VERSION "dbc-export 1 2026.26.6.5"

NS_ :

BS_:

BU_: ADSP APB APP APS APSB BB BMS CC CMP CMPD CP DAS DI DIF DIR DPB EPAS3P EPAS3S EPASTP EPASTS EPBL EPBR ESP EVSE FC GTW HCML HCMR HVP IBST ICR IDB LS OCS1P ODIN PARK PCS PCS2 PLG PM PMF PMR PNCD PTC RADC RCM RCM2 RCM3 RCU SCCM SCM SCS SDCR TAS TCU TCU2 TPMS TRCM UDS UI UIS UMC USM V2G VC VCBATT VCBATT0 VCBATT1 VCBATT2 VCCC VCFRONT VCFRONT1 VCFRONT2 VCLEFT VCRIGHT VCSEAT2L VCSEAT2R VCSEC VEH

BO_ 1000 EPBR_alertMatrix: 8 EPBR
 SG_ EPBR_matrixIndex M : 0|4@1+ (1,0) [0|15] "" Vector__XXX
 SG_ EPBR_a001_WatchdogReset m0 : 4|1@1+ (1,0) [0|1] "" Vector__XXX
 SG_ EPBR_a002_PowerLossReset m0 : 5|1@1+ (1,0) [0|1] "" Vector__XXX
 SG_ EPBR_a003_SWAssertion m0 : 6|1@1+ (1,0) [0|1] "" Vector__XXX
 SG_ EPBR_a005_CANTXError m0 : 8|1@1+ (1,0) [0|1] "" Vector__XXX
 SG_ EPBR_a006_CANTX_cyclicError m0 : 9|1@1+ (1,0) [0|1] "" Vector__XXX
 SG_ EPBR_a012_CPUReset m0 : 15|1@1+ (1,0) [0|1] "" Vector__XXX
 SG_ EPBR_a013_AlertManagerFault m0 : 16|1@1+ (1,0) [0|1] "" Vector__XXX
 SG_ EPBR_a015_NVMMError m0 : 18|1@1+ (1,0) [0|1] "" Vector__XXX
 SG_ EPBR_a016_NVMMRecordError m0 : 19|1@1+ (1,0) [0|1] "" Vector__XXX
 SG_ EPBR_a021_TaskSchedulerError m0 : 24|1@1+ (1,0) [0|1] "" Vector__XXX
 SG_ EPBR_a022_TaskInitError m0 : 25|1@1+ (1,0) [0|1] "" Vector__XXX
 SG_ EPBR_a029_CoreDump m0 : 32|1@1+ (1,0) [0|1] "" Vector__XXX
 SG_ EPBR_a030_ECULogUploadRequest m0 : 33|1@1+ (1,0) [0|1] "" Vector__XXX
 SG_ EPBR_a031_UDSActive m0 : 34|1@1+ (1,0) [0|1] "" Vector__XXX
 SG_ EPBR_a041_HighCPULoad m0 : 44|1@1+ (1,0) [0|1] "" Vector__XXX
 SG_ EPBR_a042_HighStackUsage m0 : 45|1@1+ (1,0) [0|1] "" Vector__XXX
 SG_ EPBR_a043_Task1msError m0 : 46|1@1+ (1,0) [0|1] "" Vector__XXX
 SG_ EPBR_a044_Task10msError m0 : 47|1@1+ (1,0) [0|1] "" Vector__XXX
 SG_ EPBR_a045_Task100msError m0 : 48|1@1+ (1,0) [0|1] "" Vector__XXX
 SG_ EPBR_a046_Task1000msError m0 : 49|1@1+ (1,0) [0|1] "" Vector__XXX
 SG_ EPBR_a057_HVP_MIA m0 : 60|1@1+ (1,0) [0|1] "" Vector__XXX
 SG_ EPBR_a058_inputRHighSyncDebug m0 : 61|1@1+ (1,0) [0|1] "" Vector__XXX
 SG_ EPBR_a059_inputResistanceHigh m0 : 62|1@1+ (1,0) [0|1] "" Vector__XXX
 SG_ EPBR_a060_engineeringBuild m0 : 63|1@1+ (1,0) [0|1] "" Vector__XXX
 SG_ EPBR_a061_XCPConnected m1 : 4|1@1+ (1,0) [0|1] "" Vector__XXX
 SG_ EPBR_a062_XCPWasConnected m1 : 5|1@1+ (1,0) [0|1] "" Vector__XXX
 SG_ EPBR_a063_SwitchFault m1 : 6|1@1+ (1,0) [0|1] "" Vector__XXX
 SG_ EPBR_a064_busSleepReqTimeout m1 : 7|1@1+ (1,0) [0|1] "" Vector__XXX
 SG_ EPBR_a081_APP_MIA m1 : 24|1@1+ (1,0) [0|1] "" Vector__XXX
 SG_ EPBR_a082_VCRIGHT_IPC_MIA m1 : 25|1@1+ (1,0) [0|1] "" Vector__XXX
 SG_ EPBR_a083_VCLEFT_IPC_MIA m1 : 26|1@1+ (1,0) [0|1] "" Vector__XXX
 SG_ EPBR_a084_TPMS_MIA m1 : 27|1@1+ (1,0) [0|1] "" Vector__XXX
 SG_ EPBR_a085_CCCM_MIA m1 : 28|1@1+ (1,0) [0|1] "" Vector__XXX
 SG_ EPBR_a086_VCBATT_MIA m1 : 29|1@1+ (1,0) [0|1] "" Vector__XXX
 SG_ EPBR_a087_DIREL_MIA m1 : 30|1@1+ (1,0) [0|1] "" Vector__XXX
 SG_ EPBR_a088_DIRER_MIA m1 : 31|1@1+ (1,0) [0|1] "" Vector__XXX
 SG_ EPBR_a089_IBST_MIA m1 : 32|1@1+ (1,0) [0|1] "" Vector__XXX
 SG_ EPBR_a090_APS_MIA m1 : 33|1@1+ (1,0) [0|1] "" Vector__XXX
 SG_ EPBR_a091_CMPD_MIA m1 : 34|1@1+ (1,0) [0|1] "" Vector__XXX
 SG_ EPBR_a092_VCSEATD_MIA m1 : 35|1@1+ (1,0) [0|1] "" Vector__XXX
 SG_ EPBR_a093_VCSEATP_MIA m1 : 36|1@1+ (1,0) [0|1] "" Vector__XXX
 SG_ EPBR_a094_EPAS3P_MIA m1 : 37|1@1+ (1,0) [0|1] "" Vector__XXX
 SG_ EPBR_a095_CHG_MIA m1 : 38|1@1+ (1,0) [0|1] "" Vector__XXX
 SG_ EPBR_a096_OCS1P_MIA m1 : 39|1@1+ (1,0) [0|1] "" Vector__XXX
 SG_ EPBR_a097_CMP_MIA m1 : 40|1@1+ (1,0) [0|1] "" Vector__XXX
 SG_ EPBR_a098_DIR_MIA m1 : 41|1@1+ (1,0) [0|1] "" Vector__XXX
 SG_ EPBR_a099_PARK_MIA m1 : 42|1@1+ (1,0) [0|1] "" Vector__XXX
 SG_ EPBR_a100_CANbus_MIA m1 : 43|1@1+ (1,0) [0|1] "" Vector__XXX
 SG_ EPBR_a101_PM_MIA m1 : 44|1@1+ (1,0) [0|1] "" Vector__XXX
 SG_ EPBR_a102_PTC_MIA m1 : 45|1@1+ (1,0) [0|1] "" Vector__XXX
 SG_ EPBR_a103_CP_MIA m1 : 46|1@1+ (1,0) [0|1] "" Vector__XXX
 SG_ EPBR_a104_DAS_MIA m1 : 47|1@1+ (1,0) [0|1] "" Vector__XXX
 SG_ EPBR_a105_TAS_MIA m1 : 48|1@1+ (1,0) [0|1] "" Vector__XXX
 SG_ EPBR_a106_PCS_MIA m1 : 49|1@1+ (1,0) [0|1] "" Vector__XXX
 SG_ EPBR_a107_BMS_MIA m1 : 50|1@1+ (1,0) [0|1] "" Vector__XXX
 SG_ EPBR_a108_DIF_MIA m1 : 51|1@1+ (1,0) [0|1] "" Vector__XXX
 SG_ EPBR_a109_RCM_MIA m1 : 52|1@1+ (1,0) [0|1] "" Vector__XXX
 SG_ EPBR_a110_GTW_MIA m1 : 53|1@1+ (1,0) [0|1] "" Vector__XXX
 SG_ EPBR_a111_EPBR_MIA m1 : 54|1@1+ (1,0) [0|1] "" Vector__XXX
 SG_ EPBR_a112_EPBL_MIA m1 : 55|1@1+ (1,0) [0|1] "" Vector__XXX
 SG_ EPBR_a113_UI_MIA m1 : 56|1@1+ (1,0) [0|1] "" Vector__XXX
 SG_ EPBR_a114_ESP_MIA m1 : 57|1@1+ (1,0) [0|1] "" Vector__XXX
 SG_ EPBR_a115_VCSEC_MIA m1 : 58|1@1+ (1,0) [0|1] "" Vector__XXX
 SG_ EPBR_a116_VCRIGHT_MIA m1 : 59|1@1+ (1,0) [0|1] "" Vector__XXX
 SG_ EPBR_a117_VCLEFT_MIA m1 : 60|1@1+ (1,0) [0|1] "" Vector__XXX
 SG_ EPBR_a118_VCFRONT_MIA m1 : 61|1@1+ (1,0) [0|1] "" Vector__XXX
 SG_ EPBR_a119_SCCM_MIA m1 : 62|1@1+ (1,0) [0|1] "" Vector__XXX
 SG_ EPBR_a120_DI_DRIVE_MIA m1 : 63|1@1+ (1,0) [0|1] "" Vector__XXX
 SG_ EPBR_a121_nDriveFault m2 : 4|1@1+ (1,0) [0|1] "" Vector__XXX
 SG_ EPBR_a122_Oc m2 : 5|1@1+ (1,0) [0|1] "" Vector__XXX
 SG_ EPBR_a123_Uc m2 : 6|1@1+ (1,0) [0|1] "" Vector__XXX
 SG_ EPBR_a124_calOutOfBounds m2 : 7|1@1+ (1,0) [0|1] "" Vector__XXX
 SG_ EPBR_a125_IdleVMismatch m2 : 8|1@1+ (1,0) [0|1] "" Vector__XXX
 SG_ EPBR_a126_MotorNVoltLow m2 : 9|1@1+ (1,0) [0|1] "" Vector__XXX
 SG_ EPBR_a127_MotorNVoltHigh m2 : 10|1@1+ (1,0) [0|1] "" Vector__XXX
 SG_ EPBR_a128_MotorPVoltHigh m2 : 11|1@1+ (1,0) [0|1] "" Vector__XXX
 SG_ EPBR_a129_ICR_MIA m2 : 12|1@1+ (1,0) [0|1] "" Vector__XXX
 SG_ EPBR_a130_BB_MIA m2 : 13|1@1+ (1,0) [0|1] "" Vector__XXX
 SG_ EPBR_a131_RCU_MIA m2 : 14|1@1+ (1,0) [0|1] "" Vector__XXX
 SG_ EPBR_a132_VCBATT1_MIA m2 : 15|1@1+ (1,0) [0|1] "" Vector__XXX
 SG_ EPBR_a133_VCBATT2_MIA m2 : 16|1@1+ (1,0) [0|1] "" Vector__XXX
 SG_ EPBR_a134_NvOv m2 : 17|1@1+ (1,0) [0|1] "" Vector__XXX
 SG_ EPBR_a135_NvUv m2 : 18|1@1+ (1,0) [0|1] "" Vector__XXX
 SG_ EPBR_a136_PvOv m2 : 19|1@1+ (1,0) [0|1] "" Vector__XXX
 SG_ EPBR_a137_PvUv m2 : 20|1@1+ (1,0) [0|1] "" Vector__XXX
 SG_ EPBR_a138_NvmDualFailure m2 : 21|1@1+ (1,0) [0|1] "" Vector__XXX
 SG_ EPBR_a139_NvmRedundancyLoss m2 : 22|1@1+ (1,0) [0|1] "" Vector__XXX
 SG_ EPBR_a140_NvmSlowWrite m2 : 23|1@1+ (1,0) [0|1] "" Vector__XXX
 SG_ EPBR_a141_invalidState m2 : 24|1@1+ (1,0) [0|1] "" Vector__XXX
 SG_ EPBR_a170_12vOv m2 : 53|1@1+ (1,0) [0|1] "" Vector__XXX
 SG_ EPBR_a171_12vUv m2 : 54|1@1+ (1,0) [0|1] "" Vector__XXX
 SG_ EPBR_a172_SPI_MIA m2 : 55|1@1+ (1,0) [0|1] "" Vector__XXX
 SG_ EPBR_a173_hiCurrentMissing m2 : 56|1@1+ (1,0) [0|1] "" Vector__XXX
 SG_ EPBR_a174_csmReleaseFailed m2 : 57|1@1+ (1,0) [0|1] "" Vector__XXX
 SG_ EPBR_a175_csmReleaseRetry m2 : 58|1@1+ (1,0) [0|1] "" Vector__XXX
 SG_ EPBR_a176_csmApplyFailed m2 : 59|1@1+ (1,0) [0|1] "" Vector__XXX
 SG_ EPBR_a177_csmApplyRetry m2 : 60|1@1+ (1,0) [0|1] "" Vector__XXX
 SG_ EPBR_a178_caliperStateUnknown m2 : 61|1@1+ (1,0) [0|1] "" Vector__XXX
 SG_ EPBR_a179_epbProblem m2 : 62|1@1+ (1,0) [0|1] "" Vector__XXX
 SG_ EPBR_a180_dynamicActive m2 : 63|1@1+ (1,0) [0|1] "" Vector__XXX
 SG_ EPBR_a181_TooSteepGradeToPark m3 : 4|1@1+ (1,0) [0|1] "" Vector__XXX
 SG_ EPBR_a182_OneEPBAppliedUnsecEnv m3 : 5|1@1+ (1,0) [0|1] "" Vector__XXX
 SG_ EPBR_a183_cdpNotAvailable m3 : 6|1@1+ (1,0) [0|1] "" Vector__XXX
 SG_ EPBR_a184_dynamicParkAbort m3 : 7|1@1+ (1,0) [0|1] "" Vector__XXX
 SG_ EPBR_a185_summonAborted m3 : 8|1@1+ (1,0) [0|1] "" Vector__XXX
 SG_ EPBR_a186_externalParkAbort m3 : 9|1@1+ (1,0) [0|1] "" Vector__XXX
 SG_ EPBR_a187_cdpDynamic m3 : 10|1@1+ (1,0) [0|1] "" Vector__XXX
 SG_ EPBR_a188_epbDynamic m3 : 11|1@1+ (1,0) [0|1] "" Vector__XXX
 SG_ EPBR_a189_epbDynamicParkCanceled m3 : 12|1@1+ (1,0) [0|1] "" Vector__XXX
 SG_ EPBR_a190_csmApplyDegraded m3 : 13|1@1+ (1,0) [0|1] "" Vector__XXX
 SG_ EPBR_a191_csmReleaseDegraded m3 : 14|1@1+ (1,0) [0|1] "" Vector__XXX
 SG_ EPBR_a195_parkForDriverIsLeaving m3 : 18|1@1+ (1,0) [0|1] "" Vector__XXX
 SG_ EPBR_a196_freeRollModeActive m3 : 19|1@1+ (1,0) [0|1] "" Vector__XXX
 SG_ EPBR_a197_freeRollModeAtSpeed m3 : 20|1@1+ (1,0) [0|1] "" Vector__XXX
 SG_ EPBR_a198_holdClampComplete m3 : 21|1@1+ (1,0) [0|1] "" Vector__XXX
 SG_ EPBR_a200_PmUnparkNotAllowed m3 : 23|1@1+ (1,0) [0|1] "" Vector__XXX
 SG_ EPBR_a202_remoteEpbConfigIncompa m3 : 25|1@1+ (1,0) [0|1] "" Vector__XXX
 SG_ EPBR_a203_hwBrakeTypeMismatch m3 : 26|1@1+ (1,0) [0|1] "" Vector__XXX
 SG_ EPBR_a210_parkForDriverIsLeaving m3 : 33|1@1+ (1,0) [0|1] "" Vector__XXX
 SG_ EPBR_a216_SPI_MIA_debugData1 m3 : 39|1@1+ (1,0) [0|1] "" Vector__XXX
 SG_ EPBR_a217_SPI_MIA_debugData2 m3 : 40|1@1+ (1,0) [0|1] "" Vector__XXX
 SG_ EPBR_a225_epbActiveDecel m3 : 48|1@1+ (1,0) [0|1] "" Vector__XXX
 SG_ EPBR_a241_diOutputLocked m4 : 4|1@1+ (1,0) [0|1] "" Vector__XXX
 SG_ EPBR_a242_hvOutputLocked m4 : 5|1@1+ (1,0) [0|1] "" Vector__XXX
 SG_ EPBR_a243_bdwUnavailable m4 : 6|1@1+ (1,0) [0|1] "" Vector__XXX
 SG_ EPBR_a244_WinchModeActive m4 : 7|1@1+ (1,0) [0|1] "" Vector__XXX
 SG_ EPBR_a245_serviceModeActive m4 : 8|1@1+ (1,0) [0|1] "" Vector__XXX
 SG_ EPBR_a246_idleFaultApply m4 : 9|1@1+ (1,0) [0|1] "" Vector__XXX
 SG_ EPBR_a247_csmDynamicApplyRetry m4 : 10|1@1+ (1,0) [0|1] "" Vector__XXX
 SG_ EPBR_a248_csmDynamicApplyFailed m4 : 11|1@1+ (1,0) [0|1] "" Vector__XXX
 SG_ EPBR_a249_idleFaultRelease m4 : 12|1@1+ (1,0) [0|1] "" Vector__XXX
 SG_ EPBR_a250_WinchModeCanceled m4 : 13|1@1+ (1,0) [0|1] "" Vector__XXX
 SG_ EPBR_a251_currentVarianceHigh m4 : 14|1@1+ (1,0) [0|1] "" Vector__XXX
 SG_ EPBR_a252_winchModePending m4 : 15|1@1+ (1,0) [0|1] "" Vector__XXX
 SG_ EPBR_a253_esmReleaseBlocked m4 : 16|1@1+ (1,0) [0|1] "" Vector__XXX
 SG_ EPBR_a254_showStalkParkButtonFau m4 : 17|1@1+ (1,0) [0|1] "" Vector__XXX
 SG_ EPBR_a256_epbSystemApply m4 : 19|1@1+ (1,0) [0|1] "" Vector__XXX
 SG_ EPBR_a261_winchModeWithoutSteeri m4 : 24|1@1+ (1,0) [0|1] "" Vector__XXX
 SG_ EPBR_a262_cannotPrepareWinchMode m4 : 25|1@1+ (1,0) [0|1] "" Vector__XXX
 SG_ EPBR_a263_epbRecoveryPark m4 : 26|1@1+ (1,0) [0|1] "" Vector__XXX
 SG_ EPBR_a264_winchModeDeactivated m4 : 27|1@1+ (1,0) [0|1] "" Vector__XXX
 SG_ EPBR_a272_vhclPwrStateMsmtch m4 : 35|1@1+ (1,0) [0|1] "" Vector__XXX
 SG_ EPBR_a300_leftRightConfusion m4 : 63|1@1+ (1,0) [0|1] "" Vector__XXX
 SG_ EPBR_a301_oocSpeedViolation m5 : 4|1@1+ (1,0) [0|1] "" Vector__XXX
 SG_ EPBR_a302_csmLongRelease m5 : 5|1@1+ (1,0) [0|1] "" Vector__XXX
 SG_ EPBR_a303_clampingOccuredEarly m5 : 6|1@1+ (1,0) [0|1] "" Vector__XXX
 SG_ EPBR_a304_rearSeatControllerEFus m5 : 7|1@1+ (1,0) [0|1] "" Vector__XXX
 SG_ EPBR_a305_premiumAmpEFuseTrip m5 : 8|1@1+ (1,0) [0|1] "" Vector__XXX
 SG_ EPBR_a330_parkForApIsLeaving m5 : 33|1@1+ (1,0) [0|1] "" Vector__XXX
 SG_ EPBR_a350_ensOutOfRange m5 : 53|1@1+ (1,0) [0|1] "" Vector__XXX
 SG_ EPBR_a352_audioCurrentSpikeData m5 : 55|1@1+ (1,0) [0|1] "" Vector__XXX
 SG_ EPBR_a353_missingSpeedUnableToPa m5 : 56|1@1+ (1,0) [0|1] "" Vector__XXX
 SG_ EPBR_a354_parkedForLowBrakeFluid m5 : 57|1@1+ (1,0) [0|1] "" Vector__XXX
 SG_ EPBR_a355_brakeHwAndEpbHwMismatc m5 : 58|1@1+ (1,0) [0|1] "" Vector__XXX
 SG_ EPBR_a356_parkingForStationaryDe m5 : 59|1@1+ (1,0) [0|1] "" Vector__XXX
 SG_ EPBR_a357_brakesTooHotForSlope m5 : 60|1@1+ (1,0) [0|1] "" Vector__XXX
 SG_ EPBR_a358_brakesTooHotForSlopeWi m5 : 61|1@1+ (1,0) [0|1] "" Vector__XXX
 SG_ EPBR_a359_seat2RControllerTrip m5 : 62|1@1+ (1,0) [0|1] "" Vector__XXX
 SG_ EPBR_a360_ibstBrakeSwitchInvalid m5 : 63|1@1+ (1,0) [0|1] "" Vector__XXX
 SG_ EPBR_a361_espBrakeSwitchInvalid m6 : 4|1@1+ (1,0) [0|1] "" Vector__XXX
 SG_ EPBR_a362_ibstPressedEspNotPress m6 : 5|1@1+ (1,0) [0|1] "" Vector__XXX
 SG_ EPBR_a363_ibstNotPressedEspPress m6 : 6|1@1+ (1,0) [0|1] "" Vector__XXX
 SG_ EPBR_a364_espMasterCylCompOverTh m6 : 7|1@1+ (1,0) [0|1] "" Vector__XXX
 SG_ EPBR_a365_TooSteepToParkWithTrai m6 : 8|1@1+ (1,0) [0|1] "" Vector__XXX
 SG_ EPBR_a366_TooSteepToParkWithTrai m6 : 9|1@1+ (1,0) [0|1] "" Vector__XXX
 SG_ EPBR_a370_imposterDetected m6 : 13|1@1+ (1,0) [0|1] "" Vector__XXX

BO_ 2024 EPBR_info: 8 EPBR
 SG_ EPBR_infoIndex M : 0|8@1+ (1,0) [0|255] "" Vector__XXX
 SG_ EPBR_infoBuildType m10 : 8|3@1+ (1,0) [0|7] "" Vector__XXX
 SG_ EPBR_infoBuildConfigId m10 : 16|16@1+ (1,0) [0|65535] "" Vector__XXX
 SG_ EPBR_infoHardwareId m10 : 32|16@1+ (1,0) [0|65535] "" Vector__XXX
 SG_ EPBR_infoComponentId m10 : 48|16@1+ (1,0) [0|65535] "" Vector__XXX
 SG_ EPBR_infoPcbaId m11 : 8|8@1+ (1,0) [0|255] "" Vector__XXX
 SG_ EPBR_infoAssemblyId m11 : 16|8@1+ (1,0) [0|254] "" Vector__XXX
 SG_ EPBR_infoUsageId m11 : 24|16@1+ (1,0) [0|65535] "" Vector__XXX
 SG_ EPBR_infoSubUsageId m11 : 40|16@1+ (1,0) [0|65535] "" Vector__XXX
 SG_ EPBR_infoAppCrc m13 : 8|32@1+ (1,0) [0|4294967295] "" Vector__XXX
 SG_ EPBR_infoAppGitHash m17 : 8|56@1+ (1,0) [0|7.20575940379e+16] "" Vector__XXX
 SG_ EPBR_infoBootGitHash m18 : 8|56@1+ (1,0) [0|7.20575940379e+16] "" Vector__XXX
 SG_ EPBR_infoPlatformType m19 : 8|8@1+ (1,0) [0|255] "" Vector__XXX
 SG_ EPBR_infoBootUdsProtoVersion m20 : 8|16@1+ (1,0) [0|65535] "" Vector__XXX
 SG_ EPBR_infoBootCrc m20 : 24|32@1+ (1,0) [0|4294967295] "" Vector__XXX

BO_ 552 EPBR_internalStatus: 8 EPBR
 SG_ EPBR_unitStatus : 0|5@1+ (1,0) [0|31] "" Vector__XXX
 SG_ EPBR_unitFaultStatus : 5|2@1+ (1,0) [0|3] "" Vector__XXX
 SG_ EPBR_summonState : 8|3@1+ (1,0) [0|7] "" Vector__XXX
 SG_ EPBR_disconnected : 11|1@1+ (1,0) [0|1] "" Vector__XXX
 SG_ EPBR_pistonTouchingRotor : 12|1@1+ (1,0) [0|1] "" Vector__XXX
 SG_ EPBR_csmFaultReason : 13|5@1+ (1,0) [0|31] "" Vector__XXX
 SG_ EPBR_esmOperationTrigger : 18|6@1+ (1,0) [0|63] "" Vector__XXX
 SG_ EPBR_summonFaultReason : 24|5@1+ (1,0) [0|31] "" Vector__XXX
 SG_ EPBR_localServiceModeActive : 29|1@1+ (1,0) [0|1] "" Vector__XXX
 SG_ EPBR_localCdpState : 30|2@1+ (1,0) [0|3] "" Vector__XXX
 SG_ EPBR_chimeRequestLocal : 33|3@1+ (1,0) [0|7] "" Vector__XXX
 SG_ EPBR_telltaleLocal : 39|3@1+ (1,0) [0|6] "" Vector__XXX
 SG_ EPBR_driverIsLeavingLocal : 42|1@1+ (1,0) [0|1] "" Vector__XXX
 SG_ EPBR_driverIsLeavingAnySpeedLoca : 43|1@1+ (1,0) [0|1] "" Vector__XXX
 SG_ EPBR_internalCDPRequest : 44|1@1+ (1,0) [0|1] "" Vector__XXX
 SG_ EPBR_esmSpeedClass : 45|3@1+ (1,0) [0|7] "" Vector__XXX
 SG_ EPBR_learnedEpbConfig : 48|4@1+ (1,0) [0|15] "" Vector__XXX
 SG_ EPBR_internalStatusCounter : 52|4@1+ (1,0) [0|15] "" Vector__XXX
 SG_ EPBR_internalStatusChecksum : 56|8@1+ (1,0) [0|255] "" Vector__XXX

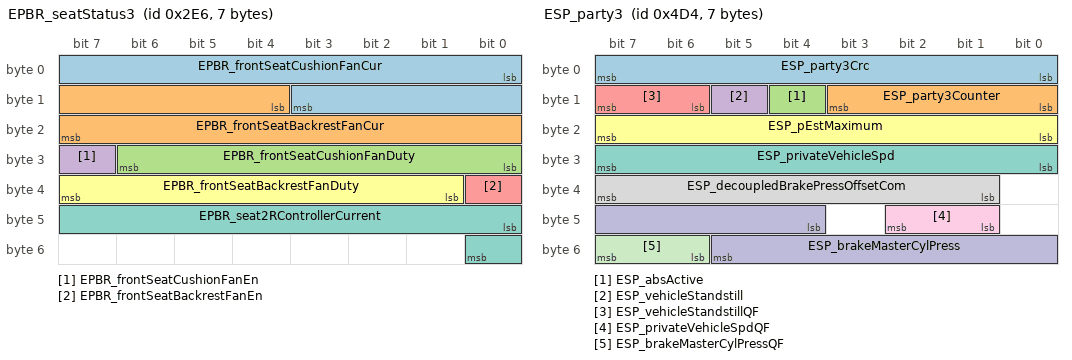
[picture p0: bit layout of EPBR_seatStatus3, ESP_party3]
BO_ 742 EPBR_seatStatus3: 7 EPBR
 SG_ EPBR_frontSeatCushionFanCur : 0|12@1+ (0.01,0) [0|40.95] "A" Vector__XXX
 SG_ EPBR_frontSeatBackrestFanCur : 12|12@1+ (0.01,0) [0|40.95] "A" Vector__XXX
 SG_ EPBR_frontSeatCushionFanDuty : 24|7@1+ (1,0) [0|100] "%" Vector__XXX
 SG_ EPBR_frontSeatCushionFanEn : 31|1@1+ (1,0) [0|1] "" Vector__XXX
 SG_ EPBR_frontSeatBackrestFanEn : 32|1@1+ (1,0) [0|1] "" Vector__XXX
 SG_ EPBR_frontSeatBackrestFanDuty : 33|7@1+ (1,0) [0|100] "%" Vector__XXX
 SG_ EPBR_seat2RControllerCurrent : 40|9@1+ (0.2,0) [0|102] "A" Vector__XXX

BO_ 744 EPBR_status: 8 EPBR
 SG_ EPBR_systemStatus : 0|4@1+ (1,0) [0|15] "" Vector__XXX
 SG_ EPBR_freeRollModeStatus : 4|2@1+ (1,0) [0|3] "" Vector__XXX
 SG_ EPBR_driverIsLeaving : 6|1@1+ (1,0) [0|1] "" Vector__XXX
 SG_ EPBR_driverIsLeavingAnySpeed : 7|1@1+ (1,0) [0|1] "" Vector__XXX
 SG_ EPBR_systemCdpAvailable : 8|1@1+ (1,0) [0|1] "" Vector__XXX
 SG_ EPBR_chimeRequest : 9|3@1+ (1,0) [0|7] "" Vector__XXX
 SG_ EPBR_telltale : 12|3@1+ (1,0) [0|6] "" Vector__XXX
 SG_ EPBR_audioCurrentSpikeDetected : 15|1@1+ (1,0) [0|1] "" Vector__XXX
 SG_ EPBR_redundantBrakingEnabled : 16|1@1+ (1,0) [0|1] "" Vector__XXX
 SG_ EPBR_summonEnabled : 17|1@1+ (1,0) [0|1] "" Vector__XXX
 SG_ EPBR_brakeLight : 18|1@1+ (1,0) [0|1] "" Vector__XXX
 SG_ EPBR_epbConfigMismatch : 19|1@1+ (1,0) [0|1] "" Vector__XXX
 SG_ EPBR_brakeConfirmedPressed : 20|1@1+ (1,0) [0|1] "" Vector__XXX
 SG_ EPBR_requestUserConfirmation : 21|1@1+ (1,0) [0|1] "" Vector__XXX
 SG_ EPBR_uiWinchModeMiscBlocking : 22|1@1+ (1,0) [0|1] "" Vector__XXX
 SG_ EPBR_winchModeActive : 23|1@1+ (1,0) [0|1] "" Vector__XXX
 SG_ EPBR_updateMode : 24|1@1+ (1,0) [0|1] "" Vector__XXX
 SG_ EPBR_winchModePermissive : 25|1@1+ (1,0) [0|1] "" Vector__XXX
 SG_ EPBR_winchModePending : 26|1@1+ (1,0) [0|1] "" Vector__XXX
 SG_ EPBR_cdpRequest : 27|1@1+ (1,0) [0|1] "" Vector__XXX
 SG_ EPBR_uiParkAvailable : 28|2@1+ (1,0) [0|3] "" Vector__XXX
 SG_ EPBR_brakeDiscWipeRequest : 30|2@1+ (1,0) [0|2] "" Vector__XXX
 SG_ EPBR_showUiGearShifter : 32|1@1+ (1,0) [0|1] "" Vector__XXX
 SG_ EPBR_uiWinchModeLvStatus : 33|2@1+ (1,0) [0|3] "" Vector__XXX
 SG_ EPBR_contactorCycleNotNeededForW : 35|1@1+ (1,0) [0|1] "" Vector__XXX
 SG_ EPBR_autonomyBehavior : 43|2@1+ (1,0) [0|3] "" Vector__XXX
 SG_ EPBR_showStalkFaultedOnUi : 45|1@1+ (1,0) [0|1] "" Vector__XXX
 SG_ EPBR_espPowerRequest : 46|1@1+ (1,0) [0|1] "" Vector__XXX
 SG_ EPBR_okToPark : 47|1@1+ (1,0) [0|1] "" Vector__XXX
 SG_ EPBR_hornRequest : 48|1@1+ (1,0) [0|1] "" Vector__XXX
 SG_ EPBR_winchModeAvailable : 49|1@1+ (1,0) [0|1] "" Vector__XXX
 SG_ EPBR_bothDisconnected : 50|1@1+ (1,0) [0|1] "" Vector__XXX
 SG_ EPBR_blockDrive : 51|1@1+ (1,0) [0|1] "" Vector__XXX
 SG_ EPBR_statusCounter : 52|4@1+ (1,0) [0|15] "" Vector__XXX
 SG_ EPBR_statusChecksum : 56|8@1+ (1,0) [0|255] "" Vector__XXX

BO_ 1575 EPBR_udsResponse: 8 EPBR
 SG_ EPBR_udsResponseData_H : 7|32@0+ (1,0) [0|4294967295] "" Vector__XXX
 SG_ EPBR_udsResponseData_L : 39|32@0+ (1,0) [0|4294967295] "" Vector__XXX

BO_ 981 ESP_alertMatrix: 8 ESP
 SG_ ESP_matrixIndex M : 0|4@1+ (1,0) [0|15] "" Vector__XXX
 SG_ ESP_a001_ecuGenericFault m0 : 4|1@1+ (1,0) [0|1] "" Vector__XXX
 SG_ ESP_a002_valvesGenericFault m0 : 5|1@1+ (1,0) [0|1] "" Vector__XXX
 SG_ ESP_a003_outletValvesFault m0 : 6|1@1+ (1,0) [0|1] "" Vector__XXX
 SG_ ESP_a004_inletValvesFault m0 : 7|1@1+ (1,0) [0|1] "" Vector__XXX
 SG_ ESP_a005_HSVValvesFault m0 : 8|1@1+ (1,0) [0|1] "" Vector__XXX
 SG_ ESP_a006_USVValvesFault m0 : 9|1@1+ (1,0) [0|1] "" Vector__XXX
 SG_ ESP_a007_pumpMotorFault m0 : 10|1@1+ (1,0) [0|1] "" Vector__XXX
 SG_ ESP_a008_pumpMotor12VsupplyLow m0 : 11|1@1+ (1,0) [0|1] "" Vector__XXX
 SG_ ESP_a009_12VHardUndervoltage m0 : 12|1@1+ (1,0) [0|1] "" Vector__XXX
 SG_ ESP_a010_12VUndervoltage m0 : 13|1@1+ (1,0) [0|1] "" Vector__XXX
 SG_ ESP_a011_12VSystemUndervoltage m0 : 14|1@1+ (1,0) [0|1] "" Vector__XXX
 SG_ ESP_a012_netUndervoltage m0 : 15|1@1+ (1,0) [0|1] "" Vector__XXX
 SG_ ESP_a013_valveRelayUndervoltage m0 : 16|1@1+ (1,0) [0|1] "" Vector__XXX
 SG_ ESP_a014_WSSSupplyUndervoltage m0 : 17|1@1+ (1,0) [0|1] "" Vector__XXX
 SG_ ESP_a015_12VSupplyOvervoltage m0 : 18|1@1+ (1,0) [0|1] "" Vector__XXX
 SG_ ESP_a016_12VSystemOvervoltage m0 : 19|1@1+ (1,0) [0|1] "" Vector__XXX
 SG_ ESP_a017_netOvervoltage m0 : 20|1@1+ (1,0) [0|1] "" Vector__XXX
 SG_ ESP_a018_WSSSignFrontAxle m0 : 21|1@1+ (1,0) [0|1] "" Vector__XXX
 SG_ ESP_a019_WSSSignRearAxle m0 : 22|1@1+ (1,0) [0|1] "" Vector__XXX
 SG_ ESP_a020_WSSGenericTempFault m0 : 23|1@1+ (1,0) [0|1] "" Vector__XXX
 SG_ ESP_a021_WSSGeneralVDiffFault m0 : 24|1@1+ (1,0) [0|1] "" Vector__XXX
 SG_ ESP_a022_WSSDirectionFault m0 : 25|1@1+ (1,0) [0|1] "" Vector__XXX
 SG_ ESP_a023_WSSSeveralSuspected m0 : 26|1@1+ (1,0) [0|1] "" Vector__XXX
 SG_ ESP_a024_WSSReverseCurrent m0 : 27|1@1+ (1,0) [0|1] "" Vector__XXX
 SG_ ESP_a025_FrLWSSOpenOrShortToGnd m0 : 28|1@1+ (1,0) [0|1] "" Vector__XXX
 SG_ ESP_a026_FrLWSSShortTo12V m0 : 29|1@1+ (1,0) [0|1] "" Vector__XXX
 SG_ ESP_a027_FrLWSSLineInterruption m0 : 30|1@1+ (1,0) [0|1] "" Vector__XXX
 SG_ ESP_a028_FrLWSSMaxSpeedExceeded m0 : 31|1@1+ (1,0) [0|1] "" Vector__XXX
 SG_ ESP_a029_FrLWSSTooManyPulses m0 : 32|1@1+ (1,0) [0|1] "" Vector__XXX
 SG_ ESP_a030_FrLWSSLostSignal m0 : 33|1@1+ (1,0) [0|1] "" Vector__XXX
 SG_ ESP_a031_FrLWSSNoPulsesDetected m0 : 34|1@1+ (1,0) [0|1] "" Vector__XXX
 SG_ ESP_a032_FrLWSSWrongSensorType m0 : 35|1@1+ (1,0) [0|1] "" Vector__XXX
 SG_ ESP_a033_FrLWSSSignalNoise m0 : 36|1@1+ (1,0) [0|1] "" Vector__XXX
 SG_ ESP_a034_FrLWSSVDiffFault m0 : 37|1@1+ (1,0) [0|1] "" Vector__XXX
 SG_ ESP_a035_FrLWSSDirectionFault m0 : 38|1@1+ (1,0) [0|1] "" Vector__XXX
 SG_ ESP_a036_FrLWSSLargeAirGap m0 : 39|1@1+ (1,0) [0|1] "" Vector__XXX
 SG_ ESP_a037_FrLWSSSupplyShortToGnd m0 : 40|1@1+ (1,0) [0|1] "" Vector__XXX
 SG_ ESP_a038_FrLWSSGeneralFault m0 : 41|1@1+ (1,0) [0|1] "" Vector__XXX
 SG_ ESP_a039_FrRWSSOpenOrShortToGnd m0 : 42|1@1+ (1,0) [0|1] "" Vector__XXX
 SG_ ESP_a040_FrRWSSShortTo12V m0 : 43|1@1+ (1,0) [0|1] "" Vector__XXX
 SG_ ESP_a041_FrRWSSLineInterruption m0 : 44|1@1+ (1,0) [0|1] "" Vector__XXX
 SG_ ESP_a042_FrRWSSMaxSpeedExceeded m0 : 45|1@1+ (1,0) [0|1] "" Vector__XXX
 SG_ ESP_a043_FrRWSSTooManyPulses m0 : 46|1@1+ (1,0) [0|1] "" Vector__XXX
 SG_ ESP_a044_FrRWSSLostSignal m0 : 47|1@1+ (1,0) [0|1] "" Vector__XXX
 SG_ ESP_a045_FrRWSSNoPulsesDetected m0 : 48|1@1+ (1,0) [0|1] "" Vector__XXX
 SG_ ESP_a046_FrRWSSWrongSensorType m0 : 49|1@1+ (1,0) [0|1] "" Vector__XXX
 SG_ ESP_a047_FrRWSSSignalNoise m0 : 50|1@1+ (1,0) [0|1] "" Vector__XXX
 SG_ ESP_a048_FrRWSSVDiffFault m0 : 51|1@1+ (1,0) [0|1] "" Vector__XXX
 SG_ ESP_a049_FrRWSSDirectionFault m0 : 52|1@1+ (1,0) [0|1] "" Vector__XXX
 SG_ ESP_a050_FrRWSSLargeAirGap m0 : 53|1@1+ (1,0) [0|1] "" Vector__XXX
 SG_ ESP_a051_FrRWSSSupplyShortToGnd m0 : 54|1@1+ (1,0) [0|1] "" Vector__XXX
 SG_ ESP_a052_FrRWSSGeneralFault m0 : 55|1@1+ (1,0) [0|1] "" Vector__XXX
 SG_ ESP_a053_ReLWSSOpenOrShortToGnd m0 : 56|1@1+ (1,0) [0|1] "" Vector__XXX
 SG_ ESP_a054_ReLWSSShortTo12V m0 : 57|1@1+ (1,0) [0|1] "" Vector__XXX
 SG_ ESP_a055_ReLWSSLineInterruption m0 : 58|1@1+ (1,0) [0|1] "" Vector__XXX
 SG_ ESP_a056_ReLWSSMaxSpeedExceeded m0 : 59|1@1+ (1,0) [0|1] "" Vector__XXX
 SG_ ESP_a057_ReLWSSTooManyPulses m0 : 60|1@1+ (1,0) [0|1] "" Vector__XXX
 SG_ ESP_a058_ReLWSSLostSignal m0 : 61|1@1+ (1,0) [0|1] "" Vector__XXX
 SG_ ESP_a059_ReLWSSNoPulsesDetected m0 : 62|1@1+ (1,0) [0|1] "" Vector__XXX
 SG_ ESP_a060_ReLWSSWrongSensorType m0 : 63|1@1+ (1,0) [0|1] "" Vector__XXX
 SG_ ESP_a061_ReLWSSSignalNoise m1 : 4|1@1+ (1,0) [0|1] "" Vector__XXX
 SG_ ESP_a062_ReLWSSVDiffFault m1 : 5|1@1+ (1,0) [0|1] "" Vector__XXX
 SG_ ESP_a063_ReLWSSDirectionFault m1 : 6|1@1+ (1,0) [0|1] "" Vector__XXX
 SG_ ESP_a064_ReLWSSLargeAirGap m1 : 7|1@1+ (1,0) [0|1] "" Vector__XXX
 SG_ ESP_a065_ReLWSSSupplyShortToGnd m1 : 8|1@1+ (1,0) [0|1] "" Vector__XXX
 SG_ ESP_a066_ReLWSSGeneralFault m1 : 9|1@1+ (1,0) [0|1] "" Vector__XXX
 SG_ ESP_a067_ReRWSSOpenOrShortToGnd m1 : 10|1@1+ (1,0) [0|1] "" Vector__XXX
 SG_ ESP_a068_ReRWSSShortTo12V m1 : 11|1@1+ (1,0) [0|1] "" Vector__XXX
 SG_ ESP_a069_ReRWSSLineInterruption m1 : 12|1@1+ (1,0) [0|1] "" Vector__XXX
 SG_ ESP_a070_ReRWSSMaxSpeedExceeded m1 : 13|1@1+ (1,0) [0|1] "" Vector__XXX
 SG_ ESP_a071_ReRWSSTooManyPulses m1 : 14|1@1+ (1,0) [0|1] "" Vector__XXX
 SG_ ESP_a072_ReRWSSLostSignal m1 : 15|1@1+ (1,0) [0|1] "" Vector__XXX
 SG_ ESP_a073_ReRWSSNoPulsesDetected m1 : 16|1@1+ (1,0) [0|1] "" Vector__XXX
 SG_ ESP_a074_ReRWSSWrongSensorType m1 : 17|1@1+ (1,0) [0|1] "" Vector__XXX
 SG_ ESP_a075_ReRWSSSignalNoise m1 : 18|1@1+ (1,0) [0|1] "" Vector__XXX
 SG_ ESP_a076_ReRWSSVDiffFault m1 : 19|1@1+ (1,0) [0|1] "" Vector__XXX
 SG_ ESP_a077_ReRWSSDirectionFault m1 : 20|1@1+ (1,0) [0|1] "" Vector__XXX
 SG_ ESP_a078_ReRWSSLargeAirGap m1 : 21|1@1+ (1,0) [0|1] "" Vector__XXX
 SG_ ESP_a079_ReRWSSSupplyShortToGnd m1 : 22|1@1+ (1,0) [0|1] "" Vector__XXX
 SG_ ESP_a080_ReRWSSGeneralFault m1 : 23|1@1+ (1,0) [0|1] "" Vector__XXX
 SG_ ESP_a081_PressureSensorShort m1 : 24|1@1+ (1,0) [0|1] "" Vector__XXX
 SG_ ESP_a082_PMCSensorOffsetHigh m1 : 25|1@1+ (1,0) [0|1] "" Vector__XXX
 SG_ ESP_a083_PMCSensorFault m1 : 26|1@1+ (1,0) [0|1] "" Vector__XXX
 SG_ ESP_a084_BrakeFluidReservoirLow m1 : 27|1@1+ (1,0) [0|1] "" Vector__XXX
 SG_ ESP_a085_BrakeSwitchStuckHigh m1 : 28|1@1+ (1,0) [0|1] "" Vector__XXX
 SG_ ESP_a086_BrakeSwitchImplausible1 m1 : 29|1@1+ (1,0) [0|1] "" Vector__XXX
 SG_ ESP_a087_BrakeSwitchImplausible3 m1 : 30|1@1+ (1,0) [0|1] "" Vector__XXX
 SG_ ESP_a088_absContinuousControl m1 : 31|1@1+ (1,0) [0|1] "" Vector__XXX
 SG_ ESP_a089_absNoPressureIncrease m1 : 32|1@1+ (1,0) [0|1] "" Vector__XXX
 SG_ ESP_a090_vdcContinuousControl m1 : 33|1@1+ (1,0) [0|1] "" Vector__XXX
 SG_ ESP_a091_CANUndervoltage m1 : 34|1@1+ (1,0) [0|1] "" Vector__XXX
 SG_ ESP_a092_CANOvervoltage m1 : 35|1@1+ (1,0) [0|1] "" Vector__XXX
 SG_ ESP_a093_partyBusOff m1 : 36|1@1+ (1,0) [0|1] "" Vector__XXX
 SG_ ESP_a094_partyBusPassive m1 : 37|1@1+ (1,0) [0|1] "" Vector__XXX
 SG_ ESP_a095_chassisBusOff m1 : 38|1@1+ (1,0) [0|1] "" Vector__XXX
 SG_ ESP_a096_chassisBusPassive m1 : 39|1@1+ (1,0) [0|1] "" Vector__XXX
 SG_ ESP_a097_tcsRefSpeedNotInit m1 : 40|1@1+ (1,0) [0|1] "" Vector__XXX
 SG_ ESP_a098_vdcRefSpeedNotInit m1 : 41|1@1+ (1,0) [0|1] "" Vector__XXX
 SG_ ESP_a099_brakeTempModelOverheat m1 : 42|1@1+ (1,0) [0|1] "" Vector__XXX
 SG_ ESP_a100_brakeTempModelDisabled m1 : 43|1@1+ (1,0) [0|1] "" Vector__XXX
 SG_ ESP_a101_ebdFault m1 : 44|1@1+ (1,0) [0|1] "" Vector__XXX
 SG_ ESP_a102_absFault m1 : 45|1@1+ (1,0) [0|1] "" Vector__XXX
 SG_ ESP_a103_stabilityControlFault m1 : 46|1@1+ (1,0) [0|1] "" Vector__XXX
 SG_ ESP_a104_hbcEnabled m1 : 47|1@1+ (1,0) [0|1] "" Vector__XXX
 SG_ ESP_a105_ebrFault m1 : 48|1@1+ (1,0) [0|1] "" Vector__XXX
 SG_ ESP_a106_vdcActuatorFault m1 : 49|1@1+ (1,0) [0|1] "" Vector__XXX
 SG_ ESP_a107_reserved107 m1 : 50|1@1+ (1,0) [0|1] "" Vector__XXX
 SG_ ESP_a108_reserved108 m1 : 51|1@1+ (1,0) [0|1] "" Vector__XXX
 SG_ ESP_a109_reserved109 m1 : 52|1@1+ (1,0) [0|1] "" Vector__XXX
 SG_ ESP_a110_rollerBenchActive m1 : 53|1@1+ (1,0) [0|1] "" Vector__XXX
 SG_ ESP_a111_absActive m1 : 54|1@1+ (1,0) [0|1] "" Vector__XXX
 SG_ ESP_a112_espActive m1 : 55|1@1+ (1,0) [0|1] "" Vector__XXX
 SG_ ESP_a113_btcActive m1 : 56|1@1+ (1,0) [0|1] "" Vector__XXX
 SG_ ESP_a114_tvdcActive m1 : 57|1@1+ (1,0) [0|1] "" Vector__XXX
 SG_ ESP_a115_ebdActive m1 : 58|1@1+ (1,0) [0|1] "" Vector__XXX
 SG_ ESP_a116_tsmActive m1 : 59|1@1+ (1,0) [0|1] "" Vector__XXX
 SG_ ESP_a117_hbaActive m1 : 60|1@1+ (1,0) [0|1] "" Vector__XXX
 SG_ ESP_a118_hfcActive m1 : 61|1@1+ (1,0) [0|1] "" Vector__XXX
 SG_ ESP_a119_hbbActive m1 : 62|1@1+ (1,0) [0|1] "" Vector__XXX
 SG_ ESP_a120_rmiActive m1 : 63|1@1+ (1,0) [0|1] "" Vector__XXX
 SG_ ESP_a121_regenTcActive m2 : 4|1@1+ (1,0) [0|1] "" Vector__XXX
 SG_ ESP_a122_bdwActive m2 : 5|1@1+ (1,0) [0|1] "" Vector__XXX
 SG_ ESP_a123_ebrActive m2 : 6|1@1+ (1,0) [0|1] "" Vector__XXX
 SG_ ESP_a124_ebrSkidActive m2 : 7|1@1+ (1,0) [0|1] "" Vector__XXX
 SG_ ESP_a125_reserved125 m2 : 8|1@1+ (1,0) [0|1] "" Vector__XXX
 SG_ ESP_a126_reserved126 m2 : 9|1@1+ (1,0) [0|1] "" Vector__XXX
 SG_ ESP_a127_reserved127 m2 : 10|1@1+ (1,0) [0|1] "" Vector__XXX
 SG_ ESP_a128_reserved128 m2 : 11|1@1+ (1,0) [0|1] "" Vector__XXX
 SG_ ESP_a129_reserved129 m2 : 12|1@1+ (1,0) [0|1] "" Vector__XXX
 SG_ ESP_a130_EPAS3PsysStatusTimeout m2 : 13|1@1+ (1,0) [0|1] "" Vector__XXX
 SG_ ESP_a131_EPAS3PsysStatusDLC m2 : 14|1@1+ (1,0) [0|1] "" Vector__XXX
 SG_ ESP_a132_EPAS3PsysStatusChecksum m2 : 15|1@1+ (1,0) [0|1] "" Vector__XXX
 SG_ ESP_a133_EPAS3PsysStatusCounter m2 : 16|1@1+ (1,0) [0|1] "" Vector__XXX
 SG_ ESP_a134_steeringAngleInvalid m2 : 17|1@1+ (1,0) [0|1] "" Vector__XXX
 SG_ ESP_a135_steeringAngleNoCenter m2 : 18|1@1+ (1,0) [0|1] "" Vector__XXX
 SG_ ESP_a136_steeringAngleFrozen m2 : 19|1@1+ (1,0) [0|1] "" Vector__XXX
 SG_ ESP_a137_steeringOffsetTooLarge m2 : 20|1@1+ (1,0) [0|1] "" Vector__XXX
 SG_ ESP_a138_steeringAngleImplaus m2 : 21|1@1+ (1,0) [0|1] "" Vector__XXX
 SG_ ESP_a139_steeringAngleWrongSign m2 : 22|1@1+ (1,0) [0|1] "" Vector__XXX
 SG_ ESP_a140_RCMInertial1Timeout m2 : 23|1@1+ (1,0) [0|1] "" Vector__XXX
 SG_ ESP_a141_RCMInertial1DLC m2 : 24|1@1+ (1,0) [0|1] "" Vector__XXX
 SG_ ESP_a142_RCMInertial1Checksum m2 : 25|1@1+ (1,0) [0|1] "" Vector__XXX
 SG_ ESP_a143_RCMInertial1Counter m2 : 26|1@1+ (1,0) [0|1] "" Vector__XXX
 SG_ ESP_a144_yawMaxLatency m2 : 27|1@1+ (1,0) [0|1] "" Vector__XXX
 SG_ ESP_a145_yawInitFault m2 : 28|1@1+ (1,0) [0|1] "" Vector__XXX
 SG_ ESP_a146_yawInvalidValue m2 : 29|1@1+ (1,0) [0|1] "" Vector__XXX
 SG_ ESP_a147_yawSensorNotAvailable m2 : 30|1@1+ (1,0) [0|1] "" Vector__XXX
 SG_ ESP_a148_yawSignalFault m2 : 31|1@1+ (1,0) [0|1] "" Vector__XXX
 SG_ ESP_a149_yawInvalidSign m2 : 32|1@1+ (1,0) [0|1] "" Vector__XXX
 SG_ ESP_a150_yawImplausible m2 : 33|1@1+ (1,0) [0|1] "" Vector__XXX
 SG_ ESP_a151_RCMInertial2Timeout m2 : 34|1@1+ (1,0) [0|1] "" Vector__XXX
 SG_ ESP_a152_RCMInertial2DLC m2 : 35|1@1+ (1,0) [0|1] "" Vector__XXX
 SG_ ESP_a153_RCMInertial2Checksum m2 : 36|1@1+ (1,0) [0|1] "" Vector__XXX
 SG_ ESP_a154_RCMInertial2Counter m2 : 37|1@1+ (1,0) [0|1] "" Vector__XXX
 SG_ ESP_a155_ayMaxLatency m2 : 38|1@1+ (1,0) [0|1] "" Vector__XXX
 SG_ ESP_a156_ayInitFault m2 : 39|1@1+ (1,0) [0|1] "" Vector__XXX
 SG_ ESP_a157_ayInvalidValue m2 : 40|1@1+ (1,0) [0|1] "" Vector__XXX
 SG_ ESP_a158_aySensorNotAvailable m2 : 41|1@1+ (1,0) [0|1] "" Vector__XXX
 SG_ ESP_a159_aySignalFault m2 : 42|1@1+ (1,0) [0|1] "" Vector__XXX
 SG_ ESP_a160_ayRangeExceeded m2 : 43|1@1+ (1,0) [0|1] "" Vector__XXX
 SG_ ESP_a161_ayOffsetExceeded m2 : 44|1@1+ (1,0) [0|1] "" Vector__XXX
 SG_ ESP_a162_ayImplausible m2 : 45|1@1+ (1,0) [0|1] "" Vector__XXX
 SG_ ESP_a163_axMaxLatency m2 : 46|1@1+ (1,0) [0|1] "" Vector__XXX
 SG_ ESP_a164_axInitFault m2 : 47|1@1+ (1,0) [0|1] "" Vector__XXX
 SG_ ESP_a165_axInvalidValue m2 : 48|1@1+ (1,0) [0|1] "" Vector__XXX
 SG_ ESP_a166_axSensorNotAvailable m2 : 49|1@1+ (1,0) [0|1] "" Vector__XXX
 SG_ ESP_a167_axSignalFault m2 : 50|1@1+ (1,0) [0|1] "" Vector__XXX
 SG_ ESP_a168_axRangeExceeded m2 : 51|1@1+ (1,0) [0|1] "" Vector__XXX
 SG_ ESP_a169_axOffsetExceeded m2 : 52|1@1+ (1,0) [0|1] "" Vector__XXX
 SG_ ESP_a170_axSignalFrozen m2 : 53|1@1+ (1,0) [0|1] "" Vector__XXX
 SG_ ESP_a171_axImplausible m2 : 54|1@1+ (1,0) [0|1] "" Vector__XXX
 SG_ ESP_a172_IBSTparty1Timeout m2 : 55|1@1+ (1,0) [0|1] "" Vector__XXX
 SG_ ESP_a173_IBSTparty1DLC m2 : 56|1@1+ (1,0) [0|1] "" Vector__XXX
 SG_ ESP_a174_IBSTparty1Checksum m2 : 57|1@1+ (1,0) [0|1] "" Vector__XXX
 SG_ ESP_a175_IBSTparty1Counter m2 : 58|1@1+ (1,0) [0|1] "" Vector__XXX
 SG_ ESP_a176_IBSTEBRNotAvailable m2 : 59|1@1+ (1,0) [0|1] "" Vector__XXX
 SG_ ESP_a177_IBSTOutputRodDrvInvalid m2 : 60|1@1+ (1,0) [0|1] "" Vector__XXX
 SG_ ESP_a178_IBSTOutputRodActInvalid m2 : 61|1@1+ (1,0) [0|1] "" Vector__XXX
 SG_ ESP_a179_IBSTparty2Timeout m2 : 62|1@1+ (1,0) [0|1] "" Vector__XXX
 SG_ ESP_a180_IBSTparty2Checksum m2 : 63|1@1+ (1,0) [0|1] "" Vector__XXX
 SG_ ESP_a181_IBSTparty2DLC m3 : 4|1@1+ (1,0) [0|1] "" Vector__XXX
 SG_ ESP_a182_IBSTparty2Counter m3 : 5|1@1+ (1,0) [0|1] "" Vector__XXX
 SG_ ESP_a183_IBSTStatusOff m3 : 6|1@1+ (1,0) [0|1] "" Vector__XXX
 SG_ ESP_a184_IBSTpRunoutInvalid m3 : 7|1@1+ (1,0) [0|1] "" Vector__XXX
 SG_ ESP_a185_IBSTFeedforwardBackup m3 : 8|1@1+ (1,0) [0|1] "" Vector__XXX
 SG_ ESP_a186_IBSTBrakeAppliedInvalid m3 : 9|1@1+ (1,0) [0|1] "" Vector__XXX
 SG_ ESP_a187_DIbtcRequestTimeout m3 : 10|1@1+ (1,0) [0|1] "" Vector__XXX
 SG_ ESP_a188_DIbtcRequestDLC m3 : 11|1@1+ (1,0) [0|1] "" Vector__XXX
 SG_ ESP_a189_DIbtcRequestChecksum m3 : 12|1@1+ (1,0) [0|1] "" Vector__XXX
 SG_ ESP_a190_DIbtcRequestCounter m3 : 13|1@1+ (1,0) [0|1] "" Vector__XXX
 SG_ ESP_a191_DIchassisControlTimeout m3 : 14|1@1+ (1,0) [0|1] "" Vector__XXX
 SG_ ESP_a192_DIchassisControlDLC m3 : 15|1@1+ (1,0) [0|1] "" Vector__XXX
 SG_ ESP_a193_DIchassisControlChecksu m3 : 16|1@1+ (1,0) [0|1] "" Vector__XXX
 SG_ ESP_a194_DIchassisControlCounter m3 : 17|1@1+ (1,0) [0|1] "" Vector__XXX
 SG_ ESP_a195_ptcStateInvalid m3 : 18|1@1+ (1,0) [0|1] "" Vector__XXX
 SG_ ESP_a196_DIsystemStatusTimeout m3 : 19|1@1+ (1,0) [0|1] "" Vector__XXX
 SG_ ESP_a197_DIsystemStatusDLC m3 : 20|1@1+ (1,0) [0|1] "" Vector__XXX
 SG_ ESP_a198_DIsystemStatusChecksum m3 : 21|1@1+ (1,0) [0|1] "" Vector__XXX
 SG_ ESP_a199_DIsystemStatusCounter m3 : 22|1@1+ (1,0) [0|1] "" Vector__XXX
 SG_ ESP_a200_reverseGearStuckHigh m3 : 23|1@1+ (1,0) [0|1] "" Vector__XXX
 SG_ ESP_a201_reverseGearStuckLow m3 : 24|1@1+ (1,0) [0|1] "" Vector__XXX
 SG_ ESP_a202_accelPedalInvalid m3 : 25|1@1+ (1,0) [0|1] "" Vector__XXX
 SG_ ESP_a203_DItorqueTimeout m3 : 26|1@1+ (1,0) [0|1] "" Vector__XXX
 SG_ ESP_a204_DItorqueDLC m3 : 27|1@1+ (1,0) [0|1] "" Vector__XXX
 SG_ ESP_a205_DItorqueChecksum m3 : 28|1@1+ (1,0) [0|1] "" Vector__XXX
 SG_ ESP_a206_DItorqueCounter m3 : 29|1@1+ (1,0) [0|1] "" Vector__XXX
 SG_ ESP_a207_DITorqueCommandInvalid m3 : 30|1@1+ (1,0) [0|1] "" Vector__XXX
 SG_ ESP_a208_DIRPMInvalid m3 : 31|1@1+ (1,0) [0|1] "" Vector__XXX
 SG_ ESP_a209_DITorqueActualInvalid m3 : 32|1@1+ (1,0) [0|1] "" Vector__XXX
 SG_ ESP_a210_DIStorqueTimeout m3 : 33|1@1+ (1,0) [0|1] "" Vector__XXX
 SG_ ESP_a211_DIStorqueDLC m3 : 34|1@1+ (1,0) [0|1] "" Vector__XXX
 SG_ ESP_a212_DIStorqueChecksum m3 : 35|1@1+ (1,0) [0|1] "" Vector__XXX
 SG_ ESP_a213_DIStorqueCounter m3 : 36|1@1+ (1,0) [0|1] "" Vector__XXX
 SG_ ESP_a214_DISTorqueCommandInvalid m3 : 37|1@1+ (1,0) [0|1] "" Vector__XXX
 SG_ ESP_a215_DISRPMInvalid m3 : 38|1@1+ (1,0) [0|1] "" Vector__XXX
 SG_ ESP_a216_DISTorqueActualInvalid m3 : 39|1@1+ (1,0) [0|1] "" Vector__XXX
 SG_ ESP_a217_DIvdcLeftTimeout m3 : 40|1@1+ (1,0) [0|1] "" Vector__XXX
 SG_ ESP_a218_DIvdcLeftDLC m3 : 41|1@1+ (1,0) [0|1] "" Vector__XXX
 SG_ ESP_a219_DIvdcLeftChecksum m3 : 42|1@1+ (1,0) [0|1] "" Vector__XXX
 SG_ ESP_a220_DIvdcLeftCounter m3 : 43|1@1+ (1,0) [0|1] "" Vector__XXX
 SG_ ESP_a221_DIvdcRightTimeout m3 : 44|1@1+ (1,0) [0|1] "" Vector__XXX
 SG_ ESP_a222_DIvdcRightDLC m3 : 45|1@1+ (1,0) [0|1] "" Vector__XXX
 SG_ ESP_a223_DIvdcRightChecksum m3 : 46|1@1+ (1,0) [0|1] "" Vector__XXX
 SG_ ESP_a224_DIvdcRightCounter m3 : 47|1@1+ (1,0) [0|1] "" Vector__XXX
 SG_ ESP_a225_configMismatch m3 : 48|1@1+ (1,0) [0|1] "" Vector__XXX
 SG_ ESP_a226_bdwRequestInvalid m3 : 49|1@1+ (1,0) [0|1] "" Vector__XXX
 SG_ ESP_a227_bdwRequestActiveInvalid m3 : 50|1@1+ (1,0) [0|1] "" Vector__XXX
 SG_ ESP_a228_GTWvinTimeout m3 : 51|1@1+ (1,0) [0|1] "" Vector__XXX
 SG_ ESP_a229_GTWvinDLC m3 : 52|1@1+ (1,0) [0|1] "" Vector__XXX
 SG_ ESP_a230_vinNotLearned m3 : 53|1@1+ (1,0) [0|1] "" Vector__XXX
 SG_ ESP_a231_storedVINMismatch m3 : 54|1@1+ (1,0) [0|1] "" Vector__XXX
 SG_ ESP_a232_PMstate2Timeout m3 : 55|1@1+ (1,0) [0|1] "" Vector__XXX
 SG_ ESP_a233_PMstate2Checksum m3 : 56|1@1+ (1,0) [0|1] "" Vector__XXX
 SG_ ESP_a234_PMstate2DLC m3 : 57|1@1+ (1,0) [0|1] "" Vector__XXX
 SG_ ESP_a235_PMstate2Counter m3 : 58|1@1+ (1,0) [0|1] "" Vector__XXX
 SG_ ESP_a236_ebrCommandStateInvalid m3 : 59|1@1+ (1,0) [0|1] "" Vector__XXX
 SG_ ESP_a237_vdcCommandStateInvalid m3 : 60|1@1+ (1,0) [0|1] "" Vector__XXX
 SG_ ESP_a238_UIodoTimeout m3 : 61|1@1+ (1,0) [0|1] "" Vector__XXX
 SG_ ESP_a239_UIodoDLC m3 : 62|1@1+ (1,0) [0|1] "" Vector__XXX
 SG_ ESP_a240_LVPowerStateTimeout m3 : 63|1@1+ (1,0) [0|1] "" Vector__XXX
 SG_ ESP_a241_LVPowerStateChecksum m4 : 4|1@1+ (1,0) [0|1] "" Vector__XXX
 SG_ ESP_a242_LVPowerStateDLC m4 : 5|1@1+ (1,0) [0|1] "" Vector__XXX
 SG_ ESP_a243_LVPowerStateCounter m4 : 6|1@1+ (1,0) [0|1] "" Vector__XXX
 SG_ ESP_a244_LVOffStateInvalid m4 : 7|1@1+ (1,0) [0|1] "" Vector__XXX
 SG_ ESP_a245_LVGoingDownStateInvalid m4 : 8|1@1+ (1,0) [0|1] "" Vector__XXX
 SG_ ESP_a246_VCFRONTsensorTimeout m4 : 9|1@1+ (1,0) [0|1] "" Vector__XXX
 SG_ ESP_a247_VCFRONTsensorDLC m4 : 10|1@1+ (1,0) [0|1] "" Vector__XXX
 SG_ ESP_a248_vdcBrkeTrqTarFrLInvalid m4 : 11|1@1+ (1,0) [0|1] "" Vector__XXX
 SG_ ESP_a249_vdcBrkeTrqTarFrRInvalid m4 : 12|1@1+ (1,0) [0|1] "" Vector__XXX
 SG_ ESP_a250_vdcBrkeTrqTarReLInvalid m4 : 13|1@1+ (1,0) [0|1] "" Vector__XXX
 SG_ ESP_a251_vdcBrkeTrqTarReRInvalid m4 : 14|1@1+ (1,0) [0|1] "" Vector__XXX
 SG_ ESP_a252_vdcWhlSlipLimFrLInvalid m4 : 15|1@1+ (1,0) [0|1] "" Vector__XXX
 SG_ ESP_a253_vdcWhlSlipLimFrRInvalid m4 : 16|1@1+ (1,0) [0|1] "" Vector__XXX
 SG_ ESP_a254_vdcWhlSlipLimReLInvalid m4 : 17|1@1+ (1,0) [0|1] "" Vector__XXX
 SG_ ESP_a255_vdcWhlSlipLimReRInvalid m4 : 18|1@1+ (1,0) [0|1] "" Vector__XXX
 SG_ ESP_a256_epbmStatusTimeout m4 : 19|1@1+ (1,0) [0|1] "" Vector__XXX
 SG_ ESP_a257_epbmStatusChecksum m4 : 20|1@1+ (1,0) [0|1] "" Vector__XXX
 SG_ ESP_a258_epbmStatusDLC m4 : 21|1@1+ (1,0) [0|1] "" Vector__XXX
 SG_ ESP_a259_epbmStatusCounter m4 : 22|1@1+ (1,0) [0|1] "" Vector__XXX
 SG_ ESP_a260_epblStatusTimeout m4 : 23|1@1+ (1,0) [0|1] "" Vector__XXX
 SG_ ESP_a261_epblStatusChecksum m4 : 24|1@1+ (1,0) [0|1] "" Vector__XXX
 SG_ ESP_a262_epblStatusDLC m4 : 25|1@1+ (1,0) [0|1] "" Vector__XXX
 SG_ ESP_a263_epblStatusCounter m4 : 26|1@1+ (1,0) [0|1] "" Vector__XXX
 SG_ ESP_a264_pumpSpeedLimitInvalid m4 : 27|1@1+ (1,0) [0|1] "" Vector__XXX
 SG_ ESP_a265_DIRELtorqueTimeout m4 : 28|1@1+ (1,0) [0|1] "" Vector__XXX
 SG_ ESP_a266_DIRELtorqueDLC m4 : 29|1@1+ (1,0) [0|1] "" Vector__XXX
 SG_ ESP_a267_DIRELtorqueChecksum m4 : 30|1@1+ (1,0) [0|1] "" Vector__XXX
 SG_ ESP_a268_DIRELtorqueCounter m4 : 31|1@1+ (1,0) [0|1] "" Vector__XXX
 SG_ ESP_a269_DIRELTorqueCommandInval m4 : 32|1@1+ (1,0) [0|1] "" Vector__XXX
 SG_ ESP_a270_DIRELRPMInvalid m4 : 33|1@1+ (1,0) [0|1] "" Vector__XXX
 SG_ ESP_a271_DIRELTorqueActualInvali m4 : 34|1@1+ (1,0) [0|1] "" Vector__XXX
 SG_ ESP_a272_DIRERtorqueTimeout m4 : 35|1@1+ (1,0) [0|1] "" Vector__XXX
 SG_ ESP_a273_DIRERtorqueDLC m4 : 36|1@1+ (1,0) [0|1] "" Vector__XXX
 SG_ ESP_a274_DIRERtorqueChecksum m4 : 37|1@1+ (1,0) [0|1] "" Vector__XXX
 SG_ ESP_a275_DIRERtorqueCounter m4 : 38|1@1+ (1,0) [0|1] "" Vector__XXX
 SG_ ESP_a276_DIRERTorqueCommandInval m4 : 39|1@1+ (1,0) [0|1] "" Vector__XXX
 SG_ ESP_a277_DIRERRPMInvalid m4 : 40|1@1+ (1,0) [0|1] "" Vector__XXX
 SG_ ESP_a278_DIRERTorqueActualInvali m4 : 41|1@1+ (1,0) [0|1] "" Vector__XXX
 SG_ ESP_a279_lifetimeManagementOverr m4 : 42|1@1+ (1,0) [0|1] "" Vector__XXX
 SG_ ESP_a280_trackModeABSEnabled m4 : 43|1@1+ (1,0) [0|1] "" Vector__XXX
 SG_ ESP_a281_trackModeABSdisabled m4 : 44|1@1+ (1,0) [0|1] "" Vector__XXX
 SG_ ESP_a282_trackModeABSRequestInva m4 : 45|1@1+ (1,0) [0|1] "" Vector__XXX
 SG_ ESP_a283_secondaryCollisionMitig m4 : 46|1@1+ (1,0) [0|1] "" Vector__XXX
 SG_ ESP_a284_scmRequestInvalidChecks m4 : 47|1@1+ (1,0) [0|1] "" Vector__XXX
 SG_ ESP_a285_scmRequestDLC m4 : 48|1@1+ (1,0) [0|1] "" Vector__XXX
 SG_ ESP_a286_hydroplaneDetected m4 : 49|1@1+ (1,0) [0|1] "" Vector__XXX
 SG_ ESP_a287_failedBrakeCircuitDetec m4 : 50|1@1+ (1,0) [0|1] "" Vector__XXX
 SG_ ESP_a288_leftBusOff m4 : 51|1@1+ (1,0) [0|1] "" Vector__XXX
 SG_ ESP_a289_leftBusPassive m4 : 52|1@1+ (1,0) [0|1] "" Vector__XXX
 SG_ ESP_a290_brakeBusOff m4 : 53|1@1+ (1,0) [0|1] "" Vector__XXX
 SG_ ESP_a291_brakeBusPassive m4 : 54|1@1+ (1,0) [0|1] "" Vector__XXX
 SG_ ESP_a292_PEPSstatusTimeout m4 : 55|1@1+ (1,0) [0|1] "" Vector__XXX
 SG_ ESP_a293_PEPSstatusDLC m4 : 56|1@1+ (1,0) [0|1] "" Vector__XXX
 SG_ ESP_a294_PEPSstatusChecksum m4 : 57|1@1+ (1,0) [0|1] "" Vector__XXX
 SG_ ESP_a295_PEPSstatusCounter m4 : 58|1@1+ (1,0) [0|1] "" Vector__XXX
 SG_ ESP_a296_roadWheelAngleHealthDeg m4 : 59|1@1+ (1,0) [0|1] "" Vector__XXX
 SG_ ESP_a297_roadWheelAngleHealthFau m4 : 60|1@1+ (1,0) [0|1] "" Vector__XXX
 SG_ ESP_a298_RSArearSteerStatusTimeo m4 : 61|1@1+ (1,0) [0|1] "" Vector__XXX
 SG_ ESP_a299_RSArearSteerStatusDLC m4 : 62|1@1+ (1,0) [0|1] "" Vector__XXX
 SG_ ESP_a300_RSArearSteerStatusCheck m4 : 63|1@1+ (1,0) [0|1] "" Vector__XXX
 SG_ ESP_a301_PEPSstatusCounter m5 : 4|1@1+ (1,0) [0|1] "" Vector__XXX
 SG_ ESP_a302_rearRoadWheelAngleHealt m5 : 5|1@1+ (1,0) [0|1] "" Vector__XXX
 SG_ ESP_a303_rearRoadWheelAngleHealt m5 : 6|1@1+ (1,0) [0|1] "" Vector__XXX
 SG_ ESP_a304_rearVCLVPowerStateTimeo m5 : 7|1@1+ (1,0) [0|1] "" Vector__XXX
 SG_ ESP_a305_rearVCLVPowerStateDLC m5 : 8|1@1+ (1,0) [0|1] "" Vector__XXX
 SG_ ESP_a306_rearVCLVPowerStateCheck m5 : 9|1@1+ (1,0) [0|1] "" Vector__XXX
 SG_ ESP_a307_rearVCLVPowerStateCount m5 : 10|1@1+ (1,0) [0|1] "" Vector__XXX
 SG_ ESP_a308_evacFillNotComplete m5 : 11|1@1+ (1,0) [0|1] "" Vector__XXX
 SG_ ESP_a309_factoryModeActive m5 : 12|1@1+ (1,0) [0|1] "" Vector__XXX
 SG_ ESP_a310_brakeLatencyReductionAc m5 : 13|1@1+ (1,0) [0|1] "" Vector__XXX
 SG_ ESP_a311_aesActive m5 : 14|1@1+ (1,0) [0|1] "" Vector__XXX
 SG_ ESP_a312_undefinedAlertDetected m5 : 15|1@1+ (1,0) [0|1] "" Vector__XXX
 SG_ ESP_a313_cdpRequestStateInvalid m5 : 16|1@1+ (1,0) [0|1] "" Vector__XXX
 SG_ ESP_a314_aesFault m5 : 17|1@1+ (1,0) [0|1] "" Vector__XXX
 SG_ ESP_a315_EMCBackup11Timeout m5 : 18|1@1+ (1,0) [0|1] "" Vector__XXX
 SG_ ESP_a316_EMCBackup11DLC m5 : 19|1@1+ (1,0) [0|1] "" Vector__XXX
 SG_ ESP_a317_EMCBackup11Checksum m5 : 20|1@1+ (1,0) [0|1] "" Vector__XXX
 SG_ ESP_a318_EMCBackup11Counter m5 : 21|1@1+ (1,0) [0|1] "" Vector__XXX
 SG_ ESP_a319_AES_BackupActuatorActiv m5 : 22|1@1+ (1,0) [0|1] "" Vector__XXX
 SG_ ESP_a320_DPB_actuator1Counter m5 : 23|1@1+ (1,0) [0|1] "" Vector__XXX
 SG_ ESP_a321_DPB_actuator1Checksum m5 : 24|1@1+ (1,0) [0|1] "" Vector__XXX
 SG_ ESP_a322_DPB_actuator1DLC m5 : 25|1@1+ (1,0) [0|1] "" Vector__XXX
 SG_ ESP_a323_DPB_actuator1Timeout m5 : 26|1@1+ (1,0) [0|1] "" Vector__XXX
 SG_ ESP_a324_DPB_actuator2Counter m5 : 27|1@1+ (1,0) [0|1] "" Vector__XXX
 SG_ ESP_a325_DPB_actuator2Checksum m5 : 28|1@1+ (1,0) [0|1] "" Vector__XXX
 SG_ ESP_a326_DPB_actuator2DLC m5 : 29|1@1+ (1,0) [0|1] "" Vector__XXX
 SG_ ESP_a327_DPB_actuator2Timeout m5 : 30|1@1+ (1,0) [0|1] "" Vector__XXX
 SG_ ESP_a328_DPB_actuator3Counter m5 : 31|1@1+ (1,0) [0|1] "" Vector__XXX
 SG_ ESP_a329_DPB_actuator3Checksum m5 : 32|1@1+ (1,0) [0|1] "" Vector__XXX
 SG_ ESP_a330_DPB_actuator3DLC m5 : 33|1@1+ (1,0) [0|1] "" Vector__XXX
 SG_ ESP_a331_DPB_actuator3Timeout m5 : 34|1@1+ (1,0) [0|1] "" Vector__XXX
 SG_ ESP_a332_PressureSensorValHigh m5 : 35|1@1+ (1,0) [0|1] "" Vector__XXX
 SG_ ESP_a333_ActCircuitNoPressure m5 : 36|1@1+ (1,0) [0|1] "" Vector__XXX
 SG_ ESP_a334_BrakePedalAppliedInvali m5 : 37|1@1+ (1,0) [0|1] "" Vector__XXX
 SG_ ESP_a335_LdmFxTarBrakeActInvalid m5 : 38|1@1+ (1,0) [0|1] "" Vector__XXX
 SG_ ESP_a336_FxTargetDriverInvalid m5 : 39|1@1+ (1,0) [0|1] "" Vector__XXX
 SG_ ESP_a337_pReductionPotentialInva m5 : 40|1@1+ (1,0) [0|1] "" Vector__XXX
 SG_ ESP_a338_pRunoutInvalid m5 : 41|1@1+ (1,0) [0|1] "" Vector__XXX
 SG_ ESP_a339_sInputRodInvalid m5 : 42|1@1+ (1,0) [0|1] "" Vector__XXX
 SG_ ESP_a340_RollerBenchMisuse m5 : 43|1@1+ (1,0) [0|1] "" Vector__XXX
 SG_ ESP_a341_EnhancedPressureBuildAc m5 : 44|1@1+ (1,0) [0|1] "" Vector__XXX
 SG_ ESP_a342_EnhancedPressureBuildNo m5 : 45|1@1+ (1,0) [0|1] "" Vector__XXX
 SG_ ESP_a343_EnhancedPressureBuildLt m5 : 46|1@1+ (1,0) [0|1] "" Vector__XXX
 SG_ ESP_a344_DIbrakeCommandCounter m5 : 47|1@1+ (1,0) [0|1] "" Vector__XXX
 SG_ ESP_a345_DIbrakeCommandChecksum m5 : 48|1@1+ (1,0) [0|1] "" Vector__XXX
 SG_ ESP_a346_DIbrakeCommandDLC m5 : 49|1@1+ (1,0) [0|1] "" Vector__XXX
 SG_ ESP_a347_DIbrakeCommandTimeout m5 : 50|1@1+ (1,0) [0|1] "" Vector__XXX
 SG_ ESP_a348_brakeCmdStateInvalid m5 : 51|1@1+ (1,0) [0|1] "" Vector__XXX
 SG_ ESP_a349_ForceLampToRed m5 : 52|1@1+ (1,0) [0|1] "" Vector__XXX
 SG_ ESP_a350_ActuatorOff m5 : 53|1@1+ (1,0) [0|1] "" Vector__XXX
 SG_ ESP_a351_ActuatorYellowLampReque m5 : 54|1@1+ (1,0) [0|1] "" Vector__XXX
 SG_ ESP_a352_ActuatorLDMFailure m5 : 55|1@1+ (1,0) [0|1] "" Vector__XXX
 SG_ ESP_a353_PressureSensorImplausHi m5 : 56|1@1+ (1,0) [0|1] "" Vector__XXX
 SG_ ESP_a354_HBCRequestInvalid m5 : 57|1@1+ (1,0) [0|1] "" Vector__XXX
 SG_ ESP_a355_RecuStatusActInvalid m5 : 58|1@1+ (1,0) [0|1] "" Vector__XXX
 SG_ ESP_a356_DIFAxleTorqueInvalid m5 : 59|1@1+ (1,0) [0|1] "" Vector__XXX
 SG_ ESP_a357_DIRAxleTorqueInvalid m5 : 60|1@1+ (1,0) [0|1] "" Vector__XXX
 SG_ ESP_a358_externalActuatorFallbac m5 : 61|1@1+ (1,0) [0|1] "" Vector__XXX
 SG_ ESP_a359_externalActuatorNoExtRe m5 : 62|1@1+ (1,0) [0|1] "" Vector__XXX
 SG_ ESP_a360_BBbrakeActuationTimeout m5 : 63|1@1+ (1,0) [0|1] "" Vector__XXX
 SG_ ESP_a361_BBbrakeActuationDLC m6 : 4|1@1+ (1,0) [0|1] "" Vector__XXX
 SG_ ESP_a362_BBbrakeActuationChecksu m6 : 5|1@1+ (1,0) [0|1] "" Vector__XXX
 SG_ ESP_a363_BBbrakeActuationCounter m6 : 6|1@1+ (1,0) [0|1] "" Vector__XXX
 SG_ ESP_a364_DIgearInvalid m6 : 7|1@1+ (1,0) [0|1] "" Vector__XXX
 SG_ ESP_a365_TCSInputQualityTooLow m6 : 8|1@1+ (1,0) [0|1] "" Vector__XXX
 SG_ ESP_a366_ActuatorBlendingModeReq m6 : 9|1@1+ (1,0) [0|1] "" Vector__XXX
 SG_ ESP_a367_CBDS_fillBufferThreshol m6 : 10|1@1+ (1,0) [0|1] "" Vector__XXX
 SG_ ESP_a368_CBDS_fmeInternalEvent m6 : 11|1@1+ (1,0) [0|1] "" Vector__XXX
 SG_ ESP_a369_LargeLeakageDetectedByD m6 : 12|1@1+ (1,0) [0|1] "" Vector__XXX
 SG_ ESP_a370_DPB_actuator4Timeout m6 : 13|1@1+ (1,0) [0|1] "" Vector__XXX
 SG_ ESP_a371_DPB_actuator4DLC m6 : 14|1@1+ (1,0) [0|1] "" Vector__XXX
 SG_ ESP_a372_DPB_actuator4Checksum m6 : 15|1@1+ (1,0) [0|1] "" Vector__XXX
 SG_ ESP_a373_DPB_actuator4Counter m6 : 16|1@1+ (1,0) [0|1] "" Vector__XXX
 SG_ ESP_a374_StatInvalid_DI_FullSNA m6 : 17|1@1+ (1,0) [0|1] "" Vector__XXX
 SG_ ESP_a375_PM_locStateCounter m6 : 18|1@1+ (1,0) [0|1] "" Vector__XXX
 SG_ ESP_a376_PM_locStateChecksum m6 : 19|1@1+ (1,0) [0|1] "" Vector__XXX
 SG_ ESP_a377_PM_locStateDLC m6 : 20|1@1+ (1,0) [0|1] "" Vector__XXX
 SG_ ESP_a378_PM_locStateTimeout m6 : 21|1@1+ (1,0) [0|1] "" Vector__XXX
 SG_ ESP_a379_DASredundantBrakingCont m6 : 22|1@1+ (1,0) [0|1] "" Vector__XXX
 SG_ ESP_a380_DASredundantBrakingCont m6 : 23|1@1+ (1,0) [0|1] "" Vector__XXX
 SG_ ESP_a381_DASredundantBrakingCont m6 : 24|1@1+ (1,0) [0|1] "" Vector__XXX
 SG_ ESP_a382_DASredundantBrakingCont m6 : 25|1@1+ (1,0) [0|1] "" Vector__XXX
 SG_ ESP_a383_DASredundantBrakingCont m6 : 26|1@1+ (1,0) [0|1] "" Vector__XXX
 SG_ ESP_a384_DASredundantBrakingCont m6 : 27|1@1+ (1,0) [0|1] "" Vector__XXX
 SG_ ESP_a385_DASredundantBrakingCont m6 : 28|1@1+ (1,0) [0|1] "" Vector__XXX
 SG_ ESP_a386_DASredundantBrakingCont m6 : 29|1@1+ (1,0) [0|1] "" Vector__XXX
 SG_ ESP_a387_DIlocStatus2Checksum m6 : 30|1@1+ (1,0) [0|1] "" Vector__XXX
 SG_ ESP_a388_DIlocStatus2Counter m6 : 31|1@1+ (1,0) [0|1] "" Vector__XXX
 SG_ ESP_a389_DIlocStatus2DLC m6 : 32|1@1+ (1,0) [0|1] "" Vector__XXX
 SG_ ESP_a390_DIlocStatus2Timeout m6 : 33|1@1+ (1,0) [0|1] "" Vector__XXX
 SG_ ESP_a391_standaloneEBRActive m6 : 34|1@1+ (1,0) [0|1] "" Vector__XXX
 SG_ ESP_a392_driverlessArmingUnavail m6 : 35|1@1+ (1,0) [0|1] "" Vector__XXX
 SG_ ESP_a393_EMCBackup21Checksum m6 : 36|1@1+ (1,0) [0|1] "" Vector__XXX
 SG_ ESP_a394_EMCBackup21Counter m6 : 37|1@1+ (1,0) [0|1] "" Vector__XXX
 SG_ ESP_a395_EMCBackup21DLC m6 : 38|1@1+ (1,0) [0|1] "" Vector__XXX
 SG_ ESP_a396_EMCBackup21Timeout m6 : 39|1@1+ (1,0) [0|1] "" Vector__XXX
 SG_ ESP_a397_epbrStatusTimeout m6 : 40|1@1+ (1,0) [0|1] "" Vector__XXX
 SG_ ESP_a398_epbrStatusChecksum m6 : 41|1@1+ (1,0) [0|1] "" Vector__XXX
 SG_ ESP_a399_epbrStatusDLC m6 : 42|1@1+ (1,0) [0|1] "" Vector__XXX
 SG_ ESP_a400_epbrStatusCounter m6 : 43|1@1+ (1,0) [0|1] "" Vector__XXX
 SG_ ESP_a401_bsmCircuitFailure m6 : 44|1@1+ (1,0) [0|1] "" Vector__XXX
 SG_ ESP_a402_bsmPtsPlausToPsTooHigh m6 : 45|1@1+ (1,0) [0|1] "" Vector__XXX
 SG_ ESP_a403_batMotorVoltage m6 : 46|1@1+ (1,0) [0|1] "" Vector__XXX
 SG_ ESP_a404_batPressureCircuit1 m6 : 47|1@1+ (1,0) [0|1] "" Vector__XXX
 SG_ ESP_a405_batPressureCircuit2 m6 : 48|1@1+ (1,0) [0|1] "" Vector__XXX
 SG_ ESP_a406_DIespActuatorTestTimeou m6 : 49|1@1+ (1,0) [0|1] "" Vector__XXX
 SG_ ESP_a407_DIespActuatorTestChecks m6 : 50|1@1+ (1,0) [0|1] "" Vector__XXX
 SG_ ESP_a408_DIespActuatorTestDLC m6 : 51|1@1+ (1,0) [0|1] "" Vector__XXX
 SG_ ESP_a409_DIespActuatorTestCounte m6 : 52|1@1+ (1,0) [0|1] "" Vector__XXX

BO_ 808 ESP_info: 8 ESP
 SG_ ESP_infoIndex M : 0|8@1+ (1,0) [0|255] "" Vector__XXX
 SG_ ESP_infoBuildType m10 : 8|8@1+ (1,0) [0|255] "" Vector__XXX
 SG_ ESP_vehFlashMode m10 : 24|1@1+ (1,0) [0|1] "" Vector__XXX
 SG_ ESP_infoComponentID m10 : 48|16@1+ (1,0) [0|65535] "" Vector__XXX
 SG_ ESP_infoPcbaID m11 : 16|8@1+ (1,0) [0|255] "" Vector__XXX
 SG_ ESP_infoAssemblyID m11 : 24|8@1+ (1,0) [0|255] "" Vector__XXX
 SG_ ESP_infoUsageID m11 : 32|16@1+ (1,0) [0|65535] "" Vector__XXX
 SG_ ESP_infoSubUsageID m11 : 48|16@1+ (1,0) [0|65535] "" Vector__XXX
 SG_ ESP_infoApplicationCRC m13 : 39|32@0+ (1,0) [0|4294967295] "" Vector__XXX
 SG_ ESP_infoVehicleVariant m16 : 16|8@1+ (1,0) [0|255] "" Vector__XXX
 SG_ ESP_infoSubcomponent1 m16 : 32|32@1+ (1,0) [0|4294967295] "" Vector__XXX
 SG_ ESP_infoBootUdsProtoVersion m20 : 8|8@1+ (1,0) [0|255] "" Vector__XXX
 SG_ ESP_infoBootloaderCRC m20 : 32|32@1+ (1,0) [0|4294967295] "" Vector__XXX
 SG_ ESP_infoVariantCRC m22 : 39|32@0+ (1,0) [0|4294967295] "" Vector__XXX

BO_ 1236 ESP_party3: 7 ESP
 SG_ ESP_party3Crc : 0|8@1+ (1,0) [0|255] "" Vector__XXX
 SG_ ESP_party3Counter : 8|4@1+ (1,0) [0|15] "" Vector__XXX
 SG_ ESP_absActive : 12|1@1+ (1,0) [0|1] "" Vector__XXX
 SG_ ESP_vehicleStandstill : 13|1@1+ (1,0) [0|1] "" Vector__XXX
 SG_ ESP_vehicleStandstillQF : 14|2@1+ (1,0) [0|3] "" Vector__XXX
 SG_ ESP_pEstMaximum : 16|8@1+ (1,0) [0|255] "bar" Vector__XXX
 SG_ ESP_privateVehicleSpd : 24|8@1+ (0.4,0) [0|102] "m/s" Vector__XXX
 SG_ ESP_decoupledBrakePressOffsetCom : 33|7@1+ (0.25,-16) [-16|15.5] "bar" Vector__XXX
 SG_ ESP_privateVehicleSpdQF : 41|2@1+ (1,0) [0|3] "" Vector__XXX
 SG_ ESP_brakeMasterCylPress : 44|10@1+ (0.3,-30) [-30|276.6] "bar" Vector__XXX
 SG_ ESP_brakeMasterCylPressQF : 54|2@1+ (1,0) [0|3] "" Vector__XXX

BO_ 325 ESP_status: 8 ESP
 SG_ ESP_statusChecksum : 0|8@1+ (1,0) [0|255] "" Vector__XXX
 SG_ ESP_statusCounter : 8|4@1+ (1,0) [0|15] "" Vector__XXX
 SG_ ESP_espModeActive : 12|2@1+ (1,0) [0|3] "" Vector__XXX
 SG_ ESP_stabilityControlSts2 : 14|2@1+ (1,0) [0|3] "" Vector__XXX
 SG_ ESP_ebdFaultLamp : 16|1@1+ (1,0) [0|1] "" Vector__XXX
 SG_ ESP_absFaultLamp : 17|1@1+ (1,0) [0|1] "" Vector__XXX
 SG_ ESP_espFaultLamp : 18|1@1+ (1,0) [0|1] "" Vector__XXX
 SG_ ESP_hydraulicBoostEnabled : 19|1@1+ (1,0) [0|1] "" Vector__XXX
 SG_ ESP_espLampFlash : 20|1@1+ (1,0) [0|1] "" Vector__XXX
 SG_ ESP_brakeLamp : 21|1@1+ (1,0) [0|1] "" Vector__XXX
 SG_ ESP_absBrakeEvent2 : 22|2@1+ (1,0) [0|3] "" Vector__XXX
 SG_ ESP_longitudinalAccelQF : 24|1@1+ (1,0) [0|1] "" Vector__XXX
 SG_ ESP_lateralAccelQF : 25|1@1+ (1,0) [0|1] "" Vector__XXX
 SG_ ESP_yawRateQF : 26|1@1+ (1,0) [0|1] "" Vector__XXX
 SG_ ESP_steeringAngleQF : 27|1@1+ (1,0) [0|1] "" Vector__XXX
 SG_ ESP_brakeDiscWipingActive : 28|1@1+ (1,0) [0|1] "" Vector__XXX
 SG_ ESP_driverBrakeApply : 29|2@1+ (1,0) [0|2] "" Vector__XXX
 SG_ ESP_brakeApply : 31|1@1+ (1,0) [0|1] "" Vector__XXX
 SG_ ESP_aesPrimaryActuatorStatus : 32|2@1+ (1,0) [0|3] "" Vector__XXX
 SG_ ESP_cdpStatus : 34|2@1+ (1,0) [0|3] "" Vector__XXX
 SG_ ESP_ptcTargetState : 36|2@1+ (1,0) [0|2] "" Vector__XXX
 SG_ ESP_btcTargetState : 38|2@1+ (1,0) [0|2] "" Vector__XXX
 SG_ ESP_decoupledBrakePressEst : 40|8@1+ (1,-30) [-30|224] "bar" Vector__XXX
 SG_ ESP_ebrStandstillSkid : 48|1@1+ (1,0) [0|1] "" Vector__XXX
 SG_ ESP_ebrStatus : 49|2@1+ (1,0) [0|3] "" Vector__XXX
 SG_ ESP_brakeTorqueTarget : 51|13@1+ (3,0) [0|24573] "Nm" Vector__XXX

BO_ 1621 ESP_udsResponse: 8 ESP
 SG_ ESP_udsResponseData : 7|64@0+ (1,0) [0|1.84467440737e+19] "" Vector__XXX

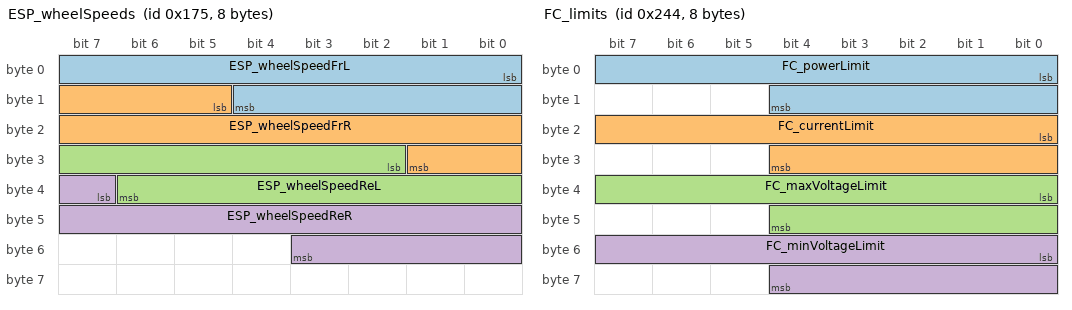
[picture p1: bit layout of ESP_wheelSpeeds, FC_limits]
BO_ 373 ESP_wheelSpeeds: 8 ESP
 SG_ ESP_wheelSpeedFrL : 0|13@1+ (0.042,0) [0|343.98] "km/h" Vector__XXX
 SG_ ESP_wheelSpeedFrR : 13|13@1+ (0.042,0) [0|343.98] "km/h" Vector__XXX
 SG_ ESP_wheelSpeedReL : 26|13@1+ (0.042,0) [0|343.98] "km/h" Vector__XXX
 SG_ ESP_wheelSpeedReR : 39|13@1+ (0.042,0) [0|343.98] "km/h" Vector__XXX

BO_ 1662 EVSE_isoTpToVeh: 8 EVSE
 SG_ EVSE_isoTpToVehData : 0|64@1+ (1,0) [0|1.84467440737e+19] "" Vector__XXX

BO_ 1322 FC_alertLog: 8 FC
 SG_ FC_alertID M : 0|15@1+ (1,0) [0|32767] "" Vector__XXX
 SG_ FC_alertType : 15|1@1+ (1,0) [0|1] "" Vector__XXX
 SG_ FC_a130_CA_flybackSwOvType m130 : 16|1@1+ (1,0) [0|1] "" Vector__XXX
 SG_ FC_a146_CA_flybackOnTime m146 : 16|16@1+ (0.0007629511,0) [0|50.0000003385] "uS" Vector__XXX
 SG_ FC_a146_CA_flybackV m146 : 32|16@1+ (0.0128332730383,0) [0|841.028548565] "V" Vector__XXX
 SG_ FC_a146_CA_flybackTargetV m146 : 48|16@1+ (0.0128332730383,0) [0|841.028548565] "V" Vector__XXX
 SG_ FC_a159_CA_wdtTaskList1 m159 : 16|16@1+ (1,0) [0|65535] "" Vector__XXX
 SG_ FC_a159_CA_wdtTaskList2 m159 : 32|16@1+ (1,0) [0|65535] "" Vector__XXX

BO_ 895 FC_alertMatrix3: 8 FC
 SG_ FC_a129_CA_flyback_HW_OC : 0|1@1+ (1,0) [0|1] "" Vector__XXX
 SG_ FC_a130_CA_flyback_SW_OV : 1|1@1+ (1,0) [0|1] "" Vector__XXX
 SG_ FC_a131_CA_flyback_HW_OV : 2|1@1+ (1,0) [0|1] "" Vector__XXX
 SG_ FC_a132_CA_bmsMia : 3|1@1+ (1,0) [0|1] "" Vector__XXX
 SG_ FC_a133_CA_evseMia : 4|1@1+ (1,0) [0|1] "" Vector__XXX
 SG_ FC_a134_CA_vehTxBufOvf : 5|1@1+ (1,0) [0|1] "" Vector__XXX
 SG_ FC_a135_CA_vehRxBufOvf : 6|1@1+ (1,0) [0|1] "" Vector__XXX
 SG_ FC_a136_CA_evseTxBufOvf : 7|1@1+ (1,0) [0|1] "" Vector__XXX
 SG_ FC_a137_CA_evseRxBufOvf : 8|1@1+ (1,0) [0|1] "" Vector__XXX
 SG_ FC_a138_CA_hwProxTrip : 9|1@1+ (1,0) [0|1] "" Vector__XXX
 SG_ FC_a139_CA_ss2NotLow : 10|1@1+ (1,0) [0|1] "" Vector__XXX
 SG_ FC_a140_CA_bmsIncompatible : 11|1@1+ (1,0) [0|1] "" Vector__XXX
 SG_ FC_a141_CA_vehConn_OT : 12|1@1+ (1,0) [0|1] "" Vector__XXX
 SG_ FC_a142_CA_evseConn_OT : 13|1@1+ (1,0) [0|1] "" Vector__XXX
 SG_ FC_a143_CA_pcb_OT : 14|1@1+ (1,0) [0|1] "" Vector__XXX
 SG_ FC_a144_CA_flybackUnstable : 15|1@1+ (1,0) [0|1] "" Vector__XXX
 SG_ FC_a145_CA_flybackDataStale : 16|1@1+ (1,0) [0|1] "" Vector__XXX
 SG_ FC_a146_CA_flybackBusLoadHi : 17|1@1+ (1,0) [0|1] "" Vector__XXX
 SG_ FC_a147_CA_vehConn_UT : 18|1@1+ (1,0) [0|1] "" Vector__XXX
 SG_ FC_a148_CA_evseConn_UT : 19|1@1+ (1,0) [0|1] "" Vector__XXX
 SG_ FC_a149_CA_pcb_UT : 20|1@1+ (1,0) [0|1] "" Vector__XXX
 SG_ FC_a150_CA_vehToEvseDeltaHi : 21|1@1+ (1,0) [0|1] "" Vector__XXX
 SG_ FC_a151_CA_vehToEvseDeltaLo : 22|1@1+ (1,0) [0|1] "" Vector__XXX
 SG_ FC_a152_CA_vehToPcbDeltaHi : 23|1@1+ (1,0) [0|1] "" Vector__XXX
 SG_ FC_a153_CA_evseToPcbDeltaHi : 24|1@1+ (1,0) [0|1] "" Vector__XXX
 SG_ FC_a154_CA_vehToPcbDeltaLo : 25|1@1+ (1,0) [0|1] "" Vector__XXX
 SG_ FC_a155_CA_evseToPcbDeltaLo : 26|1@1+ (1,0) [0|1] "" Vector__XXX
 SG_ FC_a156_CA_flybackRunTimeout : 27|1@1+ (1,0) [0|1] "" Vector__XXX
 SG_ FC_a157_CA_unused : 28|1@1+ (1,0) [0|1] "" Vector__XXX
 SG_ FC_a158_CA_evseOverCurrent : 29|1@1+ (1,0) [0|1] "" Vector__XXX
 SG_ FC_a159_CA_wdtExpired : 30|1@1+ (1,0) [0|1] "" Vector__XXX
 SG_ FC_a160_CA_ss2Deasserted : 31|1@1+ (1,0) [0|1] "" Vector__XXX
 SG_ FC_a161_CA_vehTempHiFoldBk : 32|1@1+ (1,0) [0|1] "" Vector__XXX
 SG_ FC_a162_CA_evseTempHiFoldBk : 33|1@1+ (1,0) [0|1] "" Vector__XXX
 SG_ FC_a163_CA_pcbTempHiFoldBk : 34|1@1+ (1,0) [0|1] "" Vector__XXX
 SG_ FC_a164_CA_proxDisconnected : 35|1@1+ (1,0) [0|1] "" Vector__XXX
 SG_ FC_a165_CA_evseConnUnlocked : 36|1@1+ (1,0) [0|1] "" Vector__XXX
 SG_ FC_a166_CA_vehConnUnlocked : 37|1@1+ (1,0) [0|1] "" Vector__XXX
 SG_ FC_a167_CA_isoVoltageLow : 38|1@1+ (1,0) [0|1] "" Vector__XXX
 SG_ FC_a168_CA_proxTimeout : 39|1@1+ (1,0) [0|1] "" Vector__XXX
 SG_ FC_a169_CA_pilotAcceptTimeout : 40|1@1+ (1,0) [0|1] "" Vector__XXX
 SG_ FC_a170_CA_vehDataTimeout : 41|1@1+ (1,0) [0|1] "" Vector__XXX
 SG_ FC_a171_CA_vehConLockTimeout : 42|1@1+ (1,0) [0|1] "" Vector__XXX
 SG_ FC_a172_CA_ss2LowTimeout : 43|1@1+ (1,0) [0|1] "" Vector__XXX
 SG_ FC_a173_CA_evseDataTimeout : 44|1@1+ (1,0) [0|1] "" Vector__XXX
 SG_ FC_a174_CA_vehReadyTimeout : 45|1@1+ (1,0) [0|1] "" Vector__XXX
 SG_ FC_a175_CA_evseIsoTestTimeout : 46|1@1+ (1,0) [0|1] "" Vector__XXX
 SG_ FC_a176_CA_chargingBusTimeout : 47|1@1+ (1,0) [0|1] "" Vector__XXX
 SG_ FC_a177_CA_bmsCtrCloseTimeout : 48|1@1+ (1,0) [0|1] "" Vector__XXX
 SG_ FC_a178_CA_evseStartTimeout : 49|1@1+ (1,0) [0|1] "" Vector__XXX
 SG_ FC_a179_CA_startupProblem : 50|1@1+ (1,0) [0|1] "" Vector__XXX
 SG_ FC_a180_CA_chargingProblem : 51|1@1+ (1,0) [0|1] "" Vector__XXX
 SG_ FC_a181_CA_vRegBrownout : 52|1@1+ (1,0) [0|1] "" Vector__XXX
 SG_ FC_a182_CA_evseChrMalfunc : 53|1@1+ (1,0) [0|1] "" Vector__XXX
 SG_ FC_a183_CA_evseBatIncompat : 54|1@1+ (1,0) [0|1] "" Vector__XXX
 SG_ FC_a184_CA_evseBatMalfunc : 55|1@1+ (1,0) [0|1] "" Vector__XXX
 SG_ FC_a185_CA_vehReadyDeasserted : 56|1@1+ (1,0) [0|1] "" Vector__XXX
 SG_ FC_a186_CA_fcContOpenTimeout : 57|1@1+ (1,0) [0|1] "" Vector__XXX
 SG_ FC_a187_CA_evseConLockTimeout : 58|1@1+ (1,0) [0|1] "" Vector__XXX

BO_ 927 FC_alertMatrix4: 8 FC
 SG_ FC_a193_FCAlertPlaceholder : 0|1@1+ (1,0) [0|1] "" Vector__XXX

BO_ 958 FC_alertMatrix5: 8 FC
 SG_ FC_a257_GB_bmsMia : 0|1@1+ (1,0) [0|1] "" Vector__XXX
 SG_ FC_a258_GB_evseMia : 1|1@1+ (1,0) [0|1] "" Vector__XXX
 SG_ FC_a259_GB_vehTxBufOvf : 2|1@1+ (1,0) [0|1] "" Vector__XXX
 SG_ FC_a260_GB_vehRxBufOvf : 3|1@1+ (1,0) [0|1] "" Vector__XXX
 SG_ FC_a261_GB_evseTxBufOvf : 4|1@1+ (1,0) [0|1] "" Vector__XXX
 SG_ FC_a262_GB_evseRxBufOvf : 5|1@1+ (1,0) [0|1] "" Vector__XXX
 SG_ FC_a263_GB_hwProxTrip : 6|1@1+ (1,0) [0|1] "" Vector__XXX
 SG_ FC_a264_GB_timeoutCHM : 7|1@1+ (1,0) [0|1] "" Vector__XXX
 SG_ FC_a265_GB_bmsIncompatible : 8|1@1+ (1,0) [0|1] "" Vector__XXX
 SG_ FC_a266_GB_negPin_OT : 9|1@1+ (1,0) [0|1] "" Vector__XXX
 SG_ FC_a267_GB_posPin_OT : 10|1@1+ (1,0) [0|1] "" Vector__XXX
 SG_ FC_a268_GB_pcb_OT : 11|1@1+ (1,0) [0|1] "" Vector__XXX
 SG_ FC_a269_GB_timeoutCRM : 12|1@1+ (1,0) [0|1] "" Vector__XXX
 SG_ FC_a270_GB_timeoutCML : 13|1@1+ (1,0) [0|1] "" Vector__XXX
 SG_ FC_a271_GB_timeoutCRO : 14|1@1+ (1,0) [0|1] "" Vector__XXX
 SG_ FC_a272_GB_negToPosDeltaHi : 15|1@1+ (1,0) [0|1] "" Vector__XXX
 SG_ FC_a273_GB_negToPosDeltaLo : 16|1@1+ (1,0) [0|1] "" Vector__XXX
 SG_ FC_a274_GB_negToPcbDeltaHi : 17|1@1+ (1,0) [0|1] "" Vector__XXX
 SG_ FC_a275_GB_posToPcbDeltaHi : 18|1@1+ (1,0) [0|1] "" Vector__XXX
 SG_ FC_a276_GB_negToPcbDeltaLo : 19|1@1+ (1,0) [0|1] "" Vector__XXX
 SG_ FC_a277_GB_posToPcbDeltaLo : 20|1@1+ (1,0) [0|1] "" Vector__XXX
 SG_ FC_a278_GB_timeoutCCS : 21|1@1+ (1,0) [0|1] "" Vector__XXX
 SG_ FC_a279_GB_evseOverCurrent : 22|1@1+ (1,0) [0|1] "" Vector__XXX
 SG_ FC_a280_GB_retryLimitExceeded : 23|1@1+ (1,0) [0|1] "" Vector__XXX
 SG_ FC_a281_GB_evseOutOfService : 24|1@1+ (1,0) [0|1] "" Vector__XXX
 SG_ FC_a282_GB_negTempHiFoldBk : 25|1@1+ (1,0) [0|1] "" Vector__XXX
 SG_ FC_a283_GB_posTempHiFoldBk : 26|1@1+ (1,0) [0|1] "" Vector__XXX
 SG_ FC_a284_GB_pcbTempHiFoldBk : 27|1@1+ (1,0) [0|1] "" Vector__XXX
 SG_ FC_a285_GB_proxDisconnected : 28|1@1+ (1,0) [0|1] "" Vector__XXX
 SG_ FC_a286_GB_evseConnUnlocked : 29|1@1+ (1,0) [0|1] "" Vector__XXX
 SG_ FC_a287_GB_vehConnUnlocked : 30|1@1+ (1,0) [0|1] "" Vector__XXX
 SG_ FC_a288_GB_evseAbnormalStopReq : 31|1@1+ (1,0) [0|1] "" Vector__XXX
 SG_ FC_a289_GB_proxTimeout : 32|1@1+ (1,0) [0|1] "" Vector__XXX
 SG_ FC_a290_GB_pilotAcceptTimeout : 33|1@1+ (1,0) [0|1] "" Vector__XXX
 SG_ FC_a291_GB_vehDataTimeout : 34|1@1+ (1,0) [0|1] "" Vector__XXX
 SG_ FC_a292_GB_vehConLockTimeout : 35|1@1+ (1,0) [0|1] "" Vector__XXX
 SG_ FC_a293_GB_proxRationality : 36|1@1+ (1,0) [0|1] "" Vector__XXX
 SG_ FC_a294_GB_unused : 37|1@1+ (1,0) [0|1] "" Vector__XXX
 SG_ FC_a295_GB_pilotRationality : 38|1@1+ (1,0) [0|1] "" Vector__XXX
 SG_ FC_a296_GB_invalidPilotTransitio : 39|1@1+ (1,0) [0|1] "" Vector__XXX
 SG_ FC_a297_GB_unused : 40|1@1+ (1,0) [0|1] "" Vector__XXX
 SG_ FC_a298_GB_bmsCtrCloseTimeout : 41|1@1+ (1,0) [0|1] "" Vector__XXX
 SG_ FC_a299_GB_evseReadyTimeout : 42|1@1+ (1,0) [0|1] "" Vector__XXX
 SG_ FC_a300_GB_unused : 43|1@1+ (1,0) [0|1] "" Vector__XXX
 SG_ FC_a301_GB_unused : 44|1@1+ (1,0) [0|1] "" Vector__XXX
 SG_ FC_a302_GB_unused : 45|1@1+ (1,0) [0|1] "" Vector__XXX
 SG_ FC_a303_GB_negRecogTimeout : 46|1@1+ (1,0) [0|1] "" Vector__XXX
 SG_ FC_a304_GB_unused : 47|1@1+ (1,0) [0|1] "" Vector__XXX
 SG_ FC_a305_GB_posRecogTimeout : 48|1@1+ (1,0) [0|1] "" Vector__XXX
 SG_ FC_a306_GB_vehReadyDeasserted : 49|1@1+ (1,0) [0|1] "" Vector__XXX
 SG_ FC_a307_GB_fcContOpenTimeout : 50|1@1+ (1,0) [0|1] "" Vector__XXX
 SG_ FC_a308_GB_evseConLockTimeout : 51|1@1+ (1,0) [0|1] "" Vector__XXX
 SG_ FC_a309_GB_unused : 52|1@1+ (1,0) [0|1] "" Vector__XXX
 SG_ FC_a310_GB_unused : 53|1@1+ (1,0) [0|1] "" Vector__XXX
 SG_ FC_a311_GB_battParamsTimeout : 54|1@1+ (1,0) [0|1] "" Vector__XXX
 SG_ FC_a312_GB_evseLimitsTimeout : 55|1@1+ (1,0) [0|1] "" Vector__XXX
 SG_ FC_a313_GB_inputVoltageRailOv : 56|1@1+ (1,0) [0|1] "" Vector__XXX

BO_ 990 FC_alertMatrix6: 8 FC
 SG_ FC_a321_FCAlertPlaceholder : 0|1@1+ (1,0) [0|1] "" Vector__XXX

BO_ 1117 FC_evseBilling: 8 FC
 SG_ FC_evseBillingDataSelect M : 0|1@1+ (1,0) [0|1] "" Vector__XXX
 SG_ FC_evseBillingEnergy m0 : 4|20@1+ (0.001,0) [0|1048.575] "kWh" Vector__XXX
 SG_ FC_evseMeterPower m0 : 24|20@1+ (0.001,0) [0|1048.575] "kW" Vector__XXX
 SG_ FC_evseMeterCurrent m0 : 44|10@1+ (1,0) [0|1023] "A" Vector__XXX
 SG_ FC_evseMeterVoltage m0 : 54|10@1+ (1,0) [0|1023] "V" Vector__XXX
 SG_ FC_evseMeterFwGitHash m1 : 4|56@1+ (1,0) [0|7.20575940379e+16] "" Vector__XXX

BO_ 1334 FC_evseBilling2: 8 FC
 SG_ FC_evseBilling2DataSelect M : 0|4@1+ (1,0) [0|15] "" Vector__XXX
 SG_ FC_evsePpuEnabled m0 : 4|1@1+ (1,0) [0|1] "" Vector__XXX
 SG_ FC_evseBillingEnergyHighRes m0 : 8|24@1+ (0.0001,0) [0|1677.7214] "kWh" Vector__XXX

BO_ 1303 FC_identifier: 8 FC
 SG_ FC_id : 0|32@1+ (1,0) [0|4294967295] "" Vector__XXX
 SG_ FC_sessionId : 32|32@1+ (1,0) [0|4294967295] "" Vector__XXX

BO_ 1310 FC_info: 8 FC
 SG_ FC_infoIndex M : 0|8@1+ (1,0) [0|255] "" Vector__XXX
 SG_ FC_infoBuildType m10 : 8|8@1+ (1,0) [0|255] "" Vector__XXX
 SG_ FC_infoBuildConfigID m10 : 16|16@1+ (1,0) [0|65535] "" Vector__XXX
 SG_ FC_infoHardwareID m10 : 32|16@1+ (1,0) [0|65535] "" Vector__XXX
 SG_ FC_infoComponentID m10 : 48|16@1+ (1,0) [0|65535] "" Vector__XXX
 SG_ FC_infoPcbaID m11 : 16|8@1+ (1,0) [0|255] "" Vector__XXX
 SG_ FC_infoAssemblyID m11 : 24|8@1+ (1,0) [0|255] "" Vector__XXX
 SG_ FC_infoUsageID m11 : 32|16@1+ (1,0) [0|65535] "" Vector__XXX
 SG_ FC_infoSubUsageID m11 : 48|16@1+ (1,0) [0|65535] "" Vector__XXX
 SG_ FC_infoApplicationCRC m13 : 32|32@1+ (1,0) [0|4294967295] "" Vector__XXX
 SG_ FC_infoBootSvnRev m14 : 8|24@1+ (1,0) [0|16777215] "" Vector__XXX
 SG_ FC_infoCPLDVersionMajor m16 : 16|8@1+ (1,0) [0|255] "" Vector__XXX
 SG_ FC_infoCPLDVersionMinor m16 : 24|8@1+ (1,0) [0|255] "" Vector__XXX
 SG_ FC_infoAppGitHashBytes m17 : 8|56@1+ (1,0) [0|7.20575940379e+16] "" Vector__XXX
 SG_ FC_infoBootGitHashBytes m18 : 8|56@1+ (1,0) [0|7.20575940379e+16] "" Vector__XXX
 SG_ FC_infoPlatformType m19 : 8|8@1+ (1,0) [0|255] "" Vector__XXX
 SG_ FC_infoMajorVersion m19 : 16|8@1+ (1,0) [0|255] "" Vector__XXX
 SG_ FC_infoBranchOrigin m19 : 24|8@1+ (1,0) [0|255] "" Vector__XXX
 SG_ FC_infoMaturity m19 : 32|8@1+ (1,0) [0|255] "" Vector__XXX
 SG_ FC_infoHardwareRevision m19 : 40|8@1+ (1,0) [0|255] "" Vector__XXX
 SG_ FC_infoBootUdsProtoVersion m20 : 8|8@1+ (1,0) [0|255] "" Vector__XXX
 SG_ FC_partNumChar01 m25 : 8|8@1+ (1,0) [0|255] "" Vector__XXX
 SG_ FC_partNumChar02 m25 : 16|8@1+ (1,0) [0|255] "" Vector__XXX
 SG_ FC_partNumChar03 m25 : 24|8@1+ (1,0) [0|255] "" Vector__XXX
 SG_ FC_partNumChar04 m25 : 32|8@1+ (1,0) [0|255] "" Vector__XXX
 SG_ FC_partNumChar05 m25 : 40|8@1+ (1,0) [0|255] "" Vector__XXX
 SG_ FC_partNumChar06 m25 : 48|8@1+ (1,0) [0|255] "" Vector__XXX
 SG_ FC_partNumChar07 m25 : 56|8@1+ (1,0) [0|255] "" Vector__XXX
 SG_ FC_partNumChar08 m26 : 8|8@1+ (1,0) [0|255] "" Vector__XXX
 SG_ FC_partNumChar09 m26 : 16|8@1+ (1,0) [0|255] "" Vector__XXX
 SG_ FC_partNumChar10 m26 : 24|8@1+ (1,0) [0|255] "" Vector__XXX
 SG_ FC_partNumChar11 m26 : 32|8@1+ (1,0) [0|255] "" Vector__XXX
 SG_ FC_partNumChar12 m26 : 40|8@1+ (1,0) [0|255] "" Vector__XXX
 SG_ FC_partNumChar13 m26 : 48|8@1+ (1,0) [0|255] "" Vector__XXX
 SG_ FC_partNumChar14 m26 : 56|8@1+ (1,0) [0|255] "" Vector__XXX
 SG_ FC_partNumChar15 m27 : 8|8@1+ (1,0) [0|255] "" Vector__XXX
 SG_ FC_partNumChar16 m27 : 16|8@1+ (1,0) [0|255] "" Vector__XXX
 SG_ FC_partNumChar17 m27 : 24|8@1+ (1,0) [0|255] "" Vector__XXX
 SG_ FC_partNumChar18 m27 : 32|8@1+ (1,0) [0|255] "" Vector__XXX
 SG_ FC_partNumChar19 m27 : 40|8@1+ (1,0) [0|255] "" Vector__XXX
 SG_ FC_partNumChar20 m27 : 48|8@1+ (1,0) [0|255] "" Vector__XXX

BO_ 580 FC_limits: 8 FC
 SG_ FC_powerLimit : 0|13@1+ (0.06225586,0) [0|509.8754934] "kW" Vector__XXX
 SG_ FC_currentLimit : 16|13@1+ (0.07324219,0) [0|599.8535361] "A" Vector__XXX
 SG_ FC_maxVoltageLimit : 32|13@1+ (0.07324219,0) [0|599.8535361] "V" Vector__XXX
 SG_ FC_minVoltageLimit : 48|13@1+ (0.07324219,0) [0|599.8535361] "V" Vector__XXX

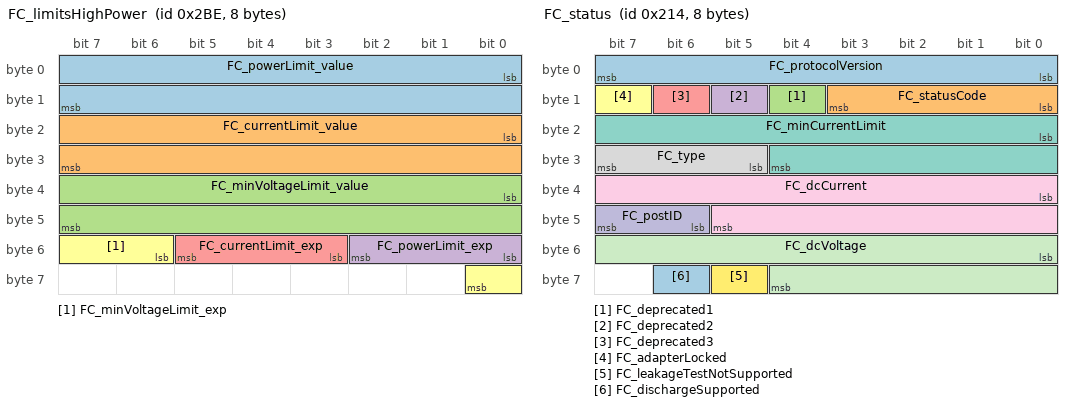
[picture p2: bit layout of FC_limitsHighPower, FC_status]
BO_ 702 FC_limitsHighPower: 8 FC
 SG_ FC_powerLimit_value : 0|16@1- (1,0) [-32767|32767] "*10^exp kW" Vector__XXX
 SG_ FC_currentLimit_value : 16|16@1- (1,0) [-32767|32767] "*10^exp A" Vector__XXX
 SG_ FC_minVoltageLimit_value : 32|16@1- (1,0) [-32767|32767] "*10^exp V" Vector__XXX
 SG_ FC_powerLimit_exp : 48|3@1- (1,0) [-4|3] "" Vector__XXX
 SG_ FC_currentLimit_exp : 51|3@1- (1,0) [-4|3] "" Vector__XXX
 SG_ FC_minVoltageLimit_exp : 54|3@1- (1,0) [-4|3] "" Vector__XXX

BO_ 1345 FC_maxLimits: 8 FC
 SG_ FC_maxPowerLimit : 0|13@1+ (0.06225586,0) [0|509.8754934] "kW" Vector__XXX
 SG_ FC_maxCurrentLimit : 16|13@1+ (0.07324219,0) [0|599.8535361] "A" Vector__XXX

BO_ 1300 FC_serial: 8 FC
 SG_ FC_serialDataSelect M : 0|7@1+ (1,0) [0|127] "" Vector__XXX
 SG_ FC_serialChar01 m0 : 8|8@1+ (1,0) [0|255] "" Vector__XXX
 SG_ FC_serialChar02 m0 : 16|8@1+ (1,0) [0|255] "" Vector__XXX
 SG_ FC_serialChar03 m0 : 24|8@1+ (1,0) [0|255] "" Vector__XXX
 SG_ FC_serialChar04 m0 : 32|8@1+ (1,0) [0|255] "" Vector__XXX
 SG_ FC_serialChar05 m0 : 40|8@1+ (1,0) [0|255] "" Vector__XXX
 SG_ FC_serialChar06 m0 : 48|8@1+ (1,0) [0|255] "" Vector__XXX
 SG_ FC_serialChar07 m0 : 56|8@1+ (1,0) [0|255] "" Vector__XXX
 SG_ FC_serialChar08 m1 : 8|8@1+ (1,0) [0|255] "" Vector__XXX
 SG_ FC_serialChar09 m1 : 16|8@1+ (1,0) [0|255] "" Vector__XXX
 SG_ FC_serialChar10 m1 : 24|8@1+ (1,0) [0|255] "" Vector__XXX
 SG_ FC_serialChar11 m1 : 32|8@1+ (1,0) [0|255] "" Vector__XXX
 SG_ FC_serialChar12 m1 : 40|8@1+ (1,0) [0|255] "" Vector__XXX
 SG_ FC_serialChar13 m1 : 48|8@1+ (1,0) [0|255] "" Vector__XXX
 SG_ FC_serialChar14 m1 : 56|8@1+ (1,0) [0|255] "" Vector__XXX
 SG_ FC_serialChar15 m2 : 8|8@1+ (1,0) [0|255] "" Vector__XXX
 SG_ FC_serialChar16 m2 : 16|8@1+ (1,0) [0|255] "" Vector__XXX
 SG_ FC_serialChar17 m2 : 24|8@1+ (1,0) [0|255] "" Vector__XXX

BO_ 532 FC_status: 8 FC
 SG_ FC_protocolVersion : 0|8@1+ (1,0) [0|255] "" Vector__XXX
 SG_ FC_statusCode : 8|4@1+ (1,0) [1|15] "" Vector__XXX
 SG_ FC_deprecated1 : 12|1@1+ (1,0) [0|1] "" Vector__XXX
 SG_ FC_deprecated2 : 13|1@1+ (1,0) [0|1] "" Vector__XXX
 SG_ FC_deprecated3 : 14|1@1+ (1,0) [0|1] "" Vector__XXX
 SG_ FC_adapterLocked : 15|1@1+ (1,0) [0|1] "" Vector__XXX
 SG_ FC_minCurrentLimit : 16|13@1+ (0.1,0) [0|600] "A" Vector__XXX
 SG_ FC_type : 29|3@1+ (1,0) [0|6] "" Vector__XXX
 SG_ FC_dcCurrent : 32|14@1- (0.07324219,0) [-600|599.92675781] "A" Vector__XXX
 SG_ FC_postID : 46|2@1+ (1,0) [0|2] "" Vector__XXX
 SG_ FC_dcVoltage : 48|13@1+ (0.07324219,0) [0|599.92675822] "V" Vector__XXX
 SG_ FC_leakageTestNotSupported : 61|1@1+ (1,0) [0|1] "" Vector__XXX
 SG_ FC_dischargeSupported : 62|1@1+ (1,0) [0|1] "" Vector__XXX

BO_ 533 FC_status2: 1 FC
 SG_ FC_externalIsolationResistance : 0|8@1+ (40,0) [0|10160] "kOhm" Vector__XXX

BO_ 535 FC_status3: 8 FC
 SG_ FC_status3DataSelect M : 0|7@1+ (1,0) [0|127] "" Vector__XXX
 SG_ FC_status3DummySig : 7|1@1+ (1,0) [0|1] "" Vector__XXX
 SG_ FC_class m0 : 8|8@1+ (1,0) [1|255] "" Vector__XXX
 SG_ FC_brand m0 : 16|4@1+ (1,0) [1|15] "" Vector__XXX
 SG_ FC_coolingType m0 : 20|4@1+ (1,0) [1|15] "" Vector__XXX
 SG_ FC_uiStopType m0 : 24|4@1+ (1,0) [1|15] "" Vector__XXX
 SG_ FC_emergencyShutdownSupported m0 : 28|1@1+ (1,0) [0|1] "" Vector__XXX
 SG_ FC_generation m0 : 32|8@1+ (1,0) [1|255] "" Vector__XXX
 SG_ FC_billingEnergy m1 : 8|16@1+ (0.015259,0) [0|999.998565] "kWh" Vector__XXX

BO_ 888 GTW_ECall: 1 GTW
 SG_ GTW_GTW_SOS_ECALL_RQST : 0|1@1+ (1,0) [0|1] "" Vector__XXX
 SG_ GTW_LTE_ECALL_LOCK : 1|1@1+ (1,0) [0|1] "" Vector__XXX

BO_TX_BU_ 1000 : EPBR;
BO_TX_BU_ 2024 : EPBR;
BO_TX_BU_ 552 : EPBR;
BO_TX_BU_ 742 : EPBR;
BO_TX_BU_ 744 : EPBR;
BO_TX_BU_ 1575 : EPBR;
BO_TX_BU_ 981 : ESP;
BO_TX_BU_ 808 : ESP;
BO_TX_BU_ 1236 : ESP;
BO_TX_BU_ 325 : ESP;
BO_TX_BU_ 1621 : ESP;
BO_TX_BU_ 373 : ESP;
BO_TX_BU_ 1662 : EVSE;
BO_TX_BU_ 1322 : FC;
BO_TX_BU_ 895 : FC;
BO_TX_BU_ 927 : FC;
BO_TX_BU_ 958 : FC;
BO_TX_BU_ 990 : FC;
BO_TX_BU_ 1117 : FC;
BO_TX_BU_ 1334 : FC;
BO_TX_BU_ 1303 : FC;
BO_TX_BU_ 1310 : FC;
BO_TX_BU_ 580 : FC;
BO_TX_BU_ 702 : FC;
BO_TX_BU_ 1345 : FC;
BO_TX_BU_ 1300 : FC;
BO_TX_BU_ 532 : FC;
BO_TX_BU_ 533 : FC;
BO_TX_BU_ 535 : FC;
BO_TX_BU_ 888 : GTW;
CM_ BO_ 1000 "Right electric parking brake message: alert matrix";
CM_ SG_ 1000 EPBR_matrixIndex "Right electric parking brake: matrix index";
CM_ SG_ 1000 EPBR_a001_WatchdogReset "Right electric parking brake: a001 watchdog reset";
CM_ SG_ 1000 EPBR_a002_PowerLossReset "Right electric parking brake: a002 power loss reset";
CM_ SG_ 1000 EPBR_a003_SWAssertion "Right electric parking brake: a003 SW assertion";
CM_ SG_ 1000 EPBR_a005_CANTXError "Right electric parking brake: a005 CANTX error";
CM_ SG_ 1000 EPBR_a006_CANTX_cyclicError "Right electric parking brake: a006 CANTX cyclic error";
CM_ SG_ 1000 EPBR_a012_CPUReset "Right electric parking brake: a012 CPU reset";
CM_ SG_ 1000 EPBR_a013_AlertManagerFault "Right electric parking brake: a013 alert manager fault";
CM_ SG_ 1000 EPBR_a015_NVMMError "Right electric parking brake: a015 NVMM error";
CM_ SG_ 1000 EPBR_a016_NVMMRecordError "Right electric parking brake: a016 NVMM record error";
CM_ SG_ 1000 EPBR_a021_TaskSchedulerError "Right electric parking brake: a021 task scheduler error";
CM_ SG_ 1000 EPBR_a022_TaskInitError "Right electric parking brake: a022 task init error";
CM_ SG_ 1000 EPBR_a029_CoreDump "Right electric parking brake: a029 core dump";
CM_ SG_ 1000 EPBR_a030_ECULogUploadRequest "Right electric parking brake: a030 ECU log upload request";
CM_ SG_ 1000 EPBR_a031_UDSActive "Right electric parking brake: a031 UDS active";
CM_ SG_ 1000 EPBR_a041_HighCPULoad "Right electric parking brake: a041 high CPU load";
CM_ SG_ 1000 EPBR_a042_HighStackUsage "Right electric parking brake: a042 high stack usage";
CM_ SG_ 1000 EPBR_a043_Task1msError "Right electric parking brake: a043 task1ms error";
CM_ SG_ 1000 EPBR_a044_Task10msError "Right electric parking brake: a044 task10ms error";
CM_ SG_ 1000 EPBR_a045_Task100msError "Right electric parking brake: a045 task100ms error";
CM_ SG_ 1000 EPBR_a046_Task1000msError "Right electric parking brake: a046 task1000ms error";
CM_ SG_ 1000 EPBR_a057_HVP_MIA "Right electric parking brake: a057 HVP MIA";
CM_ SG_ 1000 EPBR_a058_inputRHighSyncDebug "Right electric parking brake: a058 input r high sync debug";
CM_ SG_ 1000 EPBR_a059_inputResistanceHigh "Right electric parking brake: a059 input resistance high";
CM_ SG_ 1000 EPBR_a060_engineeringBuild "Right electric parking brake: a060 engineering build";
CM_ SG_ 1000 EPBR_a061_XCPConnected "Right electric parking brake: a061 XCP connected";
CM_ SG_ 1000 EPBR_a062_XCPWasConnected "Right electric parking brake: a062 XCP was connected";
CM_ SG_ 1000 EPBR_a063_SwitchFault "Right electric parking brake: a063 switch fault";
CM_ SG_ 1000 EPBR_a064_busSleepReqTimeout "Right electric parking brake: a064 bus sleep req timeout";
CM_ SG_ 1000 EPBR_a081_APP_MIA "Right electric parking brake: a081 APP MIA";
CM_ SG_ 1000 EPBR_a082_VCRIGHT_IPC_MIA "Right electric parking brake: a082 VCRIGHT IPC MIA";
CM_ SG_ 1000 EPBR_a083_VCLEFT_IPC_MIA "Right electric parking brake: a083 VCLEFT IPC MIA";
CM_ SG_ 1000 EPBR_a084_TPMS_MIA "Right electric parking brake: a084 TPMS MIA";
CM_ SG_ 1000 EPBR_a085_CCCM_MIA "Right electric parking brake: a085 CCCM MIA";
CM_ SG_ 1000 EPBR_a086_VCBATT_MIA "Right electric parking brake: a086 VCBATT MIA";
CM_ SG_ 1000 EPBR_a087_DIREL_MIA "Right electric parking brake: a087 DIREL MIA";
CM_ SG_ 1000 EPBR_a088_DIRER_MIA "Right electric parking brake: a088 DIRER MIA";
CM_ SG_ 1000 EPBR_a089_IBST_MIA "Right electric parking brake: a089 IBST MIA";
CM_ SG_ 1000 EPBR_a090_APS_MIA "Right electric parking brake: a090 APS MIA";
CM_ SG_ 1000 EPBR_a091_CMPD_MIA "Right electric parking brake: a091 CMPD MIA";
CM_ SG_ 1000 EPBR_a092_VCSEATD_MIA "Right electric parking brake: a092 VCSEATD MIA";
CM_ SG_ 1000 EPBR_a093_VCSEATP_MIA "Right electric parking brake: a093 VCSEATP MIA";
CM_ SG_ 1000 EPBR_a094_EPAS3P_MIA "Right electric parking brake: a094 EPAS3 p MIA";
CM_ SG_ 1000 EPBR_a095_CHG_MIA "Right electric parking brake: a095 CHG MIA";
CM_ SG_ 1000 EPBR_a096_OCS1P_MIA "Right electric parking brake: a096 OCS1 p MIA";
CM_ SG_ 1000 EPBR_a097_CMP_MIA "Right electric parking brake: a097 CMP MIA";
CM_ SG_ 1000 EPBR_a098_DIR_MIA "Right electric parking brake: a098 DIR MIA";
CM_ SG_ 1000 EPBR_a099_PARK_MIA "Right electric parking brake: a099 PARK MIA";
CM_ SG_ 1000 EPBR_a100_CANbus_MIA "Right electric parking brake: a100 CA nbus MIA";
CM_ SG_ 1000 EPBR_a101_PM_MIA "Right electric parking brake: a101 PM MIA";
CM_ SG_ 1000 EPBR_a102_PTC_MIA "Right electric parking brake: a102 PTC MIA";
CM_ SG_ 1000 EPBR_a103_CP_MIA "Right electric parking brake: a103 CP MIA";
CM_ SG_ 1000 EPBR_a104_DAS_MIA "Right electric parking brake: a104 DAS MIA";
CM_ SG_ 1000 EPBR_a105_TAS_MIA "Right electric parking brake: a105 TAS MIA";
CM_ SG_ 1000 EPBR_a106_PCS_MIA "Right electric parking brake: a106 PCS MIA";
CM_ SG_ 1000 EPBR_a107_BMS_MIA "Right electric parking brake: a107 BMS MIA";
CM_ SG_ 1000 EPBR_a108_DIF_MIA "Right electric parking brake: a108 DIF MIA";
CM_ SG_ 1000 EPBR_a109_RCM_MIA "Right electric parking brake: a109 RCM MIA";
CM_ SG_ 1000 EPBR_a110_GTW_MIA "Right electric parking brake: a110 GTW MIA";
CM_ SG_ 1000 EPBR_a111_EPBR_MIA "Right electric parking brake: a111 EPBR MIA";
CM_ SG_ 1000 EPBR_a112_EPBL_MIA "Right electric parking brake: a112 EPBL MIA";
CM_ SG_ 1000 EPBR_a113_UI_MIA "Right electric parking brake: a113 UI MIA";
CM_ SG_ 1000 EPBR_a114_ESP_MIA "Right electric parking brake: a114 ESP MIA";
CM_ SG_ 1000 EPBR_a115_VCSEC_MIA "Right electric parking brake: a115 VCSEC MIA";
CM_ SG_ 1000 EPBR_a116_VCRIGHT_MIA "Right electric parking brake: a116 VCRIGHT MIA";
CM_ SG_ 1000 EPBR_a117_VCLEFT_MIA "Right electric parking brake: a117 VCLEFT MIA";
CM_ SG_ 1000 EPBR_a118_VCFRONT_MIA "Right electric parking brake: a118 VCFRONT MIA";
CM_ SG_ 1000 EPBR_a119_SCCM_MIA "Right electric parking brake: a119 SCCM MIA";
CM_ SG_ 1000 EPBR_a120_DI_DRIVE_MIA "Right electric parking brake: a120 DI DRIVE MIA";
CM_ SG_ 1000 EPBR_a121_nDriveFault "Right electric parking brake: a121 n drive fault";
CM_ SG_ 1000 EPBR_a122_Oc "Right electric parking brake: a122 oc";
CM_ SG_ 1000 EPBR_a123_Uc "Right electric parking brake: a123 uc";
CM_ SG_ 1000 EPBR_a124_calOutOfBounds "Right electric parking brake: a124 cal out of bounds";
CM_ SG_ 1000 EPBR_a125_IdleVMismatch "Right electric parking brake: a125 idle v mismatch";
CM_ SG_ 1000 EPBR_a126_MotorNVoltLow "Right electric parking brake: a126 motor n volt low";
CM_ SG_ 1000 EPBR_a127_MotorNVoltHigh "Right electric parking brake: a127 motor n volt high";
CM_ SG_ 1000 EPBR_a128_MotorPVoltHigh "Right electric parking brake: a128 motor p volt high";
CM_ SG_ 1000 EPBR_a129_ICR_MIA "Right electric parking brake: a129 ICR MIA";
CM_ SG_ 1000 EPBR_a130_BB_MIA "Right electric parking brake: a130 BB MIA";
CM_ SG_ 1000 EPBR_a131_RCU_MIA "Right electric parking brake: a131 RCU MIA";
CM_ SG_ 1000 EPBR_a132_VCBATT1_MIA "Right electric parking brake: a132 VCBATT1 MIA";
CM_ SG_ 1000 EPBR_a133_VCBATT2_MIA "Right electric parking brake: a133 VCBATT2 MIA";
CM_ SG_ 1000 EPBR_a134_NvOv "Right electric parking brake: a134 nv ov";
CM_ SG_ 1000 EPBR_a135_NvUv "Right electric parking brake: a135 nv uv";
CM_ SG_ 1000 EPBR_a136_PvOv "Right electric parking brake: a136 pv ov";
CM_ SG_ 1000 EPBR_a137_PvUv "Right electric parking brake: a137 pv uv";
CM_ SG_ 1000 EPBR_a138_NvmDualFailure "Right electric parking brake: a138 nvm dual failure";
CM_ SG_ 1000 EPBR_a139_NvmRedundancyLoss "Right electric parking brake: a139 nvm redundancy loss";
CM_ SG_ 1000 EPBR_a140_NvmSlowWrite "Right electric parking brake: a140 nvm slow write";
CM_ SG_ 1000 EPBR_a141_invalidState "Right electric parking brake: a141 invalid state";
CM_ SG_ 1000 EPBR_a170_12vOv "Right electric parking brake: a170 12v ov";
CM_ SG_ 1000 EPBR_a171_12vUv "Right electric parking brake: a171 12v uv";
CM_ SG_ 1000 EPBR_a172_SPI_MIA "Right electric parking brake: a172 SPI MIA";
CM_ SG_ 1000 EPBR_a173_hiCurrentMissing "Right electric parking brake: a173 hi current missing";
CM_ SG_ 1000 EPBR_a174_csmReleaseFailed "Right electric parking brake: a174 csm release failed";
CM_ SG_ 1000 EPBR_a175_csmReleaseRetry "Right electric parking brake: a175 csm release retry";
CM_ SG_ 1000 EPBR_a176_csmApplyFailed "Right electric parking brake: a176 csm apply failed";
CM_ SG_ 1000 EPBR_a177_csmApplyRetry "Right electric parking brake: a177 csm apply retry";
CM_ SG_ 1000 EPBR_a178_caliperStateUnknown "Right electric parking brake: a178 caliper state unknown";
CM_ SG_ 1000 EPBR_a179_epbProblem "Right electric parking brake: a179 epb problem";
CM_ SG_ 1000 EPBR_a180_dynamicActive "Right electric parking brake: a180 dynamic active";
CM_ SG_ 1000 EPBR_a181_TooSteepGradeToPark "Right electric parking brake: a181 too steep grade to park";
CM_ SG_ 1000 EPBR_a182_OneEPBAppliedUnsecEnv "Right electric parking brake: a182 one EPB applied unsec env";
CM_ SG_ 1000 EPBR_a183_cdpNotAvailable "Right electric parking brake: a183 cdp not available";
CM_ SG_ 1000 EPBR_a184_dynamicParkAbort "Right electric parking brake: a184 dynamic park abort";
CM_ SG_ 1000 EPBR_a185_summonAborted "Right electric parking brake: a185 summon aborted";
CM_ SG_ 1000 EPBR_a186_externalParkAbort "Right electric parking brake: a186 external park abort";
CM_ SG_ 1000 EPBR_a187_cdpDynamic "Right electric parking brake: a187 cdp dynamic";
CM_ SG_ 1000 EPBR_a188_epbDynamic "Right electric parking brake: a188 epb dynamic";
CM_ SG_ 1000 EPBR_a189_epbDynamicParkCanceled "Right electric parking brake: a189 epb dynamic park canceled";
CM_ SG_ 1000 EPBR_a190_csmApplyDegraded "Right electric parking brake: a190 csm apply degraded";
CM_ SG_ 1000 EPBR_a191_csmReleaseDegraded "Right electric parking brake: a191 csm release degraded";
CM_ SG_ 1000 EPBR_a195_parkForDriverIsLeaving "Right electric parking brake: a195 park for driver is leaving";
CM_ SG_ 1000 EPBR_a196_freeRollModeActive "Right electric parking brake: a196 free roll mode active";
CM_ SG_ 1000 EPBR_a197_freeRollModeAtSpeed "Right electric parking brake: a197 free roll mode at speed";
CM_ SG_ 1000 EPBR_a198_holdClampComplete "Right electric parking brake: a198 hold clamp complete";
CM_ SG_ 1000 EPBR_a200_PmUnparkNotAllowed "Right electric parking brake: a200 pm unpark not allowed";
CM_ SG_ 1000 EPBR_a202_remoteEpbConfigIncompa "Right electric parking brake: a202 remote epb config incompatible";
CM_ SG_ 1000 EPBR_a203_hwBrakeTypeMismatch "Right electric parking brake: a203 hw brake type mismatch";
CM_ SG_ 1000 EPBR_a210_parkForDriverIsLeaving "Right electric parking brake: a210 park for driver is leaving debug";
CM_ SG_ 1000 EPBR_a216_SPI_MIA_debugData1 "Right electric parking brake: a216 SPI MIA debug data1";
CM_ SG_ 1000 EPBR_a217_SPI_MIA_debugData2 "Right electric parking brake: a217 SPI MIA debug data2";
CM_ SG_ 1000 EPBR_a225_epbActiveDecel "Right electric parking brake: a225 epb active decel";
CM_ SG_ 1000 EPBR_a241_diOutputLocked "Right electric parking brake: a241 di output locked";
CM_ SG_ 1000 EPBR_a242_hvOutputLocked "Right electric parking brake: a242 hv output locked";
CM_ SG_ 1000 EPBR_a243_bdwUnavailable "Right electric parking brake: a243 bdw unavailable";
CM_ SG_ 1000 EPBR_a244_WinchModeActive "Right electric parking brake: a244 winch mode active";
CM_ SG_ 1000 EPBR_a245_serviceModeActive "Signal reported by Right electric parking brake";
CM_ SG_ 1000 EPBR_a246_idleFaultApply "Right electric parking brake: a246 idle fault apply";
CM_ SG_ 1000 EPBR_a247_csmDynamicApplyRetry "Right electric parking brake: a247 csm dynamic apply retry";
CM_ SG_ 1000 EPBR_a248_csmDynamicApplyFailed "Right electric parking brake: a248 csm dynamic apply failed";
CM_ SG_ 1000 EPBR_a249_idleFaultRelease "Right electric parking brake: a249 idle fault release";
CM_ SG_ 1000 EPBR_a250_WinchModeCanceled "Right electric parking brake: a250 winch mode canceled";
CM_ SG_ 1000 EPBR_a251_currentVarianceHigh "Right electric parking brake: a251 current variance high";
CM_ SG_ 1000 EPBR_a252_winchModePending "Right electric parking brake: a252 winch mode pending";
CM_ SG_ 1000 EPBR_a253_esmReleaseBlocked "Right electric parking brake: a253 esm release blocked";
CM_ SG_ 1000 EPBR_a254_showStalkParkButtonFau "Right electric parking brake: a254 show stalk park button fault on ui";
CM_ SG_ 1000 EPBR_a256_epbSystemApply "Right electric parking brake: a256 epb system apply";
CM_ SG_ 1000 EPBR_a261_winchModeWithoutSteeri "Right electric parking brake: a261 winch mode without steering";
CM_ SG_ 1000 EPBR_a262_cannotPrepareWinchMode "Right electric parking brake: a262 cannot prepare winch mode";
CM_ SG_ 1000 EPBR_a263_epbRecoveryPark "Right electric parking brake: a263 epb recovery park";
CM_ SG_ 1000 EPBR_a264_winchModeDeactivated "Right electric parking brake: a264 winch mode deactivated";
CM_ SG_ 1000 EPBR_a272_vhclPwrStateMsmtch "Right electric parking brake: a272 vhcl pwr state msmtch";
CM_ SG_ 1000 EPBR_a300_leftRightConfusion "Right electric parking brake: a300 left right confusion";
CM_ SG_ 1000 EPBR_a301_oocSpeedViolation "Right electric parking brake: a301 ooc speed violation";
CM_ SG_ 1000 EPBR_a302_csmLongRelease "Right electric parking brake: a302 csm long release";
CM_ SG_ 1000 EPBR_a303_clampingOccuredEarly "Right electric parking brake: a303 clamping occured early";
CM_ SG_ 1000 EPBR_a304_rearSeatControllerEFus "Right electric parking brake: a304 rear seat controller e fuse trip";
CM_ SG_ 1000 EPBR_a305_premiumAmpEFuseTrip "Right electric parking brake: a305 premium amp e fuse trip";
CM_ SG_ 1000 EPBR_a330_parkForApIsLeaving "Right electric parking brake: a330 park for ap is leaving";
CM_ SG_ 1000 EPBR_a350_ensOutOfRange "Right electric parking brake: a350 ens out of range";
CM_ SG_ 1000 EPBR_a352_audioCurrentSpikeData "Right electric parking brake: a352 audio current spike data";
CM_ SG_ 1000 EPBR_a353_missingSpeedUnableToPa "Right electric parking brake: a353 missing speed unable to park";
CM_ SG_ 1000 EPBR_a354_parkedForLowBrakeFluid "Right electric parking brake: a354 parked for low brake fluid mode";
CM_ SG_ 1000 EPBR_a355_brakeHwAndEpbHwMismatc "Right electric parking brake: a355 brake hw and epb hw mismatch";
CM_ SG_ 1000 EPBR_a356_parkingForStationaryDe "Right electric parking brake: a356 parking for stationary detect";
CM_ SG_ 1000 EPBR_a357_brakesTooHotForSlope "Right electric parking brake: a357 brakes too hot for slope";
CM_ SG_ 1000 EPBR_a358_brakesTooHotForSlopeWi "Right electric parking brake: a358 brakes too hot for slope with only one epb";
CM_ SG_ 1000 EPBR_a359_seat2RControllerTrip "Right electric parking brake: a359 seat2 r controller trip";
CM_ SG_ 1000 EPBR_a360_ibstBrakeSwitchInvalid "Right electric parking brake: a360 ibst brake switch invalid";
CM_ SG_ 1000 EPBR_a361_espBrakeSwitchInvalid "Right electric parking brake: a361 esp brake switch invalid";
CM_ SG_ 1000 EPBR_a362_ibstPressedEspNotPress "Right electric parking brake: a362 ibst pressed esp not pressed mismatch";
CM_ SG_ 1000 EPBR_a363_ibstNotPressedEspPress "Right electric parking brake: a363 ibst not pressed esp pressed mismatch";
CM_ SG_ 1000 EPBR_a364_espMasterCylCompOverTh "Right electric parking brake: a364 esp master cyl comp over threshold";
CM_ SG_ 1000 EPBR_a365_TooSteepToParkWithTrai "Right electric parking brake: a365 too steep to park with trailer warning";
CM_ SG_ 1000 EPBR_a366_TooSteepToParkWithTrai "Right electric parking brake: a366 too steep to park with trailer un sec env";
CM_ SG_ 1000 EPBR_a370_imposterDetected "Right electric parking brake: a370 imposter detected";
CM_ BO_ 2024 "Right electric parking brake message: info";
CM_ SG_ 2024 EPBR_infoIndex "Right electric parking brake: info index";
CM_ SG_ 2024 EPBR_infoBuildType "Right electric parking brake: info build type";
CM_ SG_ 2024 EPBR_infoBuildConfigId "Right electric parking brake: info build config id";
CM_ SG_ 2024 EPBR_infoHardwareId "Right electric parking brake: info hardware id";
CM_ SG_ 2024 EPBR_infoComponentId "Right electric parking brake: info component id";
CM_ SG_ 2024 EPBR_infoPcbaId "Right electric parking brake: info pcba id";
CM_ SG_ 2024 EPBR_infoAssemblyId "Right electric parking brake: info assembly id; raw 255 = signal not available (SNA)";
CM_ SG_ 2024 EPBR_infoUsageId "Right electric parking brake: info usage id";
CM_ SG_ 2024 EPBR_infoSubUsageId "Right electric parking brake: info sub usage id";
CM_ SG_ 2024 EPBR_infoAppCrc "Right electric parking brake: info app crc";
CM_ SG_ 2024 EPBR_infoAppGitHash "Right electric parking brake: info app git hash";
CM_ SG_ 2024 EPBR_infoBootGitHash "Right electric parking brake: info boot git hash";
CM_ SG_ 2024 EPBR_infoPlatformType "Right electric parking brake: info platform type";
CM_ SG_ 2024 EPBR_infoBootUdsProtoVersion "Right electric parking brake: info boot uds proto version";
CM_ SG_ 2024 EPBR_infoBootCrc "Right electric parking brake: info boot crc";
CM_ BO_ 552 "Right electric parking brake message: internal status";
CM_ SG_ 552 EPBR_unitStatus "Electronic Parking Brake's unit state.";
CM_ SG_ 552 EPBR_unitFaultStatus "Right electric parking brake: unit fault status";
CM_ SG_ 552 EPBR_summonState "Right electric parking brake: summon state";
CM_ SG_ 552 EPBR_disconnected "Right electric parking brake: disconnected";
CM_ SG_ 552 EPBR_pistonTouchingRotor "Right electric parking brake: piston touching rotor";
CM_ SG_ 552 EPBR_csmFaultReason "Right electric parking brake: csm fault reason";
CM_ SG_ 552 EPBR_esmOperationTrigger "Right electric parking brake: esm operation trigger";
CM_ SG_ 552 EPBR_summonFaultReason "Error code associated with previous summon failure.";
CM_ SG_ 552 EPBR_localServiceModeActive "Signal reported by Right electric parking brake";
CM_ SG_ 552 EPBR_localCdpState "Right electric parking brake: local cdp state";
CM_ SG_ 552 EPBR_chimeRequestLocal "Right electric parking brake: chime request local";
CM_ SG_ 552 EPBR_telltaleLocal "Right electric parking brake: telltale local; raw 7 = signal not available (SNA)";
CM_ SG_ 552 EPBR_driverIsLeavingLocal "Right electric parking brake: driver is leaving local";
CM_ SG_ 552 EPBR_driverIsLeavingAnySpeedLoca "Right electric parking brake: driver is leaving any speed local";
CM_ SG_ 552 EPBR_internalCDPRequest "Right electric parking brake: internal CDP request";
CM_ SG_ 552 EPBR_esmSpeedClass "Right electric parking brake: esm speed class";
CM_ SG_ 552 EPBR_learnedEpbConfig "Right electric parking brake: learned epb config";
CM_ SG_ 552 EPBR_internalStatusCounter "Right electric parking brake: internal status counter";
CM_ SG_ 552 EPBR_internalStatusChecksum "Right electric parking brake: internal status checksum";
CM_ BO_ 742 "Right electric parking brake message: seat status3";
CM_ SG_ 742 EPBR_frontSeatCushionFanCur "Right electric parking brake: front seat cushion fan cur";
CM_ SG_ 742 EPBR_frontSeatBackrestFanCur "Right electric parking brake: front seat backrest fan cur";
CM_ SG_ 742 EPBR_frontSeatCushionFanDuty "Right electric parking brake: front seat cushion fan duty";
CM_ SG_ 742 EPBR_frontSeatCushionFanEn "Right electric parking brake: front seat cushion fan en";
CM_ SG_ 742 EPBR_frontSeatBackrestFanEn "Right electric parking brake: front seat backrest fan en";
CM_ SG_ 742 EPBR_frontSeatBackrestFanDuty "Right electric parking brake: front seat backrest fan duty";
CM_ SG_ 742 EPBR_seat2RControllerCurrent "Right electric parking brake: seat2 r controller current";
CM_ BO_ 744 "Right electric parking brake message: status";
CM_ SG_ 744 EPBR_systemStatus "Coordinated state representing the vehicle level parking brake state.";
CM_ SG_ 744 EPBR_freeRollModeStatus "Right electric parking brake: free roll mode status";
CM_ SG_ 744 EPBR_driverIsLeaving "Right electric parking brake: driver is leaving";
CM_ SG_ 744 EPBR_driverIsLeavingAnySpeed "Right electric parking brake: driver is leaving any speed";
CM_ SG_ 744 EPBR_systemCdpAvailable "Right electric parking brake: system cdp available";
CM_ SG_ 744 EPBR_chimeRequest "Right electric parking brake: chime request";
CM_ SG_ 744 EPBR_telltale "Controls the telltale illumination on the instrument cluster; raw 7 = signal not available (SNA)";
CM_ SG_ 744 EPBR_audioCurrentSpikeDetected "Right electric parking brake: audio current spike detected";
CM_ SG_ 744 EPBR_redundantBrakingEnabled "Right electric parking brake: redundant braking enabled";
CM_ SG_ 744 EPBR_summonEnabled "Right electric parking brake: summon enabled";
CM_ SG_ 744 EPBR_brakeLight "Right electric parking brake: brake light";
CM_ SG_ 744 EPBR_epbConfigMismatch "Right electric parking brake: epb config mismatch";
CM_ SG_ 744 EPBR_brakeConfirmedPressed "Right electric parking brake: brake confirmed pressed";
CM_ SG_ 744 EPBR_requestUserConfirmation "Right electric parking brake: request user confirmation";
CM_ SG_ 744 EPBR_uiWinchModeMiscBlocking "Reports the expected appearance of system error message on User Interface (UI) winch mode panel.";
CM_ SG_ 744 EPBR_winchModeActive "Right electric parking brake: winch mode active";
CM_ SG_ 744 EPBR_updateMode "Right electric parking brake: update mode";
CM_ SG_ 744 EPBR_winchModePermissive "Right electric parking brake: winch mode permissive";
CM_ SG_ 744 EPBR_winchModePending "Right electric parking brake: winch mode pending";
CM_ SG_ 744 EPBR_cdpRequest "Right electric parking brake: cdp request";
CM_ SG_ 744 EPBR_uiParkAvailable "Reports the expected availability and appearance of the park button on User Interface (UI) safety panel.";
CM_ SG_ 744 EPBR_brakeDiscWipeRequest "Right electric parking brake: brake disc wipe request; raw 3 = signal not available (SNA)";
CM_ SG_ 744 EPBR_showUiGearShifter "Right electric parking brake: show ui gear shifter";
CM_ SG_ 744 EPBR_uiWinchModeLvStatus "Reports the expected availability and appearance of Low Voltage (LV) system status on UI winch mode panel.";
CM_ SG_ 744 EPBR_contactorCycleNotNeededForW "Right electric parking brake: contactor cycle not needed for winch entry";
CM_ SG_ 744 EPBR_autonomyBehavior "Right electric parking brake: autonomy behavior";
CM_ SG_ 744 EPBR_showStalkFaultedOnUi "Right electric parking brake: show stalk faulted on ui";
CM_ SG_ 744 EPBR_espPowerRequest "Right electric parking brake: esp power request";
CM_ SG_ 744 EPBR_okToPark "Right electric parking brake: ok to park";
CM_ SG_ 744 EPBR_hornRequest "Right electric parking brake: horn request";
CM_ SG_ 744 EPBR_winchModeAvailable "Right electric parking brake: winch mode available";
CM_ SG_ 744 EPBR_bothDisconnected "Right electric parking brake: both disconnected";
CM_ SG_ 744 EPBR_blockDrive "Right electric parking brake: block drive";
CM_ SG_ 744 EPBR_statusCounter "Right electric parking brake: status counter";
CM_ SG_ 744 EPBR_statusChecksum "Right electric parking brake: status checksum";
CM_ BO_ 1575 "Right electric parking brake message: uds response";
CM_ SG_ 1575 EPBR_udsResponseData_H "Right electric parking brake: uds response data h";
CM_ SG_ 1575 EPBR_udsResponseData_L "Right electric parking brake: uds response data l";
CM_ BO_ 981 "Electronic stability control message: alert matrix";
CM_ SG_ 981 ESP_matrixIndex "Electronic stability control: matrix index";
CM_ SG_ 981 ESP_a001_ecuGenericFault "Electronic stability control: a001 ecu generic fault";
CM_ SG_ 981 ESP_a002_valvesGenericFault "Electronic stability control: a002 valves generic fault";
CM_ SG_ 981 ESP_a003_outletValvesFault "Electronic stability control: a003 outlet valves fault";
CM_ SG_ 981 ESP_a004_inletValvesFault "Electronic stability control: a004 inlet valves fault";
CM_ SG_ 981 ESP_a005_HSVValvesFault "Electronic stability control: a005 HSV valves fault";
CM_ SG_ 981 ESP_a006_USVValvesFault "Electronic stability control: a006 USV valves fault";
CM_ SG_ 981 ESP_a007_pumpMotorFault "Electronic stability control: a007 pump motor fault";
CM_ SG_ 981 ESP_a008_pumpMotor12VsupplyLow "Electronic stability control: a008 pump motor12 vsupply low";
CM_ SG_ 981 ESP_a009_12VHardUndervoltage "Electronic stability control: a009 12 v hard undervoltage";
CM_ SG_ 981 ESP_a010_12VUndervoltage "Electronic stability control: a010 12 v undervoltage";
CM_ SG_ 981 ESP_a011_12VSystemUndervoltage "Electronic stability control: a011 12 v system undervoltage";
CM_ SG_ 981 ESP_a012_netUndervoltage "Electronic stability control: a012 net undervoltage";
CM_ SG_ 981 ESP_a013_valveRelayUndervoltage "Electronic stability control: a013 valve relay undervoltage";
CM_ SG_ 981 ESP_a014_WSSSupplyUndervoltage "Electronic stability control: a014 WSS supply undervoltage";
CM_ SG_ 981 ESP_a015_12VSupplyOvervoltage "Electronic stability control: a015 12 v supply overvoltage";
CM_ SG_ 981 ESP_a016_12VSystemOvervoltage "Electronic stability control: a016 12 v system overvoltage";
CM_ SG_ 981 ESP_a017_netOvervoltage "Electronic stability control: a017 net overvoltage";
CM_ SG_ 981 ESP_a018_WSSSignFrontAxle "Electronic stability control: a018 WSS sign front axle";
CM_ SG_ 981 ESP_a019_WSSSignRearAxle "Electronic stability control: a019 WSS sign rear axle";
CM_ SG_ 981 ESP_a020_WSSGenericTempFault "Electronic stability control: a020 WSS generic temp fault";
CM_ SG_ 981 ESP_a021_WSSGeneralVDiffFault "Electronic stability control: a021 WSS general v diff fault";
CM_ SG_ 981 ESP_a022_WSSDirectionFault "Electronic stability control: a022 WSS direction fault";
CM_ SG_ 981 ESP_a023_WSSSeveralSuspected "Electronic stability control: a023 WSS several suspected";
CM_ SG_ 981 ESP_a024_WSSReverseCurrent "Electronic stability control: a024 WSS reverse current";
CM_ SG_ 981 ESP_a025_FrLWSSOpenOrShortToGnd "Electronic stability control: a025 fr LWSS open or short to gnd";
CM_ SG_ 981 ESP_a026_FrLWSSShortTo12V "Electronic stability control: a026 fr LWSS short to12 v";
CM_ SG_ 981 ESP_a027_FrLWSSLineInterruption "Electronic stability control: a027 fr LWSS line interruption";
CM_ SG_ 981 ESP_a028_FrLWSSMaxSpeedExceeded "Electronic stability control: a028 fr LWSS max speed exceeded";
CM_ SG_ 981 ESP_a029_FrLWSSTooManyPulses "Electronic stability control: a029 fr LWSS too many pulses";
CM_ SG_ 981 ESP_a030_FrLWSSLostSignal "Electronic stability control: a030 fr LWSS lost signal";
CM_ SG_ 981 ESP_a031_FrLWSSNoPulsesDetected "Electronic stability control: a031 fr LWSS no pulses detected";
CM_ SG_ 981 ESP_a032_FrLWSSWrongSensorType "Electronic stability control: a032 fr LWSS wrong sensor type";
CM_ SG_ 981 ESP_a033_FrLWSSSignalNoise "Electronic stability control: a033 fr LWSS signal noise";
CM_ SG_ 981 ESP_a034_FrLWSSVDiffFault "Electronic stability control: a034 fr LWSSV diff fault";
CM_ SG_ 981 ESP_a035_FrLWSSDirectionFault "Electronic stability control: a035 fr LWSS direction fault";
CM_ SG_ 981 ESP_a036_FrLWSSLargeAirGap "Electronic stability control: a036 fr LWSS large air gap";
CM_ SG_ 981 ESP_a037_FrLWSSSupplyShortToGnd "Electronic stability control: a037 fr LWSS supply short to gnd";
CM_ SG_ 981 ESP_a038_FrLWSSGeneralFault "Electronic stability control: a038 fr LWSS general fault";
CM_ SG_ 981 ESP_a039_FrRWSSOpenOrShortToGnd "Electronic stability control: a039 fr RWSS open or short to gnd";
CM_ SG_ 981 ESP_a040_FrRWSSShortTo12V "Electronic stability control: a040 fr RWSS short to12 v";
CM_ SG_ 981 ESP_a041_FrRWSSLineInterruption "Electronic stability control: a041 fr RWSS line interruption";
CM_ SG_ 981 ESP_a042_FrRWSSMaxSpeedExceeded "Electronic stability control: a042 fr RWSS max speed exceeded";
CM_ SG_ 981 ESP_a043_FrRWSSTooManyPulses "Electronic stability control: a043 fr RWSS too many pulses";
CM_ SG_ 981 ESP_a044_FrRWSSLostSignal "Electronic stability control: a044 fr RWSS lost signal";
CM_ SG_ 981 ESP_a045_FrRWSSNoPulsesDetected "Electronic stability control: a045 fr RWSS no pulses detected";
CM_ SG_ 981 ESP_a046_FrRWSSWrongSensorType "Electronic stability control: a046 fr RWSS wrong sensor type";
CM_ SG_ 981 ESP_a047_FrRWSSSignalNoise "Electronic stability control: a047 fr RWSS signal noise";
CM_ SG_ 981 ESP_a048_FrRWSSVDiffFault "Electronic stability control: a048 fr RWSSV diff fault";
CM_ SG_ 981 ESP_a049_FrRWSSDirectionFault "Electronic stability control: a049 fr RWSS direction fault";
CM_ SG_ 981 ESP_a050_FrRWSSLargeAirGap "Electronic stability control: a050 fr RWSS large air gap";
CM_ SG_ 981 ESP_a051_FrRWSSSupplyShortToGnd "Electronic stability control: a051 fr RWSS supply short to gnd";
CM_ SG_ 981 ESP_a052_FrRWSSGeneralFault "Electronic stability control: a052 fr RWSS general fault";
CM_ SG_ 981 ESP_a053_ReLWSSOpenOrShortToGnd "Electronic stability control: a053 re LWSS open or short to gnd";
CM_ SG_ 981 ESP_a054_ReLWSSShortTo12V "Electronic stability control: a054 re LWSS short to12 v";
CM_ SG_ 981 ESP_a055_ReLWSSLineInterruption "Electronic stability control: a055 re LWSS line interruption";
CM_ SG_ 981 ESP_a056_ReLWSSMaxSpeedExceeded "Electronic stability control: a056 re LWSS max speed exceeded";
CM_ SG_ 981 ESP_a057_ReLWSSTooManyPulses "Electronic stability control: a057 re LWSS too many pulses";
CM_ SG_ 981 ESP_a058_ReLWSSLostSignal "Electronic stability control: a058 re LWSS lost signal";
CM_ SG_ 981 ESP_a059_ReLWSSNoPulsesDetected "Electronic stability control: a059 re LWSS no pulses detected";
CM_ SG_ 981 ESP_a060_ReLWSSWrongSensorType "Electronic stability control: a060 re LWSS wrong sensor type";
CM_ SG_ 981 ESP_a061_ReLWSSSignalNoise "Electronic stability control: a061 re LWSS signal noise";
CM_ SG_ 981 ESP_a062_ReLWSSVDiffFault "Electronic stability control: a062 re LWSSV diff fault";
CM_ SG_ 981 ESP_a063_ReLWSSDirectionFault "Electronic stability control: a063 re LWSS direction fault";
CM_ SG_ 981 ESP_a064_ReLWSSLargeAirGap "Electronic stability control: a064 re LWSS large air gap";
CM_ SG_ 981 ESP_a065_ReLWSSSupplyShortToGnd "Electronic stability control: a065 re LWSS supply short to gnd";
CM_ SG_ 981 ESP_a066_ReLWSSGeneralFault "Electronic stability control: a066 re LWSS general fault";
CM_ SG_ 981 ESP_a067_ReRWSSOpenOrShortToGnd "Electronic stability control: a067 re RWSS open or short to gnd";
CM_ SG_ 981 ESP_a068_ReRWSSShortTo12V "Electronic stability control: a068 re RWSS short to12 v";
CM_ SG_ 981 ESP_a069_ReRWSSLineInterruption "Electronic stability control: a069 re RWSS line interruption";
CM_ SG_ 981 ESP_a070_ReRWSSMaxSpeedExceeded "Electronic stability control: a070 re RWSS max speed exceeded";
CM_ SG_ 981 ESP_a071_ReRWSSTooManyPulses "Electronic stability control: a071 re RWSS too many pulses";
CM_ SG_ 981 ESP_a072_ReRWSSLostSignal "Electronic stability control: a072 re RWSS lost signal";
CM_ SG_ 981 ESP_a073_ReRWSSNoPulsesDetected "Electronic stability control: a073 re RWSS no pulses detected";
CM_ SG_ 981 ESP_a074_ReRWSSWrongSensorType "Electronic stability control: a074 re RWSS wrong sensor type";
CM_ SG_ 981 ESP_a075_ReRWSSSignalNoise "Electronic stability control: a075 re RWSS signal noise";
CM_ SG_ 981 ESP_a076_ReRWSSVDiffFault "Electronic stability control: a076 re RWSSV diff fault";
CM_ SG_ 981 ESP_a077_ReRWSSDirectionFault "Electronic stability control: a077 re RWSS direction fault";
CM_ SG_ 981 ESP_a078_ReRWSSLargeAirGap "Electronic stability control: a078 re RWSS large air gap";
CM_ SG_ 981 ESP_a079_ReRWSSSupplyShortToGnd "Electronic stability control: a079 re RWSS supply short to gnd";
CM_ SG_ 981 ESP_a080_ReRWSSGeneralFault "Electronic stability control: a080 re RWSS general fault";
CM_ SG_ 981 ESP_a081_PressureSensorShort "Electronic stability control: a081 pressure sensor short";
CM_ SG_ 981 ESP_a082_PMCSensorOffsetHigh "Electronic stability control: a082 PMC sensor offset high";
CM_ SG_ 981 ESP_a083_PMCSensorFault "Electronic stability control: a083 PMC sensor fault";
CM_ SG_ 981 ESP_a084_BrakeFluidReservoirLow "Electronic stability control: a084 brake fluid reservoir low";
CM_ SG_ 981 ESP_a085_BrakeSwitchStuckHigh "Electronic stability control: a085 brake switch stuck high";
CM_ SG_ 981 ESP_a086_BrakeSwitchImplausible1 "Electronic stability control: a086 brake switch implausible1";
CM_ SG_ 981 ESP_a087_BrakeSwitchImplausible3 "Electronic stability control: a087 brake switch implausible3";
CM_ SG_ 981 ESP_a088_absContinuousControl "Electronic stability control: a088 abs continuous control";
CM_ SG_ 981 ESP_a089_absNoPressureIncrease "Electronic stability control: a089 abs no pressure increase";
CM_ SG_ 981 ESP_a090_vdcContinuousControl "Electronic stability control: a090 vdc continuous control";
CM_ SG_ 981 ESP_a091_CANUndervoltage "Electronic stability control: a091 CAN undervoltage";
CM_ SG_ 981 ESP_a092_CANOvervoltage "Electronic stability control: a092 CAN overvoltage";
CM_ SG_ 981 ESP_a093_partyBusOff "Electronic stability control: a093 party bus off";
CM_ SG_ 981 ESP_a094_partyBusPassive "Electronic stability control: a094 party bus passive";
CM_ SG_ 981 ESP_a095_chassisBusOff "Electronic stability control: a095 chassis bus off";
CM_ SG_ 981 ESP_a096_chassisBusPassive "Electronic stability control: a096 chassis bus passive";
CM_ SG_ 981 ESP_a097_tcsRefSpeedNotInit "Electronic stability control: a097 tcs ref speed not init";
CM_ SG_ 981 ESP_a098_vdcRefSpeedNotInit "Electronic stability control: a098 vdc ref speed not init";
CM_ SG_ 981 ESP_a099_brakeTempModelOverheat "Electronic stability control: a099 brake temp model overheat";
CM_ SG_ 981 ESP_a100_brakeTempModelDisabled "Electronic stability control: a100 brake temp model disabled";
CM_ SG_ 981 ESP_a101_ebdFault "Electronic stability control: a101 ebd fault";
CM_ SG_ 981 ESP_a102_absFault "Electronic stability control: a102 abs fault";
CM_ SG_ 981 ESP_a103_stabilityControlFault "Electronic stability control: a103 stability control fault";
CM_ SG_ 981 ESP_a104_hbcEnabled "Electronic stability control: a104 hbc enabled";
CM_ SG_ 981 ESP_a105_ebrFault "Electronic stability control: a105 ebr fault";
CM_ SG_ 981 ESP_a106_vdcActuatorFault "Electronic stability control: a106 vdc actuator fault";
CM_ SG_ 981 ESP_a107_reserved107 "Electronic stability control: a107 reserved107";
CM_ SG_ 981 ESP_a108_reserved108 "Electronic stability control: a108 reserved108";
CM_ SG_ 981 ESP_a109_reserved109 "Electronic stability control: a109 reserved109";
CM_ SG_ 981 ESP_a110_rollerBenchActive "Electronic stability control: a110 roller bench active";
CM_ SG_ 981 ESP_a111_absActive "Electronic stability control: a111 abs active";
CM_ SG_ 981 ESP_a112_espActive "Electronic stability control: a112 esp active";
CM_ SG_ 981 ESP_a113_btcActive "Electronic stability control: a113 btc active";
CM_ SG_ 981 ESP_a114_tvdcActive "Electronic stability control: a114 tvdc active";
CM_ SG_ 981 ESP_a115_ebdActive "Electronic stability control: a115 ebd active";
CM_ SG_ 981 ESP_a116_tsmActive "Electronic stability control: a116 tsm active";
CM_ SG_ 981 ESP_a117_hbaActive "Electronic stability control: a117 hba active";
CM_ SG_ 981 ESP_a118_hfcActive "Electronic stability control: a118 hfc active";
CM_ SG_ 981 ESP_a119_hbbActive "Electronic stability control: a119 hbb active";
CM_ SG_ 981 ESP_a120_rmiActive "Electronic stability control: a120 rmi active";
CM_ SG_ 981 ESP_a121_regenTcActive "Electronic stability control: a121 regen tc active";
CM_ SG_ 981 ESP_a122_bdwActive "Electronic stability control: a122 bdw active";
CM_ SG_ 981 ESP_a123_ebrActive "Electronic stability control: a123 ebr active";
CM_ SG_ 981 ESP_a124_ebrSkidActive "Electronic stability control: a124 ebr skid active";
CM_ SG_ 981 ESP_a125_reserved125 "Electronic stability control: a125 reserved125";
CM_ SG_ 981 ESP_a126_reserved126 "Electronic stability control: a126 reserved126";
CM_ SG_ 981 ESP_a127_reserved127 "Electronic stability control: a127 reserved127";
CM_ SG_ 981 ESP_a128_reserved128 "Electronic stability control: a128 reserved128";
CM_ SG_ 981 ESP_a129_reserved129 "Electronic stability control: a129 reserved129";
CM_ SG_ 981 ESP_a130_EPAS3PsysStatusTimeout "Electronic stability control: a130 EPAS3 psys status timeout";
CM_ SG_ 981 ESP_a131_EPAS3PsysStatusDLC "Electronic stability control: a131 EPAS3 psys status DLC";
CM_ SG_ 981 ESP_a132_EPAS3PsysStatusChecksum "Electronic stability control: a132 EPAS3 psys status checksum";
CM_ SG_ 981 ESP_a133_EPAS3PsysStatusCounter "Electronic stability control: a133 EPAS3 psys status counter";
CM_ SG_ 981 ESP_a134_steeringAngleInvalid "Electronic stability control: a134 steering angle invalid";
CM_ SG_ 981 ESP_a135_steeringAngleNoCenter "Electronic stability control: a135 steering angle no center";
CM_ SG_ 981 ESP_a136_steeringAngleFrozen "Electronic stability control: a136 steering angle frozen";
CM_ SG_ 981 ESP_a137_steeringOffsetTooLarge "Electronic stability control: a137 steering offset too large";
CM_ SG_ 981 ESP_a138_steeringAngleImplaus "Electronic stability control: a138 steering angle implaus";
CM_ SG_ 981 ESP_a139_steeringAngleWrongSign "Electronic stability control: a139 steering angle wrong sign";
CM_ SG_ 981 ESP_a140_RCMInertial1Timeout "Electronic stability control: a140 RCM inertial1 timeout";
CM_ SG_ 981 ESP_a141_RCMInertial1DLC "Electronic stability control: a141 RCM inertial1 DLC";
CM_ SG_ 981 ESP_a142_RCMInertial1Checksum "Electronic stability control: a142 RCM inertial1 checksum";
CM_ SG_ 981 ESP_a143_RCMInertial1Counter "Electronic stability control: a143 RCM inertial1 counter";
CM_ SG_ 981 ESP_a144_yawMaxLatency "Electronic stability control: a144 yaw max latency";
CM_ SG_ 981 ESP_a145_yawInitFault "Electronic stability control: a145 yaw init fault";
CM_ SG_ 981 ESP_a146_yawInvalidValue "Electronic stability control: a146 yaw invalid value";
CM_ SG_ 981 ESP_a147_yawSensorNotAvailable "Electronic stability control: a147 yaw sensor not available";
CM_ SG_ 981 ESP_a148_yawSignalFault "Electronic stability control: a148 yaw signal fault";
CM_ SG_ 981 ESP_a149_yawInvalidSign "Electronic stability control: a149 yaw invalid sign";
CM_ SG_ 981 ESP_a150_yawImplausible "Electronic stability control: a150 yaw implausible";
CM_ SG_ 981 ESP_a151_RCMInertial2Timeout "Electronic stability control: a151 RCM inertial2 timeout";
CM_ SG_ 981 ESP_a152_RCMInertial2DLC "Electronic stability control: a152 RCM inertial2 DLC";
CM_ SG_ 981 ESP_a153_RCMInertial2Checksum "Electronic stability control: a153 RCM inertial2 checksum";
CM_ SG_ 981 ESP_a154_RCMInertial2Counter "Electronic stability control: a154 RCM inertial2 counter";
CM_ SG_ 981 ESP_a155_ayMaxLatency "Electronic stability control: a155 ay max latency";
CM_ SG_ 981 ESP_a156_ayInitFault "Electronic stability control: a156 ay init fault";
CM_ SG_ 981 ESP_a157_ayInvalidValue "Electronic stability control: a157 ay invalid value";
CM_ SG_ 981 ESP_a158_aySensorNotAvailable "Electronic stability control: a158 ay sensor not available";
CM_ SG_ 981 ESP_a159_aySignalFault "Electronic stability control: a159 ay signal fault";
CM_ SG_ 981 ESP_a160_ayRangeExceeded "Electronic stability control: a160 ay range exceeded";
CM_ SG_ 981 ESP_a161_ayOffsetExceeded "Electronic stability control: a161 ay offset exceeded";
CM_ SG_ 981 ESP_a162_ayImplausible "Electronic stability control: a162 ay implausible";
CM_ SG_ 981 ESP_a163_axMaxLatency "Electronic stability control: a163 ax max latency";
CM_ SG_ 981 ESP_a164_axInitFault "Electronic stability control: a164 ax init fault";
CM_ SG_ 981 ESP_a165_axInvalidValue "Electronic stability control: a165 ax invalid value";
CM_ SG_ 981 ESP_a166_axSensorNotAvailable "Electronic stability control: a166 ax sensor not available";
CM_ SG_ 981 ESP_a167_axSignalFault "Electronic stability control: a167 ax signal fault";
CM_ SG_ 981 ESP_a168_axRangeExceeded "Electronic stability control: a168 ax range exceeded";
CM_ SG_ 981 ESP_a169_axOffsetExceeded "Electronic stability control: a169 ax offset exceeded";
CM_ SG_ 981 ESP_a170_axSignalFrozen "Electronic stability control: a170 ax signal frozen";
CM_ SG_ 981 ESP_a171_axImplausible "Electronic stability control: a171 ax implausible";
CM_ SG_ 981 ESP_a172_IBSTparty1Timeout "Electronic stability control: a172 IBS tparty1 timeout";
CM_ SG_ 981 ESP_a173_IBSTparty1DLC "Electronic stability control: a173 IBS tparty1 DLC";
CM_ SG_ 981 ESP_a174_IBSTparty1Checksum "Electronic stability control: a174 IBS tparty1 checksum";
CM_ SG_ 981 ESP_a175_IBSTparty1Counter "Electronic stability control: a175 IBS tparty1 counter";
CM_ SG_ 981 ESP_a176_IBSTEBRNotAvailable "Electronic stability control: a176 IBSTEBR not available";
CM_ SG_ 981 ESP_a177_IBSTOutputRodDrvInvalid "Electronic stability control: a177 IBST output rod drv invalid";
CM_ SG_ 981 ESP_a178_IBSTOutputRodActInvalid "Electronic stability control: a178 IBST output rod act invalid";
CM_ SG_ 981 ESP_a179_IBSTparty2Timeout "Electronic stability control: a179 IBS tparty2 timeout";
CM_ SG_ 981 ESP_a180_IBSTparty2Checksum "Electronic stability control: a180 IBS tparty2 checksum";
CM_ SG_ 981 ESP_a181_IBSTparty2DLC "Electronic stability control: a181 IBS tparty2 DLC";
CM_ SG_ 981 ESP_a182_IBSTparty2Counter "Electronic stability control: a182 IBS tparty2 counter";
CM_ SG_ 981 ESP_a183_IBSTStatusOff "Electronic stability control: a183 IBST status off";
CM_ SG_ 981 ESP_a184_IBSTpRunoutInvalid "Electronic stability control: a184 IBS tp runout invalid";
CM_ SG_ 981 ESP_a185_IBSTFeedforwardBackup "Electronic stability control: a185 IBST feedforward backup";
CM_ SG_ 981 ESP_a186_IBSTBrakeAppliedInvalid "Electronic stability control: a186 IBST brake applied invalid";
CM_ SG_ 981 ESP_a187_DIbtcRequestTimeout "Electronic stability control: a187 d ibtc request timeout";
CM_ SG_ 981 ESP_a188_DIbtcRequestDLC "Electronic stability control: a188 d ibtc request DLC";
CM_ SG_ 981 ESP_a189_DIbtcRequestChecksum "Electronic stability control: a189 d ibtc request checksum";
CM_ SG_ 981 ESP_a190_DIbtcRequestCounter "Electronic stability control: a190 d ibtc request counter";
CM_ SG_ 981 ESP_a191_DIchassisControlTimeout "Electronic stability control: a191 d ichassis control timeout";
CM_ SG_ 981 ESP_a192_DIchassisControlDLC "Electronic stability control: a192 d ichassis control DLC";
CM_ SG_ 981 ESP_a193_DIchassisControlChecksu "Electronic stability control: a193 d ichassis control checksum";
CM_ SG_ 981 ESP_a194_DIchassisControlCounter "Electronic stability control: a194 d ichassis control counter";
CM_ SG_ 981 ESP_a195_ptcStateInvalid "Electronic stability control: a195 ptc state invalid";
CM_ SG_ 981 ESP_a196_DIsystemStatusTimeout "Electronic stability control: a196 d isystem status timeout";
CM_ SG_ 981 ESP_a197_DIsystemStatusDLC "Electronic stability control: a197 d isystem status DLC";
CM_ SG_ 981 ESP_a198_DIsystemStatusChecksum "Electronic stability control: a198 d isystem status checksum";
CM_ SG_ 981 ESP_a199_DIsystemStatusCounter "Electronic stability control: a199 d isystem status counter";
CM_ SG_ 981 ESP_a200_reverseGearStuckHigh "Electronic stability control: a200 reverse gear stuck high";
CM_ SG_ 981 ESP_a201_reverseGearStuckLow "Electronic stability control: a201 reverse gear stuck low";
CM_ SG_ 981 ESP_a202_accelPedalInvalid "Electronic stability control: a202 accel pedal invalid";
CM_ SG_ 981 ESP_a203_DItorqueTimeout "Electronic stability control: a203 d itorque timeout";
CM_ SG_ 981 ESP_a204_DItorqueDLC "Electronic stability control: a204 d itorque DLC";
CM_ SG_ 981 ESP_a205_DItorqueChecksum "Electronic stability control: a205 d itorque checksum";
CM_ SG_ 981 ESP_a206_DItorqueCounter "Electronic stability control: a206 d itorque counter";
CM_ SG_ 981 ESP_a207_DITorqueCommandInvalid "Electronic stability control: a207 DI torque command invalid";
CM_ SG_ 981 ESP_a208_DIRPMInvalid "Electronic stability control: a208 DIRPM invalid";
CM_ SG_ 981 ESP_a209_DITorqueActualInvalid "Electronic stability control: a209 DI torque actual invalid";
CM_ SG_ 981 ESP_a210_DIStorqueTimeout "Electronic stability control: a210 DI storque timeout";
CM_ SG_ 981 ESP_a211_DIStorqueDLC "Electronic stability control: a211 DI storque DLC";
CM_ SG_ 981 ESP_a212_DIStorqueChecksum "Electronic stability control: a212 DI storque checksum";
CM_ SG_ 981 ESP_a213_DIStorqueCounter "Electronic stability control: a213 DI storque counter";
CM_ SG_ 981 ESP_a214_DISTorqueCommandInvalid "Electronic stability control: a214 DIS torque command invalid";
CM_ SG_ 981 ESP_a215_DISRPMInvalid "Electronic stability control: a215 DISRPM invalid";
CM_ SG_ 981 ESP_a216_DISTorqueActualInvalid "Electronic stability control: a216 DIS torque actual invalid";
CM_ SG_ 981 ESP_a217_DIvdcLeftTimeout "Electronic stability control: a217 d ivdc left timeout";
CM_ SG_ 981 ESP_a218_DIvdcLeftDLC "Electronic stability control: a218 d ivdc left DLC";
CM_ SG_ 981 ESP_a219_DIvdcLeftChecksum "Electronic stability control: a219 d ivdc left checksum";
CM_ SG_ 981 ESP_a220_DIvdcLeftCounter "Electronic stability control: a220 d ivdc left counter";
CM_ SG_ 981 ESP_a221_DIvdcRightTimeout "Electronic stability control: a221 d ivdc right timeout";
CM_ SG_ 981 ESP_a222_DIvdcRightDLC "Electronic stability control: a222 d ivdc right DLC";
CM_ SG_ 981 ESP_a223_DIvdcRightChecksum "Electronic stability control: a223 d ivdc right checksum";
CM_ SG_ 981 ESP_a224_DIvdcRightCounter "Electronic stability control: a224 d ivdc right counter";
CM_ SG_ 981 ESP_a225_configMismatch "Electronic stability control: a225 config mismatch";
CM_ SG_ 981 ESP_a226_bdwRequestInvalid "Electronic stability control: a226 bdw request invalid";
CM_ SG_ 981 ESP_a227_bdwRequestActiveInvalid "Electronic stability control: a227 bdw request active invalid";
CM_ SG_ 981 ESP_a228_GTWvinTimeout "Electronic stability control: a228 GT wvin timeout";
CM_ SG_ 981 ESP_a229_GTWvinDLC "Electronic stability control: a229 GT wvin DLC";
CM_ SG_ 981 ESP_a230_vinNotLearned "Electronic stability control: a230 vin not learned";
CM_ SG_ 981 ESP_a231_storedVINMismatch "Electronic stability control: a231 stored VIN mismatch";
CM_ SG_ 981 ESP_a232_PMstate2Timeout "Electronic stability control: a232 p mstate2 timeout";
CM_ SG_ 981 ESP_a233_PMstate2Checksum "Electronic stability control: a233 p mstate2 checksum";
CM_ SG_ 981 ESP_a234_PMstate2DLC "Electronic stability control: a234 p mstate2 DLC";
CM_ SG_ 981 ESP_a235_PMstate2Counter "Electronic stability control: a235 p mstate2 counter";
CM_ SG_ 981 ESP_a236_ebrCommandStateInvalid "Electronic stability control: a236 ebr command state invalid";
CM_ SG_ 981 ESP_a237_vdcCommandStateInvalid "Electronic stability control: a237 vdc command state invalid";
CM_ SG_ 981 ESP_a238_UIodoTimeout "Electronic stability control: a238 u iodo timeout";
CM_ SG_ 981 ESP_a239_UIodoDLC "Electronic stability control: a239 u iodo DLC";
CM_ SG_ 981 ESP_a240_LVPowerStateTimeout "Electronic stability control: a240 LV power state timeout";
CM_ SG_ 981 ESP_a241_LVPowerStateChecksum "Electronic stability control: a241 LV power state checksum";
CM_ SG_ 981 ESP_a242_LVPowerStateDLC "Electronic stability control: a242 LV power state DLC";
CM_ SG_ 981 ESP_a243_LVPowerStateCounter "Electronic stability control: a243 LV power state counter";
CM_ SG_ 981 ESP_a244_LVOffStateInvalid "Electronic stability control: a244 LV off state invalid";
CM_ SG_ 981 ESP_a245_LVGoingDownStateInvalid "Electronic stability control: a245 LV going down state invalid";
CM_ SG_ 981 ESP_a246_VCFRONTsensorTimeout "Electronic stability control: a246 VCFRON tsensor timeout";
CM_ SG_ 981 ESP_a247_VCFRONTsensorDLC "Electronic stability control: a247 VCFRON tsensor DLC";
CM_ SG_ 981 ESP_a248_vdcBrkeTrqTarFrLInvalid "Electronic stability control: a248 vdc brke trq tar fr l invalid";
CM_ SG_ 981 ESP_a249_vdcBrkeTrqTarFrRInvalid "Electronic stability control: a249 vdc brke trq tar fr r invalid";
CM_ SG_ 981 ESP_a250_vdcBrkeTrqTarReLInvalid "Electronic stability control: a250 vdc brke trq tar re l invalid";
CM_ SG_ 981 ESP_a251_vdcBrkeTrqTarReRInvalid "Electronic stability control: a251 vdc brke trq tar re r invalid";
CM_ SG_ 981 ESP_a252_vdcWhlSlipLimFrLInvalid "Electronic stability control: a252 vdc whl slip lim fr l invalid";
CM_ SG_ 981 ESP_a253_vdcWhlSlipLimFrRInvalid "Electronic stability control: a253 vdc whl slip lim fr r invalid";
CM_ SG_ 981 ESP_a254_vdcWhlSlipLimReLInvalid "Electronic stability control: a254 vdc whl slip lim re l invalid";
CM_ SG_ 981 ESP_a255_vdcWhlSlipLimReRInvalid "Electronic stability control: a255 vdc whl slip lim re r invalid";
CM_ SG_ 981 ESP_a256_epbmStatusTimeout "Electronic stability control: a256 epbm status timeout";
CM_ SG_ 981 ESP_a257_epbmStatusChecksum "Electronic stability control: a257 epbm status checksum";
CM_ SG_ 981 ESP_a258_epbmStatusDLC "Electronic stability control: a258 epbm status DLC";
CM_ SG_ 981 ESP_a259_epbmStatusCounter "Electronic stability control: a259 epbm status counter";
CM_ SG_ 981 ESP_a260_epblStatusTimeout "Electronic stability control: a260 epbl status timeout";
CM_ SG_ 981 ESP_a261_epblStatusChecksum "Electronic stability control: a261 epbl status checksum";
CM_ SG_ 981 ESP_a262_epblStatusDLC "Electronic stability control: a262 epbl status DLC";
CM_ SG_ 981 ESP_a263_epblStatusCounter "Electronic stability control: a263 epbl status counter";
CM_ SG_ 981 ESP_a264_pumpSpeedLimitInvalid "Electronic stability control: a264 pump speed limit invalid";
CM_ SG_ 981 ESP_a265_DIRELtorqueTimeout "Electronic stability control: a265 DIRE ltorque timeout";
CM_ SG_ 981 ESP_a266_DIRELtorqueDLC "Electronic stability control: a266 DIRE ltorque DLC";
CM_ SG_ 981 ESP_a267_DIRELtorqueChecksum "Electronic stability control: a267 DIRE ltorque checksum";
CM_ SG_ 981 ESP_a268_DIRELtorqueCounter "Electronic stability control: a268 DIRE ltorque counter";
CM_ SG_ 981 ESP_a269_DIRELTorqueCommandInval "Electronic stability control: a269 DIREL torque command invalid";
CM_ SG_ 981 ESP_a270_DIRELRPMInvalid "Electronic stability control: a270 DIRELRPM invalid";
CM_ SG_ 981 ESP_a271_DIRELTorqueActualInvali "Electronic stability control: a271 DIREL torque actual invalid";
CM_ SG_ 981 ESP_a272_DIRERtorqueTimeout "Electronic stability control: a272 DIRE rtorque timeout";
CM_ SG_ 981 ESP_a273_DIRERtorqueDLC "Electronic stability control: a273 DIRE rtorque DLC";
CM_ SG_ 981 ESP_a274_DIRERtorqueChecksum "Electronic stability control: a274 DIRE rtorque checksum";
CM_ SG_ 981 ESP_a275_DIRERtorqueCounter "Electronic stability control: a275 DIRE rtorque counter";
CM_ SG_ 981 ESP_a276_DIRERTorqueCommandInval "Electronic stability control: a276 DIRER torque command invalid";
CM_ SG_ 981 ESP_a277_DIRERRPMInvalid "Electronic stability control: a277 DIRERRPM invalid";
CM_ SG_ 981 ESP_a278_DIRERTorqueActualInvali "Electronic stability control: a278 DIRER torque actual invalid";
CM_ SG_ 981 ESP_a279_lifetimeManagementOverr "Electronic stability control: a279 lifetime management overrun";
CM_ SG_ 981 ESP_a280_trackModeABSEnabled "Electronic stability control: a280 track mode ABS enabled";
CM_ SG_ 981 ESP_a281_trackModeABSdisabled "Electronic stability control: a281 track mode AB sdisabled";
CM_ SG_ 981 ESP_a282_trackModeABSRequestInva "Electronic stability control: a282 track mode ABS request invalid";
CM_ SG_ 981 ESP_a283_secondaryCollisionMitig "Electronic stability control: a283 secondary collision mitigation active";
CM_ SG_ 981 ESP_a284_scmRequestInvalidChecks "Electronic stability control: a284 scm request invalid checksum";
CM_ SG_ 981 ESP_a285_scmRequestDLC "Electronic stability control: a285 scm request DLC";
CM_ SG_ 981 ESP_a286_hydroplaneDetected "Electronic stability control: a286 hydroplane detected";
CM_ SG_ 981 ESP_a287_failedBrakeCircuitDetec "Electronic stability control: a287 failed brake circuit detected";
CM_ SG_ 981 ESP_a288_leftBusOff "Electronic stability control: a288 left bus off";
CM_ SG_ 981 ESP_a289_leftBusPassive "Electronic stability control: a289 left bus passive";
CM_ SG_ 981 ESP_a290_brakeBusOff "Electronic stability control: a290 brake bus off";
CM_ SG_ 981 ESP_a291_brakeBusPassive "Electronic stability control: a291 brake bus passive";
CM_ SG_ 981 ESP_a292_PEPSstatusTimeout "Electronic stability control: a292 PEP sstatus timeout";
CM_ SG_ 981 ESP_a293_PEPSstatusDLC "Electronic stability control: a293 PEP sstatus DLC";
CM_ SG_ 981 ESP_a294_PEPSstatusChecksum "Electronic stability control: a294 PEP sstatus checksum";
CM_ SG_ 981 ESP_a295_PEPSstatusCounter "Electronic stability control: a295 PEP sstatus counter";
CM_ SG_ 981 ESP_a296_roadWheelAngleHealthDeg "Electronic stability control: a296 road wheel angle health degraded";
CM_ SG_ 981 ESP_a297_roadWheelAngleHealthFau "Electronic stability control: a297 road wheel angle health faulted";
CM_ SG_ 981 ESP_a298_RSArearSteerStatusTimeo "Electronic stability control: a298 RS arear steer status timeout";
CM_ SG_ 981 ESP_a299_RSArearSteerStatusDLC "Electronic stability control: a299 RS arear steer status DLC";
CM_ SG_ 981 ESP_a300_RSArearSteerStatusCheck "Electronic stability control: a300 RS arear steer status checksum";
CM_ SG_ 981 ESP_a301_PEPSstatusCounter "Electronic stability control: a301 PEP sstatus counter";
CM_ SG_ 981 ESP_a302_rearRoadWheelAngleHealt "Electronic stability control: a302 rear road wheel angle health degraded";
CM_ SG_ 981 ESP_a303_rearRoadWheelAngleHealt "Electronic stability control: a303 rear road wheel angle health faulted";
CM_ SG_ 981 ESP_a304_rearVCLVPowerStateTimeo "Electronic stability control: a304 rear VCLV power state timeout";
CM_ SG_ 981 ESP_a305_rearVCLVPowerStateDLC "Electronic stability control: a305 rear VCLV power state DLC";
CM_ SG_ 981 ESP_a306_rearVCLVPowerStateCheck "Electronic stability control: a306 rear VCLV power state checksum";
CM_ SG_ 981 ESP_a307_rearVCLVPowerStateCount "Electronic stability control: a307 rear VCLV power state counter";
CM_ SG_ 981 ESP_a308_evacFillNotComplete "Electronic stability control: a308 evac fill not complete";
CM_ SG_ 981 ESP_a309_factoryModeActive "Electronic stability control: a309 factory mode active";
CM_ SG_ 981 ESP_a310_brakeLatencyReductionAc "Electronic stability control: a310 brake latency reduction active";
CM_ SG_ 981 ESP_a311_aesActive "Electronic stability control: a311 aes active";
CM_ SG_ 981 ESP_a312_undefinedAlertDetected "Electronic stability control: a312 undefined alert detected";
CM_ SG_ 981 ESP_a313_cdpRequestStateInvalid "Electronic stability control: a313 cdp request state invalid";
CM_ SG_ 981 ESP_a314_aesFault "Electronic stability control: a314 aes fault";
CM_ SG_ 981 ESP_a315_EMCBackup11Timeout "Electronic stability control: a315 EMC backup11 timeout";
CM_ SG_ 981 ESP_a316_EMCBackup11DLC "Electronic stability control: a316 EMC backup11 DLC";
CM_ SG_ 981 ESP_a317_EMCBackup11Checksum "Electronic stability control: a317 EMC backup11 checksum";
CM_ SG_ 981 ESP_a318_EMCBackup11Counter "Electronic stability control: a318 EMC backup11 counter";
CM_ SG_ 981 ESP_a319_AES_BackupActuatorActiv "Electronic stability control: a319 AES backup actuator active";
CM_ SG_ 981 ESP_a320_DPB_actuator1Counter "Electronic stability control: a320 DPB actuator1 counter";
CM_ SG_ 981 ESP_a321_DPB_actuator1Checksum "Electronic stability control: a321 DPB actuator1 checksum";
CM_ SG_ 981 ESP_a322_DPB_actuator1DLC "Electronic stability control: a322 DPB actuator1 DLC";
CM_ SG_ 981 ESP_a323_DPB_actuator1Timeout "Electronic stability control: a323 DPB actuator1 timeout";
CM_ SG_ 981 ESP_a324_DPB_actuator2Counter "Electronic stability control: a324 DPB actuator2 counter";
CM_ SG_ 981 ESP_a325_DPB_actuator2Checksum "Electronic stability control: a325 DPB actuator2 checksum";
CM_ SG_ 981 ESP_a326_DPB_actuator2DLC "Electronic stability control: a326 DPB actuator2 DLC";
CM_ SG_ 981 ESP_a327_DPB_actuator2Timeout "Electronic stability control: a327 DPB actuator2 timeout";
CM_ SG_ 981 ESP_a328_DPB_actuator3Counter "Electronic stability control: a328 DPB actuator3 counter";
CM_ SG_ 981 ESP_a329_DPB_actuator3Checksum "Electronic stability control: a329 DPB actuator3 checksum";
CM_ SG_ 981 ESP_a330_DPB_actuator3DLC "Electronic stability control: a330 DPB actuator3 DLC";
CM_ SG_ 981 ESP_a331_DPB_actuator3Timeout "Electronic stability control: a331 DPB actuator3 timeout";
CM_ SG_ 981 ESP_a332_PressureSensorValHigh "Electronic stability control: a332 pressure sensor val high";
CM_ SG_ 981 ESP_a333_ActCircuitNoPressure "Electronic stability control: a333 act circuit no pressure";
CM_ SG_ 981 ESP_a334_BrakePedalAppliedInvali "Electronic stability control: a334 brake pedal applied invalid";
CM_ SG_ 981 ESP_a335_LdmFxTarBrakeActInvalid "Electronic stability control: a335 ldm fx tar brake act invalid";
CM_ SG_ 981 ESP_a336_FxTargetDriverInvalid "Electronic stability control: a336 fx target driver invalid";
CM_ SG_ 981 ESP_a337_pReductionPotentialInva "Electronic stability control: a337 p reduction potential invalid";
CM_ SG_ 981 ESP_a338_pRunoutInvalid "Electronic stability control: a338 p runout invalid";
CM_ SG_ 981 ESP_a339_sInputRodInvalid "Electronic stability control: a339 s input rod invalid";
CM_ SG_ 981 ESP_a340_RollerBenchMisuse "Electronic stability control: a340 roller bench misuse";
CM_ SG_ 981 ESP_a341_EnhancedPressureBuildAc "Electronic stability control: a341 enhanced pressure build active";
CM_ SG_ 981 ESP_a342_EnhancedPressureBuildNo "Electronic stability control: a342 enhanced pressure build not available";
CM_ SG_ 981 ESP_a343_EnhancedPressureBuildLt "Electronic stability control: a343 enhanced pressure build ltm reached";
CM_ SG_ 981 ESP_a344_DIbrakeCommandCounter "Electronic stability control: a344 d ibrake command counter";
CM_ SG_ 981 ESP_a345_DIbrakeCommandChecksum "Electronic stability control: a345 d ibrake command checksum";
CM_ SG_ 981 ESP_a346_DIbrakeCommandDLC "Electronic stability control: a346 d ibrake command DLC";
CM_ SG_ 981 ESP_a347_DIbrakeCommandTimeout "Electronic stability control: a347 d ibrake command timeout";
CM_ SG_ 981 ESP_a348_brakeCmdStateInvalid "Electronic stability control: a348 brake cmd state invalid";
CM_ SG_ 981 ESP_a349_ForceLampToRed "Electronic stability control: a349 force lamp to red";
CM_ SG_ 981 ESP_a350_ActuatorOff "Electronic stability control: a350 actuator off";
CM_ SG_ 981 ESP_a351_ActuatorYellowLampReque "Electronic stability control: a351 actuator yellow lamp requested";
CM_ SG_ 981 ESP_a352_ActuatorLDMFailure "Electronic stability control: a352 actuator LDM failure";
CM_ SG_ 981 ESP_a353_PressureSensorImplausHi "Electronic stability control: a353 pressure sensor implaus high";
CM_ SG_ 981 ESP_a354_HBCRequestInvalid "Electronic stability control: a354 HBC request invalid";
CM_ SG_ 981 ESP_a355_RecuStatusActInvalid "Electronic stability control: a355 recu status act invalid";
CM_ SG_ 981 ESP_a356_DIFAxleTorqueInvalid "Electronic stability control: a356 DIF axle torque invalid";
CM_ SG_ 981 ESP_a357_DIRAxleTorqueInvalid "Electronic stability control: a357 DIR axle torque invalid";
CM_ SG_ 981 ESP_a358_externalActuatorFallbac "Electronic stability control: a358 external actuator fallback";
CM_ SG_ 981 ESP_a359_externalActuatorNoExtRe "Electronic stability control: a359 external actuator no ext req";
CM_ SG_ 981 ESP_a360_BBbrakeActuationTimeout "Electronic stability control: a360 b bbrake actuation timeout";
CM_ SG_ 981 ESP_a361_BBbrakeActuationDLC "Electronic stability control: a361 b bbrake actuation DLC";
CM_ SG_ 981 ESP_a362_BBbrakeActuationChecksu "Electronic stability control: a362 b bbrake actuation checksum";
CM_ SG_ 981 ESP_a363_BBbrakeActuationCounter "Electronic stability control: a363 b bbrake actuation counter";
CM_ SG_ 981 ESP_a364_DIgearInvalid "Electronic stability control: a364 d igear invalid";
CM_ SG_ 981 ESP_a365_TCSInputQualityTooLow "Electronic stability control: a365 TCS input quality too low";
CM_ SG_ 981 ESP_a366_ActuatorBlendingModeReq "Electronic stability control: a366 actuator blending mode req not available";
CM_ SG_ 981 ESP_a367_CBDS_fillBufferThreshol "Electronic stability control: a367 CBDS fill buffer threshold";
CM_ SG_ 981 ESP_a368_CBDS_fmeInternalEvent "Electronic stability control: a368 CBDS fme internal event";
CM_ SG_ 981 ESP_a369_LargeLeakageDetectedByD "Electronic stability control: a369 large leakage detected by DPB";
CM_ SG_ 981 ESP_a370_DPB_actuator4Timeout "Electronic stability control: a370 DPB actuator4 timeout";
CM_ SG_ 981 ESP_a371_DPB_actuator4DLC "Electronic stability control: a371 DPB actuator4 DLC";
CM_ SG_ 981 ESP_a372_DPB_actuator4Checksum "Electronic stability control: a372 DPB actuator4 checksum";
CM_ SG_ 981 ESP_a373_DPB_actuator4Counter "Electronic stability control: a373 DPB actuator4 counter";
CM_ SG_ 981 ESP_a374_StatInvalid_DI_FullSNA "Electronic stability control: a374 stat invalid DI full SNA";
CM_ SG_ 981 ESP_a375_PM_locStateCounter "Electronic stability control: a375 PM loc state counter";
CM_ SG_ 981 ESP_a376_PM_locStateChecksum "Electronic stability control: a376 PM loc state checksum";
CM_ SG_ 981 ESP_a377_PM_locStateDLC "Electronic stability control: a377 PM loc state DLC";
CM_ SG_ 981 ESP_a378_PM_locStateTimeout "Electronic stability control: a378 PM loc state timeout";
CM_ SG_ 981 ESP_a379_DASredundantBrakingCont "Electronic stability control: a379 DA sredundant braking control party checksum";
CM_ SG_ 981 ESP_a380_DASredundantBrakingCont "Electronic stability control: a380 DA sredundant braking control party counter";
CM_ SG_ 981 ESP_a381_DASredundantBrakingCont "Electronic stability control: a381 DA sredundant braking control party DLC";
CM_ SG_ 981 ESP_a382_DASredundantBrakingCont "Electronic stability control: a382 DA sredundant braking control party timeout";
CM_ SG_ 981 ESP_a383_DASredundantBrakingCont "Electronic stability control: a383 DA sredundant braking control chassis checksum";
CM_ SG_ 981 ESP_a384_DASredundantBrakingCont "Electronic stability control: a384 DA sredundant braking control chassis counter";
CM_ SG_ 981 ESP_a385_DASredundantBrakingCont "Electronic stability control: a385 DA sredundant braking control chassis DLC";
CM_ SG_ 981 ESP_a386_DASredundantBrakingCont "Electronic stability control: a386 DA sredundant braking control chassis timeout";
CM_ SG_ 981 ESP_a387_DIlocStatus2Checksum "Electronic stability control: a387 d iloc status2 checksum";
CM_ SG_ 981 ESP_a388_DIlocStatus2Counter "Electronic stability control: a388 d iloc status2 counter";
CM_ SG_ 981 ESP_a389_DIlocStatus2DLC "Electronic stability control: a389 d iloc status2 DLC";
CM_ SG_ 981 ESP_a390_DIlocStatus2Timeout "Electronic stability control: a390 d iloc status2 timeout";
CM_ SG_ 981 ESP_a391_standaloneEBRActive "Electronic stability control: a391 standalone EBR active";
CM_ SG_ 981 ESP_a392_driverlessArmingUnavail "Electronic stability control: a392 driverless arming unavailable";
CM_ SG_ 981 ESP_a393_EMCBackup21Checksum "Electronic stability control: a393 EMC backup21 checksum";
CM_ SG_ 981 ESP_a394_EMCBackup21Counter "Electronic stability control: a394 EMC backup21 counter";
CM_ SG_ 981 ESP_a395_EMCBackup21DLC "Electronic stability control: a395 EMC backup21 DLC";
CM_ SG_ 981 ESP_a396_EMCBackup21Timeout "Electronic stability control: a396 EMC backup21 timeout";
CM_ SG_ 981 ESP_a397_epbrStatusTimeout "Electronic stability control: a397 epbr status timeout";
CM_ SG_ 981 ESP_a398_epbrStatusChecksum "Electronic stability control: a398 epbr status checksum";
CM_ SG_ 981 ESP_a399_epbrStatusDLC "Electronic stability control: a399 epbr status DLC";
CM_ SG_ 981 ESP_a400_epbrStatusCounter "Electronic stability control: a400 epbr status counter";
CM_ SG_ 981 ESP_a401_bsmCircuitFailure "Electronic stability control: a401 bsm circuit failure";
CM_ SG_ 981 ESP_a402_bsmPtsPlausToPsTooHigh "Electronic stability control: a402 bsm pts plaus to ps too high";
CM_ SG_ 981 ESP_a403_batMotorVoltage "Electronic stability control: a403 bat motor voltage";
CM_ SG_ 981 ESP_a404_batPressureCircuit1 "Electronic stability control: a404 bat pressure circuit1";
CM_ SG_ 981 ESP_a405_batPressureCircuit2 "Electronic stability control: a405 bat pressure circuit2";
CM_ SG_ 981 ESP_a406_DIespActuatorTestTimeou "Electronic stability control: a406 d iesp actuator test timeout";
CM_ SG_ 981 ESP_a407_DIespActuatorTestChecks "Electronic stability control: a407 d iesp actuator test checksum";
CM_ SG_ 981 ESP_a408_DIespActuatorTestDLC "Electronic stability control: a408 d iesp actuator test DLC";
CM_ SG_ 981 ESP_a409_DIespActuatorTestCounte "Electronic stability control: a409 d iesp actuator test counter";
CM_ BO_ 808 "Electronic stability control message: info";
CM_ SG_ 808 ESP_infoIndex "Electronic stability control: info index";
CM_ SG_ 808 ESP_infoBuildType "Electronic stability control: info build type";
CM_ SG_ 808 ESP_vehFlashMode "Electronic stability control: veh flash mode";
CM_ SG_ 808 ESP_infoComponentID "Electronic stability control: info component ID";
CM_ SG_ 808 ESP_infoPcbaID "Electronic stability control: info pcba ID";
CM_ SG_ 808 ESP_infoAssemblyID "Electronic stability control: info assembly ID";
CM_ SG_ 808 ESP_infoUsageID "Electronic stability control: info usage ID";
CM_ SG_ 808 ESP_infoSubUsageID "Electronic stability control: info sub usage ID";
CM_ SG_ 808 ESP_infoApplicationCRC "Indicating the Application CRC value of firmware running in system.";
CM_ SG_ 808 ESP_infoVehicleVariant "Electronic stability control: info vehicle variant";
CM_ SG_ 808 ESP_infoSubcomponent1 "Electronic stability control: info subcomponent1";
CM_ SG_ 808 ESP_infoBootUdsProtoVersion "Electronic stability control: info boot uds proto version";
CM_ SG_ 808 ESP_infoBootloaderCRC "Electronic stability control: info bootloader CRC";
CM_ SG_ 808 ESP_infoVariantCRC "Indicating the Calibration CRC value of firmware running in system.";
CM_ BO_ 1236 "Electronic stability control message: party3";
CM_ SG_ 1236 ESP_party3Crc "Electronic stability control: party3 crc";
CM_ SG_ 1236 ESP_party3Counter "Electronic stability control: party3 counter";
CM_ SG_ 1236 ESP_absActive "Electronic stability control: abs active";
CM_ SG_ 1236 ESP_vehicleStandstill "Indicates that the vehicle is completely stationary.";
CM_ SG_ 1236 ESP_vehicleStandstillQF "Qualifier of ESP_vehicleStandstill.";
CM_ SG_ 1236 ESP_pEstMaximum "Maximum of estimated wheel braking pressure.";
CM_ SG_ 1236 ESP_privateVehicleSpd "Vehicle speed as calculated by the ESP from the wheel speed sensors.";
CM_ SG_ 1236 ESP_decoupledBrakePressOffsetCom "Master cylinder pressure sensor offset; raw 127 = signal not available (SNA)";
CM_ SG_ 1236 ESP_privateVehicleSpdQF "ESP private vehicle speed qualifier";
CM_ SG_ 1236 ESP_brakeMasterCylPress "Master cylinder pressure measured in the ESP; raw 1023 = signal not available (SNA)";
CM_ SG_ 1236 ESP_brakeMasterCylPressQF "Reports the brake master cylinder pressure signal (ESP_brakeMasterCylPress) qualification status.";
CM_ BO_ 325 "Electronic stability control message: status";
CM_ SG_ 325 ESP_statusChecksum "Electronic stability control: status checksum";
CM_ SG_ 325 ESP_statusCounter "Electronic stability control: status counter";
CM_ SG_ 325 ESP_espModeActive "Electronic stability control: esp mode active";
CM_ SG_ 325 ESP_stabilityControlSts2 "Electronic stability control: stability control sts2";
CM_ SG_ 325 ESP_ebdFaultLamp "Electronic stability control: ebd fault lamp";
CM_ SG_ 325 ESP_absFaultLamp "ESP request to display ABS Fault Lamp.";
CM_ SG_ 325 ESP_espFaultLamp "ESP request to display ESP Fault lamp in instrument cluster.";
CM_ SG_ 325 ESP_hydraulicBoostEnabled "Electronic stability control: hydraulic boost enabled";
CM_ SG_ 325 ESP_espLampFlash "Electronic stability control: esp lamp flash";
CM_ SG_ 325 ESP_brakeLamp "Electronic stability control: brake lamp";
CM_ SG_ 325 ESP_absBrakeEvent2 "Indicates if ABS is active and on which axle.";
CM_ SG_ 325 ESP_longitudinalAccelQF "Longitudinal accel sensor quialifier from ESP";
CM_ SG_ 325 ESP_lateralAccelQF "Lateral accel sensor quialifier from ESP";
CM_ SG_ 325 ESP_yawRateQF "Electronic stability control: yaw rate QF";
CM_ SG_ 325 ESP_steeringAngleQF "Electronic stability control: steering angle QF";
CM_ SG_ 325 ESP_brakeDiscWipingActive "Indicates when brake disc wiping is active.";
CM_ SG_ 325 ESP_driverBrakeApply "Indicates when the driver applies the brake pedal; raw 3 = signal not available (SNA)";
CM_ SG_ 325 ESP_brakeApply "Electronic stability control: brake apply";
CM_ SG_ 325 ESP_aesPrimaryActuatorStatus "Electronic stability control: aes primary actuator status";
CM_ SG_ 325 ESP_cdpStatus "Indicates the state of the ESP to perform pressure builds through ESP for dynamic apply";
CM_ SG_ 325 ESP_ptcTargetState "Electronic stability control: ptc target state; raw 3 = signal not available (SNA)";
CM_ SG_ 325 ESP_btcTargetState "Electronic stability control: btc target state; raw 3 = signal not available (SNA)";
CM_ SG_ 325 ESP_decoupledBrakePressEst "Reports the master cylinder pressure estimated by the Electronic Stability Program (ESP) which includes four wheel ESP active pressure builds; raw 255 = signal not available (SNA)";
CM_ SG_ 325 ESP_ebrStandstillSkid "Electronic stability control: ebr standstill skid";
CM_ SG_ 325 ESP_ebrStatus "Electronic stability control: ebr status";
CM_ SG_ 325 ESP_brakeTorqueTarget "Electronic stability control: brake torque target";
CM_ BO_ 1621 "Electronic stability control message: uds response";
CM_ SG_ 1621 ESP_udsResponseData "Electronic stability control: uds response data";
CM_ BO_ 373 "Electronic stability control message: wheel speeds";
CM_ SG_ 373 ESP_wheelSpeedFrL "Electronic stability control: wheel speed fr l";
CM_ SG_ 373 ESP_wheelSpeedFrR "Electronic stability control: wheel speed fr r";
CM_ SG_ 373 ESP_wheelSpeedReL "Electronic stability control: wheel speed re l";
CM_ SG_ 373 ESP_wheelSpeedReR "Electronic stability control: wheel speed re r";
CM_ BO_ 1662 "EVSE ECU message: iso tp to veh";
CM_ SG_ 1662 EVSE_isoTpToVehData "EVSE ECU: iso tp to veh data";
CM_ BO_ 1322 "FC ECU message: alert log";
CM_ SG_ 1322 FC_alertID "FC ECU: alert ID";
CM_ SG_ 1322 FC_alertType "FC ECU: alert type";
CM_ SG_ 1322 FC_a130_CA_flybackSwOvType "FC ECU: a130 CA flyback sw ov type";
CM_ SG_ 1322 FC_a146_CA_flybackOnTime "FC ECU: a146 CA flyback on time";
CM_ SG_ 1322 FC_a146_CA_flybackV "FC ECU: a146 CA flyback v";
CM_ SG_ 1322 FC_a146_CA_flybackTargetV "FC ECU: a146 CA flyback target v";
CM_ SG_ 1322 FC_a159_CA_wdtTaskList1 "FC ECU: a159 CA wdt task list1";
CM_ SG_ 1322 FC_a159_CA_wdtTaskList2 "FC ECU: a159 CA wdt task list2";
CM_ BO_ 895 "FC ECU message: alert matrix3";
CM_ SG_ 895 FC_a129_CA_flyback_HW_OC "FC ECU: a129 CA flyback HW OC";
CM_ SG_ 895 FC_a130_CA_flyback_SW_OV "FC ECU: a130 CA flyback SW OV";
CM_ SG_ 895 FC_a131_CA_flyback_HW_OV "FC ECU: a131 CA flyback HW OV";
CM_ SG_ 895 FC_a132_CA_bmsMia "FC ECU: a132 CA bms mia";
CM_ SG_ 895 FC_a133_CA_evseMia "FC ECU: a133 CA evse mia";
CM_ SG_ 895 FC_a134_CA_vehTxBufOvf "FC ECU: a134 CA veh tx buf ovf";
CM_ SG_ 895 FC_a135_CA_vehRxBufOvf "FC ECU: a135 CA veh rx buf ovf";
CM_ SG_ 895 FC_a136_CA_evseTxBufOvf "FC ECU: a136 CA evse tx buf ovf";
CM_ SG_ 895 FC_a137_CA_evseRxBufOvf "FC ECU: a137 CA evse rx buf ovf";
CM_ SG_ 895 FC_a138_CA_hwProxTrip "FC ECU: a138 CA hw prox trip";
CM_ SG_ 895 FC_a139_CA_ss2NotLow "FC ECU: a139 CA ss2 not low";
CM_ SG_ 895 FC_a140_CA_bmsIncompatible "FC ECU: a140 CA bms incompatible";
CM_ SG_ 895 FC_a141_CA_vehConn_OT "FC ECU: a141 CA veh conn OT";
CM_ SG_ 895 FC_a142_CA_evseConn_OT "FC ECU: a142 CA evse conn OT";
CM_ SG_ 895 FC_a143_CA_pcb_OT "FC ECU: a143 CA pcb OT";
CM_ SG_ 895 FC_a144_CA_flybackUnstable "FC ECU: a144 CA flyback unstable";
CM_ SG_ 895 FC_a145_CA_flybackDataStale "FC ECU: a145 CA flyback data stale";
CM_ SG_ 895 FC_a146_CA_flybackBusLoadHi "FC ECU: a146 CA flyback bus load hi";
CM_ SG_ 895 FC_a147_CA_vehConn_UT "FC ECU: a147 CA veh conn UT";
CM_ SG_ 895 FC_a148_CA_evseConn_UT "FC ECU: a148 CA evse conn UT";
CM_ SG_ 895 FC_a149_CA_pcb_UT "FC ECU: a149 CA pcb UT";
CM_ SG_ 895 FC_a150_CA_vehToEvseDeltaHi "FC ECU: a150 CA veh to evse delta hi";
CM_ SG_ 895 FC_a151_CA_vehToEvseDeltaLo "FC ECU: a151 CA veh to evse delta lo";
CM_ SG_ 895 FC_a152_CA_vehToPcbDeltaHi "FC ECU: a152 CA veh to pcb delta hi";
CM_ SG_ 895 FC_a153_CA_evseToPcbDeltaHi "FC ECU: a153 CA evse to pcb delta hi";
CM_ SG_ 895 FC_a154_CA_vehToPcbDeltaLo "FC ECU: a154 CA veh to pcb delta lo";
CM_ SG_ 895 FC_a155_CA_evseToPcbDeltaLo "FC ECU: a155 CA evse to pcb delta lo";
CM_ SG_ 895 FC_a156_CA_flybackRunTimeout "FC ECU: a156 CA flyback run timeout";
CM_ SG_ 895 FC_a157_CA_unused "FC ECU: a157 CA unused";
CM_ SG_ 895 FC_a158_CA_evseOverCurrent "FC ECU: a158 CA evse over current";
CM_ SG_ 895 FC_a159_CA_wdtExpired "FC ECU: a159 CA wdt expired";
CM_ SG_ 895 FC_a160_CA_ss2Deasserted "FC ECU: a160 CA ss2 deasserted";
CM_ SG_ 895 FC_a161_CA_vehTempHiFoldBk "FC ECU: a161 CA veh temp hi fold bk";
CM_ SG_ 895 FC_a162_CA_evseTempHiFoldBk "FC ECU: a162 CA evse temp hi fold bk";
CM_ SG_ 895 FC_a163_CA_pcbTempHiFoldBk "FC ECU: a163 CA pcb temp hi fold bk";
CM_ SG_ 895 FC_a164_CA_proxDisconnected "FC ECU: a164 CA prox disconnected";
CM_ SG_ 895 FC_a165_CA_evseConnUnlocked "FC ECU: a165 CA evse conn unlocked";
CM_ SG_ 895 FC_a166_CA_vehConnUnlocked "FC ECU: a166 CA veh conn unlocked";
CM_ SG_ 895 FC_a167_CA_isoVoltageLow "FC ECU: a167 CA iso voltage low";
CM_ SG_ 895 FC_a168_CA_proxTimeout "FC ECU: a168 CA prox timeout";
CM_ SG_ 895 FC_a169_CA_pilotAcceptTimeout "FC ECU: a169 CA pilot accept timeout";
CM_ SG_ 895 FC_a170_CA_vehDataTimeout "FC ECU: a170 CA veh data timeout";
CM_ SG_ 895 FC_a171_CA_vehConLockTimeout "FC ECU: a171 CA veh con lock timeout";
CM_ SG_ 895 FC_a172_CA_ss2LowTimeout "FC ECU: a172 CA ss2 low timeout";
CM_ SG_ 895 FC_a173_CA_evseDataTimeout "FC ECU: a173 CA evse data timeout";
CM_ SG_ 895 FC_a174_CA_vehReadyTimeout "FC ECU: a174 CA veh ready timeout";
CM_ SG_ 895 FC_a175_CA_evseIsoTestTimeout "FC ECU: a175 CA evse iso test timeout";
CM_ SG_ 895 FC_a176_CA_chargingBusTimeout "FC ECU: a176 CA charging bus timeout";
CM_ SG_ 895 FC_a177_CA_bmsCtrCloseTimeout "FC ECU: a177 CA bms ctr close timeout";
CM_ SG_ 895 FC_a178_CA_evseStartTimeout "FC ECU: a178 CA evse start timeout";
CM_ SG_ 895 FC_a179_CA_startupProblem "FC ECU: a179 CA startup problem";
CM_ SG_ 895 FC_a180_CA_chargingProblem "FC ECU: a180 CA charging problem";
CM_ SG_ 895 FC_a181_CA_vRegBrownout "FC ECU: a181 CA v reg brownout";
CM_ SG_ 895 FC_a182_CA_evseChrMalfunc "FC ECU: a182 CA evse chr malfunc";
CM_ SG_ 895 FC_a183_CA_evseBatIncompat "FC ECU: a183 CA evse bat incompat";
CM_ SG_ 895 FC_a184_CA_evseBatMalfunc "FC ECU: a184 CA evse bat malfunc";
CM_ SG_ 895 FC_a185_CA_vehReadyDeasserted "FC ECU: a185 CA veh ready deasserted";
CM_ SG_ 895 FC_a186_CA_fcContOpenTimeout "FC ECU: a186 CA fc cont open timeout";
CM_ SG_ 895 FC_a187_CA_evseConLockTimeout "FC ECU: a187 CA evse con lock timeout";
CM_ BO_ 927 "FC ECU message: alert matrix4";
CM_ SG_ 927 FC_a193_FCAlertPlaceholder "FC ECU: a193 FC alert placeholder";
CM_ BO_ 958 "FC ECU message: alert matrix5";
CM_ SG_ 958 FC_a257_GB_bmsMia "FC ECU: a257 GB bms mia";
CM_ SG_ 958 FC_a258_GB_evseMia "FC ECU: a258 GB evse mia";
CM_ SG_ 958 FC_a259_GB_vehTxBufOvf "FC ECU: a259 GB veh tx buf ovf";
CM_ SG_ 958 FC_a260_GB_vehRxBufOvf "FC ECU: a260 GB veh rx buf ovf";
CM_ SG_ 958 FC_a261_GB_evseTxBufOvf "FC ECU: a261 GB evse tx buf ovf";
CM_ SG_ 958 FC_a262_GB_evseRxBufOvf "FC ECU: a262 GB evse rx buf ovf";
CM_ SG_ 958 FC_a263_GB_hwProxTrip "FC ECU: a263 GB hw prox trip";
CM_ SG_ 958 FC_a264_GB_timeoutCHM "FC ECU: a264 GB timeout CHM";
CM_ SG_ 958 FC_a265_GB_bmsIncompatible "FC ECU: a265 GB bms incompatible";
CM_ SG_ 958 FC_a266_GB_negPin_OT "FC ECU: a266 GB neg pin OT";
CM_ SG_ 958 FC_a267_GB_posPin_OT "FC ECU: a267 GB pos pin OT";
CM_ SG_ 958 FC_a268_GB_pcb_OT "FC ECU: a268 GB pcb OT";
CM_ SG_ 958 FC_a269_GB_timeoutCRM "FC ECU: a269 GB timeout CRM";
CM_ SG_ 958 FC_a270_GB_timeoutCML "FC ECU: a270 GB timeout CML";
CM_ SG_ 958 FC_a271_GB_timeoutCRO "FC ECU: a271 GB timeout CRO";
CM_ SG_ 958 FC_a272_GB_negToPosDeltaHi "FC ECU: a272 GB neg to pos delta hi";
CM_ SG_ 958 FC_a273_GB_negToPosDeltaLo "FC ECU: a273 GB neg to pos delta lo";
CM_ SG_ 958 FC_a274_GB_negToPcbDeltaHi "FC ECU: a274 GB neg to pcb delta hi";
CM_ SG_ 958 FC_a275_GB_posToPcbDeltaHi "FC ECU: a275 GB pos to pcb delta hi";
CM_ SG_ 958 FC_a276_GB_negToPcbDeltaLo "FC ECU: a276 GB neg to pcb delta lo";
CM_ SG_ 958 FC_a277_GB_posToPcbDeltaLo "FC ECU: a277 GB pos to pcb delta lo";
CM_ SG_ 958 FC_a278_GB_timeoutCCS "FC ECU: a278 GB timeout CCS";
CM_ SG_ 958 FC_a279_GB_evseOverCurrent "FC ECU: a279 GB evse over current";
CM_ SG_ 958 FC_a280_GB_retryLimitExceeded "FC ECU: a280 GB retry limit exceeded";
CM_ SG_ 958 FC_a281_GB_evseOutOfService "FC ECU: a281 GB evse out of service";
CM_ SG_ 958 FC_a282_GB_negTempHiFoldBk "FC ECU: a282 GB neg temp hi fold bk";
CM_ SG_ 958 FC_a283_GB_posTempHiFoldBk "FC ECU: a283 GB pos temp hi fold bk";
CM_ SG_ 958 FC_a284_GB_pcbTempHiFoldBk "FC ECU: a284 GB pcb temp hi fold bk";
CM_ SG_ 958 FC_a285_GB_proxDisconnected "FC ECU: a285 GB prox disconnected";
CM_ SG_ 958 FC_a286_GB_evseConnUnlocked "FC ECU: a286 GB evse conn unlocked";
CM_ SG_ 958 FC_a287_GB_vehConnUnlocked "FC ECU: a287 GB veh conn unlocked";
CM_ SG_ 958 FC_a288_GB_evseAbnormalStopReq "FC ECU: a288 GB evse abnormal stop req";
CM_ SG_ 958 FC_a289_GB_proxTimeout "FC ECU: a289 GB prox timeout";
CM_ SG_ 958 FC_a290_GB_pilotAcceptTimeout "FC ECU: a290 GB pilot accept timeout";
CM_ SG_ 958 FC_a291_GB_vehDataTimeout "FC ECU: a291 GB veh data timeout";
CM_ SG_ 958 FC_a292_GB_vehConLockTimeout "FC ECU: a292 GB veh con lock timeout";
CM_ SG_ 958 FC_a293_GB_proxRationality "FC ECU: a293 GB prox rationality";
CM_ SG_ 958 FC_a294_GB_unused "FC ECU: a294 GB unused";
CM_ SG_ 958 FC_a295_GB_pilotRationality "FC ECU: a295 GB pilot rationality";
CM_ SG_ 958 FC_a296_GB_invalidPilotTransitio "FC ECU: a296 GB invalid pilot transitio";
CM_ SG_ 958 FC_a297_GB_unused "FC ECU: a297 GB unused";
CM_ SG_ 958 FC_a298_GB_bmsCtrCloseTimeout "FC ECU: a298 GB bms ctr close timeout";
CM_ SG_ 958 FC_a299_GB_evseReadyTimeout "FC ECU: a299 GB evse ready timeout";
CM_ SG_ 958 FC_a300_GB_unused "FC ECU: a300 GB unused";
CM_ SG_ 958 FC_a301_GB_unused "FC ECU: a301 GB unused";
CM_ SG_ 958 FC_a302_GB_unused "FC ECU: a302 GB unused";
CM_ SG_ 958 FC_a303_GB_negRecogTimeout "FC ECU: a303 GB neg recog timeout";
CM_ SG_ 958 FC_a304_GB_unused "FC ECU: a304 GB unused";
CM_ SG_ 958 FC_a305_GB_posRecogTimeout "FC ECU: a305 GB pos recog timeout";
CM_ SG_ 958 FC_a306_GB_vehReadyDeasserted "FC ECU: a306 GB veh ready deasserted";
CM_ SG_ 958 FC_a307_GB_fcContOpenTimeout "FC ECU: a307 GB fc cont open timeout";
CM_ SG_ 958 FC_a308_GB_evseConLockTimeout "FC ECU: a308 GB evse con lock timeout";
CM_ SG_ 958 FC_a309_GB_unused "FC ECU: a309 GB unused";
CM_ SG_ 958 FC_a310_GB_unused "FC ECU: a310 GB unused";
CM_ SG_ 958 FC_a311_GB_battParamsTimeout "FC ECU: a311 GB batt params timeout";
CM_ SG_ 958 FC_a312_GB_evseLimitsTimeout "FC ECU: a312 GB evse limits timeout";
CM_ SG_ 958 FC_a313_GB_inputVoltageRailOv "FC ECU: a313 GB input voltage rail ov";
CM_ BO_ 990 "FC ECU message: alert matrix6";
CM_ SG_ 990 FC_a321_FCAlertPlaceholder "FC ECU: a321 FC alert placeholder";
CM_ BO_ 1117 "FC ECU message: evse billing";
CM_ SG_ 1117 FC_evseBillingDataSelect "FC ECU: evse billing data select";
CM_ SG_ 1117 FC_evseBillingEnergy "FC ECU: evse billing energy";
CM_ SG_ 1117 FC_evseMeterPower "FC ECU: evse meter power";
CM_ SG_ 1117 FC_evseMeterCurrent "FC ECU: evse meter current";
CM_ SG_ 1117 FC_evseMeterVoltage "FC ECU: evse meter voltage";
CM_ SG_ 1117 FC_evseMeterFwGitHash "FC ECU: evse meter fw git hash";
CM_ BO_ 1334 "FC ECU message: evse billing2";
CM_ SG_ 1334 FC_evseBilling2DataSelect "FC ECU: evse billing2 data select";
CM_ SG_ 1334 FC_evsePpuEnabled "FC ECU: evse ppu enabled";
CM_ SG_ 1334 FC_evseBillingEnergyHighRes "FC ECU: evse billing energy high res; raw 16777215 = signal not available (SNA)";
CM_ BO_ 1303 "FC ECU message: identifier";
CM_ SG_ 1303 FC_id "Fast charger identifying number";
CM_ SG_ 1303 FC_sessionId "Fast charge session ID";
CM_ BO_ 1310 "FC ECU message: info";
CM_ SG_ 1310 FC_infoIndex "FC ECU: info index";
CM_ SG_ 1310 FC_infoBuildType "FC ECU: info build type";
CM_ SG_ 1310 FC_infoBuildConfigID "FC ECU: info build config ID";
CM_ SG_ 1310 FC_infoHardwareID "FC ECU: info hardware ID";
CM_ SG_ 1310 FC_infoComponentID "FC ECU: info component ID";
CM_ SG_ 1310 FC_infoPcbaID "FC ECU: info pcba ID";
CM_ SG_ 1310 FC_infoAssemblyID "FC ECU: info assembly ID";
CM_ SG_ 1310 FC_infoUsageID "FC ECU: info usage ID";
CM_ SG_ 1310 FC_infoSubUsageID "FC ECU: info sub usage ID";
CM_ SG_ 1310 FC_infoApplicationCRC "FC ECU: info application CRC";
CM_ SG_ 1310 FC_infoBootSvnRev "Position from firmware; message assignment inferred.";
CM_ SG_ 1310 FC_infoCPLDVersionMajor "Position from firmware; message assignment inferred.";
CM_ SG_ 1310 FC_infoCPLDVersionMinor "Position from firmware; message assignment inferred.";
CM_ SG_ 1310 FC_infoAppGitHashBytes "FC ECU: info app git hash bytes";
CM_ SG_ 1310 FC_infoBootGitHashBytes "FC ECU: info boot git hash bytes";
CM_ SG_ 1310 FC_infoPlatformType "FC ECU: info platform type";
CM_ SG_ 1310 FC_infoMajorVersion "Fast charger firmware major version number";
CM_ SG_ 1310 FC_infoBranchOrigin "Fast charger branch origin";
CM_ SG_ 1310 FC_infoMaturity "Fast charger firmware info";
CM_ SG_ 1310 FC_infoHardwareRevision "FC ECU: info hardware revision";
CM_ SG_ 1310 FC_infoBootUdsProtoVersion "Position from firmware; message assignment inferred.";
CM_ SG_ 1310 FC_partNumChar01 "FC ECU: part num char01";
CM_ SG_ 1310 FC_partNumChar02 "FC ECU: part num char02";
CM_ SG_ 1310 FC_partNumChar03 "FC ECU: part num char03";
CM_ SG_ 1310 FC_partNumChar04 "FC ECU: part num char04";
CM_ SG_ 1310 FC_partNumChar05 "FC ECU: part num char05";
CM_ SG_ 1310 FC_partNumChar06 "FC ECU: part num char06";
CM_ SG_ 1310 FC_partNumChar07 "FC ECU: part num char07";
CM_ SG_ 1310 FC_partNumChar08 "FC ECU: part num char08";
CM_ SG_ 1310 FC_partNumChar09 "FC ECU: part num char09";
CM_ SG_ 1310 FC_partNumChar10 "FC ECU: part num char10";
CM_ SG_ 1310 FC_partNumChar11 "FC ECU: part num char11";
CM_ SG_ 1310 FC_partNumChar12 "FC ECU: part num char12";
CM_ SG_ 1310 FC_partNumChar13 "FC ECU: part num char13";
CM_ SG_ 1310 FC_partNumChar14 "FC ECU: part num char14";
CM_ SG_ 1310 FC_partNumChar15 "FC ECU: part num char15";
CM_ SG_ 1310 FC_partNumChar16 "FC ECU: part num char16";
CM_ SG_ 1310 FC_partNumChar17 "FC ECU: part num char17";
CM_ SG_ 1310 FC_partNumChar18 "FC ECU: part num char18";
CM_ SG_ 1310 FC_partNumChar19 "FC ECU: part num char19";
CM_ SG_ 1310 FC_partNumChar20 "FC ECU: part num char20";
CM_ BO_ 580 "FC ECU message: limits";
CM_ SG_ 580 FC_powerLimit "Instantaneous power charger can deliver; raw 8191 = signal not available (SNA)";
CM_ SG_ 580 FC_currentLimit "Instantaneous current charger can deliver; raw 8191 = signal not available (SNA)";
CM_ SG_ 580 FC_maxVoltageLimit "Max voltage charger can deliver. 600/65536; raw 8191 = signal not available (SNA)";
CM_ SG_ 580 FC_minVoltageLimit "Measures Electric Vehicle Supply Equipment (EVSE) minimum current limit; raw 8191 = signal not available (SNA)";
CM_ BO_ 702 "FC ECU message: limits high power";
CM_ SG_ 702 FC_powerLimit_value "Instantaneous power charger can deliver. Mantissa portion of extended range version of legacy signal, used with protocol versions 9+. FC_powerLimit = value * 10^exp; raw 32768 = signal not available (SNA)";
CM_ SG_ 702 FC_currentLimit_value "FC ECU: current limit value; raw 32768 = signal not available (SNA)";
CM_ SG_ 702 FC_minVoltageLimit_value "FC ECU: min voltage limit value; raw 32768 = signal not available (SNA)";
CM_ SG_ 702 FC_powerLimit_exp "Instantaneous power charger can deliver. Exponent portion of extended ragne version of legacy signal, used with protocol versions 9+. FC_powerLimit = value * 10^exp.";
CM_ SG_ 702 FC_currentLimit_exp "FC ECU: current limit exp";
CM_ SG_ 702 FC_minVoltageLimit_exp "FC ECU: min voltage limit exp";
CM_ BO_ 1345 "FC ECU message: max limits";
CM_ SG_ 1345 FC_maxPowerLimit "Max power charger can deliver; raw 8191 = signal not available (SNA)";
CM_ SG_ 1345 FC_maxCurrentLimit "Max current charger can deliver; raw 8191 = signal not available (SNA)";
CM_ BO_ 1300 "FC ECU message: serial";
CM_ SG_ 1300 FC_serialDataSelect "FC ECU: serial data select";
CM_ SG_ 1300 FC_serialChar01 "FC ECU: serial char01";
CM_ SG_ 1300 FC_serialChar02 "FC ECU: serial char02";
CM_ SG_ 1300 FC_serialChar03 "FC ECU: serial char03";
CM_ SG_ 1300 FC_serialChar04 "FC ECU: serial char04";
CM_ SG_ 1300 FC_serialChar05 "FC ECU: serial char05";
CM_ SG_ 1300 FC_serialChar06 "FC ECU: serial char06";
CM_ SG_ 1300 FC_serialChar07 "FC ECU: serial char07";
CM_ SG_ 1300 FC_serialChar08 "FC ECU: serial char08";
CM_ SG_ 1300 FC_serialChar09 "FC ECU: serial char09";
CM_ SG_ 1300 FC_serialChar10 "FC ECU: serial char10";
CM_ SG_ 1300 FC_serialChar11 "FC ECU: serial char11";
CM_ SG_ 1300 FC_serialChar12 "FC ECU: serial char12";
CM_ SG_ 1300 FC_serialChar13 "FC ECU: serial char13";
CM_ SG_ 1300 FC_serialChar14 "FC ECU: serial char14";
CM_ SG_ 1300 FC_serialChar15 "FC ECU: serial char15";
CM_ SG_ 1300 FC_serialChar16 "FC ECU: serial char16";
CM_ SG_ 1300 FC_serialChar17 "FC ECU: serial char17";
CM_ BO_ 532 "FC ECU message: status";
CM_ SG_ 532 FC_protocolVersion "FC ECU: protocol version";
CM_ SG_ 532 FC_statusCode "Fast charger status code; raw 0 = signal not available (SNA)";
CM_ SG_ 532 FC_deprecated1 "FC ECU: deprecated1";
CM_ SG_ 532 FC_deprecated2 "FC ECU: deprecated2";
CM_ SG_ 532 FC_deprecated3 "FC ECU: deprecated3";
CM_ SG_ 532 FC_adapterLocked "Indicates if the DC adapter is secure or not";
CM_ SG_ 532 FC_minCurrentLimit "Fast charger min current limit";
CM_ SG_ 532 FC_type "Type of EVSE connected that supports digital communication; raw 7 = signal not available (SNA)";
CM_ SG_ 532 FC_dcCurrent "Fast charger DC output current";
CM_ SG_ 532 FC_postID "Fast charger charging post ID; raw 3 = signal not available (SNA)";
CM_ SG_ 532 FC_dcVoltage "Fast charger DC voltage";
CM_ SG_ 532 FC_leakageTestNotSupported "Indicates if the S/X leakage test can be run on this supercharger";
CM_ SG_ 532 FC_dischargeSupported "FC ECU: discharge supported";
CM_ BO_ 533 "FC ECU message: status2";
CM_ SG_ 533 FC_externalIsolationResistance "Fast charger external isolation resistance; raw 255 = signal not available (SNA)";
CM_ BO_ 535 "FC ECU message: status3";
CM_ SG_ 535 FC_status3DataSelect "FC ECU: status3 data select";
CM_ SG_ 535 FC_status3DummySig "FC ECU: status3 dummy sig";
CM_ SG_ 535 FC_class "FC ECU: class; raw 0 = signal not available (SNA)";
CM_ SG_ 535 FC_brand "Fast charger brand; raw 0 = signal not available (SNA)";
CM_ SG_ 535 FC_coolingType "Type of cooling used for the supercharger; raw 0 = signal not available (SNA)";
CM_ SG_ 535 FC_uiStopType "Type of stop type supported from the UI; raw 0 = signal not available (SNA)";
CM_ SG_ 535 FC_emergencyShutdownSupported "Indicates if the supercharger supports fast emergency shutdown requests from vehicle";
CM_ SG_ 535 FC_generation "Hardware generation of the Tesla EVSE; raw 0 = signal not available (SNA)";
CM_ SG_ 535 FC_billingEnergy "Total billable charge energy (integrated by EVSE). Position from firmware; message assignment inferred.";
CM_ BO_ 888 "Gateway message: e call";
CM_ SG_ 888 GTW_GTW_SOS_ECALL_RQST "State of the GTW-SOS-ECALL-RQST pin";
CM_ SG_ 888 GTW_LTE_ECALL_LOCK "State of the LTE-ECALL-LOCK pin";
BA_DEF_ BO_ "GenMsgCycleTime" INT 0 3600000;
BA_DEF_ BO_ "GenMsgSendType" ENUM "Cyclic","NotUsed","NotUsed","NotUsed","NotUsed","NotUsed","NotUsed","IfActive","NoMsgSendType","NotUsed";
BA_DEF_ BO_ "VFrameFormat" ENUM "StandardCAN","ExtendedCAN","reserved","J1939PG","reserved","reserved","reserved","reserved","reserved","reserved","reserved","reserved","reserved","reserved","StandardCAN_FD","ExtendedCAN_FD";
BA_DEF_ BO_ "CANFD_BRS" ENUM "0","1";
BA_DEF_ SG_ "GenSigSNA" STRING;
BA_DEF_ SG_ "SystemSignalLongSymbol" STRING;
BA_DEF_ SG_ "Confidence" ENUM "validated","plausible","layout-only","contradicted";
BA_DEF_DEF_ "GenMsgCycleTime" 0;
BA_DEF_DEF_ "GenMsgSendType" "NoMsgSendType";
BA_DEF_DEF_ "VFrameFormat" "StandardCAN";
BA_DEF_DEF_ "CANFD_BRS" "1";
BA_DEF_DEF_ "GenSigSNA" "";
BA_DEF_DEF_ "SystemSignalLongSymbol" "";
BA_DEF_DEF_ "Confidence" "layout-only";
BA_ "GenMsgCycleTime" BO_ 1000 100;
BA_ "GenMsgSendType" BO_ 1000 0;
BA_ "GenMsgCycleTime" BO_ 2024 1000;
BA_ "GenMsgSendType" BO_ 2024 0;
BA_ "GenMsgCycleTime" BO_ 552 100;
BA_ "GenMsgSendType" BO_ 552 0;
BA_ "GenMsgCycleTime" BO_ 742 1000;
BA_ "GenMsgSendType" BO_ 742 0;
BA_ "GenMsgCycleTime" BO_ 744 100;
BA_ "GenMsgSendType" BO_ 744 0;
BA_ "GenMsgCycleTime" BO_ 981 1000;
BA_ "GenMsgSendType" BO_ 981 0;
BA_ "GenMsgCycleTime" BO_ 808 10000;
BA_ "GenMsgSendType" BO_ 808 0;
BA_ "GenMsgCycleTime" BO_ 1236 10;
BA_ "GenMsgSendType" BO_ 1236 0;
BA_ "GenMsgCycleTime" BO_ 325 20;
BA_ "GenMsgSendType" BO_ 325 0;
BA_ "GenMsgCycleTime" BO_ 1621 100;
BA_ "GenMsgSendType" BO_ 1621 0;
BA_ "GenMsgCycleTime" BO_ 373 20;
BA_ "GenMsgSendType" BO_ 373 0;
BA_ "GenMsgCycleTime" BO_ 895 1000;
BA_ "GenMsgSendType" BO_ 895 0;
BA_ "GenMsgCycleTime" BO_ 927 1000;
BA_ "GenMsgSendType" BO_ 927 0;
BA_ "GenMsgCycleTime" BO_ 958 1000;
BA_ "GenMsgSendType" BO_ 958 0;
BA_ "GenMsgCycleTime" BO_ 990 1000;
BA_ "GenMsgSendType" BO_ 990 0;
BA_ "GenMsgCycleTime" BO_ 1117 1000;
BA_ "GenMsgSendType" BO_ 1117 0;
BA_ "GenMsgCycleTime" BO_ 1334 1000;
BA_ "GenMsgSendType" BO_ 1334 0;
BA_ "GenMsgCycleTime" BO_ 1303 1000;
BA_ "GenMsgSendType" BO_ 1303 0;
BA_ "GenMsgCycleTime" BO_ 1310 1000;
BA_ "GenMsgSendType" BO_ 1310 0;
BA_ "GenMsgCycleTime" BO_ 580 100;
BA_ "GenMsgSendType" BO_ 580 0;
BA_ "GenMsgCycleTime" BO_ 702 100;
BA_ "GenMsgSendType" BO_ 702 0;
BA_ "GenMsgCycleTime" BO_ 1345 100;
BA_ "GenMsgSendType" BO_ 1345 0;
BA_ "GenMsgCycleTime" BO_ 1300 1000;
BA_ "GenMsgSendType" BO_ 1300 0;
BA_ "GenMsgCycleTime" BO_ 532 100;
BA_ "GenMsgSendType" BO_ 532 0;
BA_ "GenMsgCycleTime" BO_ 533 1000;
BA_ "GenMsgSendType" BO_ 533 0;
BA_ "GenMsgCycleTime" BO_ 535 1000;
BA_ "GenMsgSendType" BO_ 535 0;
BA_ "GenMsgCycleTime" BO_ 888 1000;
BA_ "GenMsgSendType" BO_ 888 0;
BA_ "Confidence" SG_ 1000 EPBR_matrixIndex 1;
BA_ "SystemSignalLongSymbol" SG_ 1000 EPBR_a202_remoteEpbConfigIncompa "EPBR_a202_remoteEpbConfigIncompatible";
BA_ "SystemSignalLongSymbol" SG_ 1000 EPBR_a210_parkForDriverIsLeaving "EPBR_a210_parkForDriverIsLeavingDebug";
BA_ "SystemSignalLongSymbol" SG_ 1000 EPBR_a254_showStalkParkButtonFau "EPBR_a254_showStalkParkButtonFaultOnUi";
BA_ "SystemSignalLongSymbol" SG_ 1000 EPBR_a261_winchModeWithoutSteeri "EPBR_a261_winchModeWithoutSteering";
BA_ "SystemSignalLongSymbol" SG_ 1000 EPBR_a304_rearSeatControllerEFus "EPBR_a304_rearSeatControllerEFuseTrip";
BA_ "SystemSignalLongSymbol" SG_ 1000 EPBR_a353_missingSpeedUnableToPa "EPBR_a353_missingSpeedUnableToPark";
BA_ "SystemSignalLongSymbol" SG_ 1000 EPBR_a354_parkedForLowBrakeFluid "EPBR_a354_parkedForLowBrakeFluidMode";
BA_ "SystemSignalLongSymbol" SG_ 1000 EPBR_a355_brakeHwAndEpbHwMismatc "EPBR_a355_brakeHwAndEpbHwMismatch";
BA_ "SystemSignalLongSymbol" SG_ 1000 EPBR_a356_parkingForStationaryDe "EPBR_a356_parkingForStationaryDetect";
BA_ "SystemSignalLongSymbol" SG_ 1000 EPBR_a358_brakesTooHotForSlopeWi "EPBR_a358_brakesTooHotForSlopeWithOnlyOneEpb";
BA_ "SystemSignalLongSymbol" SG_ 1000 EPBR_a362_ibstPressedEspNotPress "EPBR_a362_ibstPressedEspNotPressedMismatch";
BA_ "SystemSignalLongSymbol" SG_ 1000 EPBR_a363_ibstNotPressedEspPress "EPBR_a363_ibstNotPressedEspPressedMismatch";
BA_ "SystemSignalLongSymbol" SG_ 1000 EPBR_a364_espMasterCylCompOverTh "EPBR_a364_espMasterCylCompOverThreshold";
BA_ "SystemSignalLongSymbol" SG_ 1000 EPBR_a365_TooSteepToParkWithTrai "EPBR_a365_TooSteepToParkWithTrailerWarning";
BA_ "SystemSignalLongSymbol" SG_ 1000 EPBR_a366_TooSteepToParkWithTrai "EPBR_a366_TooSteepToParkWithTrailerUnSecEnv";
BA_ "Confidence" SG_ 2024 EPBR_infoIndex 1;
BA_ "Confidence" SG_ 2024 EPBR_infoBuildType 0;
BA_ "Confidence" SG_ 2024 EPBR_infoBuildConfigId 0;
BA_ "Confidence" SG_ 2024 EPBR_infoHardwareId 0;
BA_ "Confidence" SG_ 2024 EPBR_infoComponentId 0;
BA_ "Confidence" SG_ 2024 EPBR_infoPcbaId 0;
BA_ "Confidence" SG_ 2024 EPBR_infoAssemblyId 0;
BA_ "GenSigSNA" SG_ 2024 EPBR_infoAssemblyId "255";
BA_ "Confidence" SG_ 2024 EPBR_infoUsageId 0;
BA_ "Confidence" SG_ 2024 EPBR_infoSubUsageId 0;
BA_ "Confidence" SG_ 2024 EPBR_infoAppCrc 0;
BA_ "Confidence" SG_ 2024 EPBR_infoAppGitHash 0;
BA_ "Confidence" SG_ 2024 EPBR_infoBootGitHash 0;
BA_ "Confidence" SG_ 2024 EPBR_infoPlatformType 0;
BA_ "Confidence" SG_ 2024 EPBR_infoBootUdsProtoVersion 0;
BA_ "Confidence" SG_ 2024 EPBR_infoBootCrc 0;
BA_ "Confidence" SG_ 552 EPBR_unitStatus 0;
BA_ "Confidence" SG_ 552 EPBR_unitFaultStatus 0;
BA_ "Confidence" SG_ 552 EPBR_summonState 0;
BA_ "Confidence" SG_ 552 EPBR_disconnected 0;
BA_ "Confidence" SG_ 552 EPBR_pistonTouchingRotor 0;
BA_ "Confidence" SG_ 552 EPBR_csmFaultReason 0;
BA_ "Confidence" SG_ 552 EPBR_esmOperationTrigger 0;
BA_ "Confidence" SG_ 552 EPBR_summonFaultReason 0;
BA_ "Confidence" SG_ 552 EPBR_localServiceModeActive 0;
BA_ "Confidence" SG_ 552 EPBR_localCdpState 0;
BA_ "Confidence" SG_ 552 EPBR_chimeRequestLocal 0;
BA_ "Confidence" SG_ 552 EPBR_telltaleLocal 0;
BA_ "GenSigSNA" SG_ 552 EPBR_telltaleLocal "7";
BA_ "Confidence" SG_ 552 EPBR_driverIsLeavingLocal 0;
BA_ "Confidence" SG_ 552 EPBR_driverIsLeavingAnySpeedLoca 0;
BA_ "SystemSignalLongSymbol" SG_ 552 EPBR_driverIsLeavingAnySpeedLoca "EPBR_driverIsLeavingAnySpeedLocal";
BA_ "Confidence" SG_ 552 EPBR_internalCDPRequest 0;
BA_ "Confidence" SG_ 552 EPBR_esmSpeedClass 0;
BA_ "Confidence" SG_ 552 EPBR_learnedEpbConfig 0;
BA_ "Confidence" SG_ 552 EPBR_internalStatusCounter 0;
BA_ "Confidence" SG_ 552 EPBR_internalStatusChecksum 0;
BA_ "Confidence" SG_ 742 EPBR_frontSeatCushionFanCur 0;
BA_ "Confidence" SG_ 742 EPBR_frontSeatBackrestFanCur 0;
BA_ "Confidence" SG_ 742 EPBR_frontSeatCushionFanDuty 0;
BA_ "Confidence" SG_ 742 EPBR_frontSeatCushionFanEn 0;
BA_ "Confidence" SG_ 742 EPBR_frontSeatBackrestFanEn 0;
BA_ "Confidence" SG_ 742 EPBR_frontSeatBackrestFanDuty 0;
BA_ "Confidence" SG_ 742 EPBR_seat2RControllerCurrent 0;
BA_ "Confidence" SG_ 744 EPBR_systemStatus 0;
BA_ "Confidence" SG_ 744 EPBR_freeRollModeStatus 0;
BA_ "Confidence" SG_ 744 EPBR_driverIsLeaving 0;
BA_ "Confidence" SG_ 744 EPBR_driverIsLeavingAnySpeed 0;
BA_ "Confidence" SG_ 744 EPBR_systemCdpAvailable 0;
BA_ "Confidence" SG_ 744 EPBR_chimeRequest 0;
BA_ "Confidence" SG_ 744 EPBR_telltale 0;
BA_ "GenSigSNA" SG_ 744 EPBR_telltale "7";
BA_ "Confidence" SG_ 744 EPBR_audioCurrentSpikeDetected 0;
BA_ "Confidence" SG_ 744 EPBR_redundantBrakingEnabled 0;
BA_ "Confidence" SG_ 744 EPBR_summonEnabled 0;
BA_ "Confidence" SG_ 744 EPBR_brakeLight 0;
BA_ "Confidence" SG_ 744 EPBR_epbConfigMismatch 0;
BA_ "Confidence" SG_ 744 EPBR_brakeConfirmedPressed 0;
BA_ "Confidence" SG_ 744 EPBR_requestUserConfirmation 0;
BA_ "Confidence" SG_ 744 EPBR_uiWinchModeMiscBlocking 0;
BA_ "Confidence" SG_ 744 EPBR_winchModeActive 0;
BA_ "Confidence" SG_ 744 EPBR_updateMode 0;
BA_ "Confidence" SG_ 744 EPBR_winchModePermissive 0;
BA_ "Confidence" SG_ 744 EPBR_winchModePending 0;
BA_ "Confidence" SG_ 744 EPBR_cdpRequest 0;
BA_ "Confidence" SG_ 744 EPBR_uiParkAvailable 0;
BA_ "Confidence" SG_ 744 EPBR_brakeDiscWipeRequest 0;
BA_ "GenSigSNA" SG_ 744 EPBR_brakeDiscWipeRequest "3";
BA_ "Confidence" SG_ 744 EPBR_showUiGearShifter 0;
BA_ "Confidence" SG_ 744 EPBR_uiWinchModeLvStatus 0;
BA_ "Confidence" SG_ 744 EPBR_contactorCycleNotNeededForW 0;
BA_ "SystemSignalLongSymbol" SG_ 744 EPBR_contactorCycleNotNeededForW "EPBR_contactorCycleNotNeededForWinchEntry";
BA_ "Confidence" SG_ 744 EPBR_autonomyBehavior 0;
BA_ "Confidence" SG_ 744 EPBR_showStalkFaultedOnUi 0;
BA_ "Confidence" SG_ 744 EPBR_espPowerRequest 0;
BA_ "Confidence" SG_ 744 EPBR_okToPark 0;
BA_ "Confidence" SG_ 744 EPBR_hornRequest 0;
BA_ "Confidence" SG_ 744 EPBR_winchModeAvailable 0;
BA_ "Confidence" SG_ 744 EPBR_bothDisconnected 0;
BA_ "Confidence" SG_ 744 EPBR_blockDrive 0;
BA_ "Confidence" SG_ 744 EPBR_statusCounter 0;
BA_ "Confidence" SG_ 744 EPBR_statusChecksum 0;
BA_ "Confidence" SG_ 1575 EPBR_udsResponseData_H 1;
BA_ "Confidence" SG_ 1575 EPBR_udsResponseData_L 1;
BA_ "Confidence" SG_ 981 ESP_matrixIndex 1;
BA_ "SystemSignalLongSymbol" SG_ 981 ESP_a193_DIchassisControlChecksu "ESP_a193_DIchassisControlChecksum";
BA_ "SystemSignalLongSymbol" SG_ 981 ESP_a269_DIRELTorqueCommandInval "ESP_a269_DIRELTorqueCommandInvalid";
BA_ "SystemSignalLongSymbol" SG_ 981 ESP_a271_DIRELTorqueActualInvali "ESP_a271_DIRELTorqueActualInvalid";
BA_ "SystemSignalLongSymbol" SG_ 981 ESP_a276_DIRERTorqueCommandInval "ESP_a276_DIRERTorqueCommandInvalid";
BA_ "SystemSignalLongSymbol" SG_ 981 ESP_a278_DIRERTorqueActualInvali "ESP_a278_DIRERTorqueActualInvalid";
BA_ "SystemSignalLongSymbol" SG_ 981 ESP_a279_lifetimeManagementOverr "ESP_a279_lifetimeManagementOverrun";
BA_ "SystemSignalLongSymbol" SG_ 981 ESP_a282_trackModeABSRequestInva "ESP_a282_trackModeABSRequestInvalid";
BA_ "SystemSignalLongSymbol" SG_ 981 ESP_a283_secondaryCollisionMitig "ESP_a283_secondaryCollisionMitigationActive";
BA_ "SystemSignalLongSymbol" SG_ 981 ESP_a284_scmRequestInvalidChecks "ESP_a284_scmRequestInvalidChecksum";
BA_ "SystemSignalLongSymbol" SG_ 981 ESP_a287_failedBrakeCircuitDetec "ESP_a287_failedBrakeCircuitDetected";
BA_ "SystemSignalLongSymbol" SG_ 981 ESP_a296_roadWheelAngleHealthDeg "ESP_a296_roadWheelAngleHealthDegraded";
BA_ "SystemSignalLongSymbol" SG_ 981 ESP_a297_roadWheelAngleHealthFau "ESP_a297_roadWheelAngleHealthFaulted";
BA_ "SystemSignalLongSymbol" SG_ 981 ESP_a298_RSArearSteerStatusTimeo "ESP_a298_RSArearSteerStatusTimeout";
BA_ "SystemSignalLongSymbol" SG_ 981 ESP_a300_RSArearSteerStatusCheck "ESP_a300_RSArearSteerStatusChecksum";
BA_ "SystemSignalLongSymbol" SG_ 981 ESP_a302_rearRoadWheelAngleHealt "ESP_a302_rearRoadWheelAngleHealthDegraded";
BA_ "SystemSignalLongSymbol" SG_ 981 ESP_a303_rearRoadWheelAngleHealt "ESP_a303_rearRoadWheelAngleHealthFaulted";
BA_ "SystemSignalLongSymbol" SG_ 981 ESP_a304_rearVCLVPowerStateTimeo "ESP_a304_rearVCLVPowerStateTimeout";
BA_ "SystemSignalLongSymbol" SG_ 981 ESP_a306_rearVCLVPowerStateCheck "ESP_a306_rearVCLVPowerStateChecksum";
BA_ "SystemSignalLongSymbol" SG_ 981 ESP_a307_rearVCLVPowerStateCount "ESP_a307_rearVCLVPowerStateCounter";
BA_ "SystemSignalLongSymbol" SG_ 981 ESP_a310_brakeLatencyReductionAc "ESP_a310_brakeLatencyReductionActive";
BA_ "SystemSignalLongSymbol" SG_ 981 ESP_a319_AES_BackupActuatorActiv "ESP_a319_AES_BackupActuatorActive";
BA_ "SystemSignalLongSymbol" SG_ 981 ESP_a334_BrakePedalAppliedInvali "ESP_a334_BrakePedalAppliedInvalid";
BA_ "SystemSignalLongSymbol" SG_ 981 ESP_a337_pReductionPotentialInva "ESP_a337_pReductionPotentialInvalid";
BA_ "SystemSignalLongSymbol" SG_ 981 ESP_a341_EnhancedPressureBuildAc "ESP_a341_EnhancedPressureBuildActive";
BA_ "SystemSignalLongSymbol" SG_ 981 ESP_a342_EnhancedPressureBuildNo "ESP_a342_EnhancedPressureBuildNotAvailable";
BA_ "SystemSignalLongSymbol" SG_ 981 ESP_a343_EnhancedPressureBuildLt "ESP_a343_EnhancedPressureBuildLtmReached";
BA_ "SystemSignalLongSymbol" SG_ 981 ESP_a351_ActuatorYellowLampReque "ESP_a351_ActuatorYellowLampRequested";
BA_ "SystemSignalLongSymbol" SG_ 981 ESP_a353_PressureSensorImplausHi "ESP_a353_PressureSensorImplausHigh";
BA_ "SystemSignalLongSymbol" SG_ 981 ESP_a358_externalActuatorFallbac "ESP_a358_externalActuatorFallback";
BA_ "SystemSignalLongSymbol" SG_ 981 ESP_a359_externalActuatorNoExtRe "ESP_a359_externalActuatorNoExtReq";
BA_ "SystemSignalLongSymbol" SG_ 981 ESP_a362_BBbrakeActuationChecksu "ESP_a362_BBbrakeActuationChecksum";
BA_ "SystemSignalLongSymbol" SG_ 981 ESP_a366_ActuatorBlendingModeReq "ESP_a366_ActuatorBlendingModeReqNotAvailable";
BA_ "SystemSignalLongSymbol" SG_ 981 ESP_a367_CBDS_fillBufferThreshol "ESP_a367_CBDS_fillBufferThreshold";
BA_ "SystemSignalLongSymbol" SG_ 981 ESP_a369_LargeLeakageDetectedByD "ESP_a369_LargeLeakageDetectedByDPB";
BA_ "SystemSignalLongSymbol" SG_ 981 ESP_a379_DASredundantBrakingCont "ESP_a379_DASredundantBrakingControlPartyChecksum";
BA_ "SystemSignalLongSymbol" SG_ 981 ESP_a380_DASredundantBrakingCont "ESP_a380_DASredundantBrakingControlPartyCounter";
BA_ "SystemSignalLongSymbol" SG_ 981 ESP_a381_DASredundantBrakingCont "ESP_a381_DASredundantBrakingControlPartyDLC";
BA_ "SystemSignalLongSymbol" SG_ 981 ESP_a382_DASredundantBrakingCont "ESP_a382_DASredundantBrakingControlPartyTimeout";
BA_ "SystemSignalLongSymbol" SG_ 981 ESP_a383_DASredundantBrakingCont "ESP_a383_DASredundantBrakingControlChassisChecksum";
BA_ "SystemSignalLongSymbol" SG_ 981 ESP_a384_DASredundantBrakingCont "ESP_a384_DASredundantBrakingControlChassisCounter";
BA_ "SystemSignalLongSymbol" SG_ 981 ESP_a385_DASredundantBrakingCont "ESP_a385_DASredundantBrakingControlChassisDLC";
BA_ "SystemSignalLongSymbol" SG_ 981 ESP_a386_DASredundantBrakingCont "ESP_a386_DASredundantBrakingControlChassisTimeout";
BA_ "SystemSignalLongSymbol" SG_ 981 ESP_a392_driverlessArmingUnavail "ESP_a392_driverlessArmingUnavailable";
BA_ "SystemSignalLongSymbol" SG_ 981 ESP_a406_DIespActuatorTestTimeou "ESP_a406_DIespActuatorTestTimeout";
BA_ "SystemSignalLongSymbol" SG_ 981 ESP_a407_DIespActuatorTestChecks "ESP_a407_DIespActuatorTestChecksum";
BA_ "SystemSignalLongSymbol" SG_ 981 ESP_a409_DIespActuatorTestCounte "ESP_a409_DIespActuatorTestCounter";
BA_ "Confidence" SG_ 808 ESP_infoIndex 1;
BA_ "Confidence" SG_ 808 ESP_infoBuildType 0;
BA_ "Confidence" SG_ 808 ESP_vehFlashMode 0;
BA_ "Confidence" SG_ 808 ESP_infoComponentID 0;
BA_ "Confidence" SG_ 808 ESP_infoPcbaID 0;
BA_ "Confidence" SG_ 808 ESP_infoAssemblyID 0;
BA_ "Confidence" SG_ 808 ESP_infoUsageID 0;
BA_ "Confidence" SG_ 808 ESP_infoSubUsageID 0;
BA_ "Confidence" SG_ 808 ESP_infoApplicationCRC 1;
BA_ "Confidence" SG_ 808 ESP_infoVehicleVariant 0;
BA_ "Confidence" SG_ 808 ESP_infoSubcomponent1 0;
BA_ "Confidence" SG_ 808 ESP_infoBootUdsProtoVersion 0;
BA_ "Confidence" SG_ 808 ESP_infoBootloaderCRC 0;
BA_ "Confidence" SG_ 808 ESP_infoVariantCRC 1;
BA_ "Confidence" SG_ 1236 ESP_party3Crc 0;
BA_ "Confidence" SG_ 1236 ESP_party3Counter 0;
BA_ "Confidence" SG_ 1236 ESP_absActive 0;
BA_ "Confidence" SG_ 1236 ESP_vehicleStandstill 0;
BA_ "Confidence" SG_ 1236 ESP_vehicleStandstillQF 0;
BA_ "Confidence" SG_ 1236 ESP_pEstMaximum 0;
BA_ "Confidence" SG_ 1236 ESP_privateVehicleSpd 0;
BA_ "Confidence" SG_ 1236 ESP_decoupledBrakePressOffsetCom 0;
BA_ "GenSigSNA" SG_ 1236 ESP_decoupledBrakePressOffsetCom "127";
BA_ "SystemSignalLongSymbol" SG_ 1236 ESP_decoupledBrakePressOffsetCom "ESP_decoupledBrakePressOffsetComp";
BA_ "Confidence" SG_ 1236 ESP_privateVehicleSpdQF 0;
BA_ "Confidence" SG_ 1236 ESP_brakeMasterCylPress 0;
BA_ "GenSigSNA" SG_ 1236 ESP_brakeMasterCylPress "1023";
BA_ "Confidence" SG_ 1236 ESP_brakeMasterCylPressQF 0;
BA_ "Confidence" SG_ 325 ESP_statusChecksum 0;
BA_ "Confidence" SG_ 325 ESP_statusCounter 0;
BA_ "Confidence" SG_ 325 ESP_espModeActive 0;
BA_ "Confidence" SG_ 325 ESP_stabilityControlSts2 0;
BA_ "Confidence" SG_ 325 ESP_ebdFaultLamp 0;
BA_ "Confidence" SG_ 325 ESP_absFaultLamp 0;
BA_ "Confidence" SG_ 325 ESP_espFaultLamp 0;
BA_ "Confidence" SG_ 325 ESP_hydraulicBoostEnabled 0;
BA_ "Confidence" SG_ 325 ESP_espLampFlash 0;
BA_ "Confidence" SG_ 325 ESP_brakeLamp 0;
BA_ "Confidence" SG_ 325 ESP_absBrakeEvent2 0;
BA_ "Confidence" SG_ 325 ESP_longitudinalAccelQF 0;
BA_ "Confidence" SG_ 325 ESP_lateralAccelQF 0;
BA_ "Confidence" SG_ 325 ESP_yawRateQF 0;
BA_ "Confidence" SG_ 325 ESP_steeringAngleQF 0;
BA_ "Confidence" SG_ 325 ESP_brakeDiscWipingActive 0;
BA_ "Confidence" SG_ 325 ESP_driverBrakeApply 0;
BA_ "GenSigSNA" SG_ 325 ESP_driverBrakeApply "3";
BA_ "Confidence" SG_ 325 ESP_brakeApply 0;
BA_ "Confidence" SG_ 325 ESP_aesPrimaryActuatorStatus 0;
BA_ "Confidence" SG_ 325 ESP_cdpStatus 0;
BA_ "Confidence" SG_ 325 ESP_ptcTargetState 0;
BA_ "GenSigSNA" SG_ 325 ESP_ptcTargetState "3";
BA_ "Confidence" SG_ 325 ESP_btcTargetState 0;
BA_ "GenSigSNA" SG_ 325 ESP_btcTargetState "3";
BA_ "Confidence" SG_ 325 ESP_decoupledBrakePressEst 0;
BA_ "GenSigSNA" SG_ 325 ESP_decoupledBrakePressEst "255";
BA_ "Confidence" SG_ 325 ESP_ebrStandstillSkid 0;
BA_ "Confidence" SG_ 325 ESP_ebrStatus 0;
BA_ "Confidence" SG_ 325 ESP_brakeTorqueTarget 0;
BA_ "Confidence" SG_ 1621 ESP_udsResponseData 1;
BA_ "Confidence" SG_ 373 ESP_wheelSpeedFrL 1;
BA_ "Confidence" SG_ 373 ESP_wheelSpeedFrR 1;
BA_ "Confidence" SG_ 373 ESP_wheelSpeedReL 1;
BA_ "Confidence" SG_ 373 ESP_wheelSpeedReR 1;
BA_ "Confidence" SG_ 1662 EVSE_isoTpToVehData 0;
BA_ "Confidence" SG_ 1322 FC_alertID 1;
BA_ "Confidence" SG_ 1322 FC_alertType 1;
BA_ "Confidence" SG_ 1322 FC_a146_CA_flybackOnTime 1;
BA_ "Confidence" SG_ 1322 FC_a146_CA_flybackV 1;
BA_ "Confidence" SG_ 1322 FC_a146_CA_flybackTargetV 1;
BA_ "Confidence" SG_ 1117 FC_evseBillingDataSelect 1;
BA_ "Confidence" SG_ 1117 FC_evseBillingEnergy 0;
BA_ "Confidence" SG_ 1117 FC_evseMeterPower 0;
BA_ "Confidence" SG_ 1117 FC_evseMeterCurrent 0;
BA_ "Confidence" SG_ 1117 FC_evseMeterVoltage 0;
BA_ "Confidence" SG_ 1117 FC_evseMeterFwGitHash 0;
BA_ "Confidence" SG_ 1334 FC_evseBilling2DataSelect 1;
BA_ "Confidence" SG_ 1334 FC_evsePpuEnabled 0;
BA_ "Confidence" SG_ 1334 FC_evseBillingEnergyHighRes 0;
BA_ "GenSigSNA" SG_ 1334 FC_evseBillingEnergyHighRes "16777215";
BA_ "Confidence" SG_ 1303 FC_id 0;
BA_ "Confidence" SG_ 1303 FC_sessionId 0;
BA_ "Confidence" SG_ 1310 FC_infoIndex 1;
BA_ "Confidence" SG_ 1310 FC_infoBuildType 0;
BA_ "Confidence" SG_ 1310 FC_infoBuildConfigID 0;
BA_ "Confidence" SG_ 1310 FC_infoHardwareID 0;
BA_ "Confidence" SG_ 1310 FC_infoComponentID 0;
BA_ "Confidence" SG_ 1310 FC_infoPcbaID 0;
BA_ "Confidence" SG_ 1310 FC_infoAssemblyID 0;
BA_ "Confidence" SG_ 1310 FC_infoUsageID 0;
BA_ "Confidence" SG_ 1310 FC_infoSubUsageID 0;
BA_ "Confidence" SG_ 1310 FC_infoApplicationCRC 0;
BA_ "Confidence" SG_ 1310 FC_infoBootSvnRev 1;
BA_ "Confidence" SG_ 1310 FC_infoCPLDVersionMajor 1;
BA_ "Confidence" SG_ 1310 FC_infoCPLDVersionMinor 1;
BA_ "Confidence" SG_ 1310 FC_infoAppGitHashBytes 0;
BA_ "Confidence" SG_ 1310 FC_infoBootGitHashBytes 0;
BA_ "Confidence" SG_ 1310 FC_infoPlatformType 0;
BA_ "Confidence" SG_ 1310 FC_infoMajorVersion 0;
BA_ "Confidence" SG_ 1310 FC_infoBranchOrigin 0;
BA_ "Confidence" SG_ 1310 FC_infoMaturity 0;
BA_ "Confidence" SG_ 1310 FC_infoHardwareRevision 0;
BA_ "Confidence" SG_ 1310 FC_infoBootUdsProtoVersion 1;
BA_ "Confidence" SG_ 1310 FC_partNumChar01 0;
BA_ "Confidence" SG_ 1310 FC_partNumChar02 0;
BA_ "Confidence" SG_ 1310 FC_partNumChar03 0;
BA_ "Confidence" SG_ 1310 FC_partNumChar04 0;
BA_ "Confidence" SG_ 1310 FC_partNumChar05 0;
BA_ "Confidence" SG_ 1310 FC_partNumChar06 0;
BA_ "Confidence" SG_ 1310 FC_partNumChar07 0;
BA_ "Confidence" SG_ 1310 FC_partNumChar08 0;
BA_ "Confidence" SG_ 1310 FC_partNumChar09 0;
BA_ "Confidence" SG_ 1310 FC_partNumChar10 0;
BA_ "Confidence" SG_ 1310 FC_partNumChar11 0;
BA_ "Confidence" SG_ 1310 FC_partNumChar12 0;
BA_ "Confidence" SG_ 1310 FC_partNumChar13 0;
BA_ "Confidence" SG_ 1310 FC_partNumChar14 0;
BA_ "Confidence" SG_ 1310 FC_partNumChar15 0;
BA_ "Confidence" SG_ 1310 FC_partNumChar16 0;
BA_ "Confidence" SG_ 1310 FC_partNumChar17 0;
BA_ "Confidence" SG_ 1310 FC_partNumChar18 0;
BA_ "Confidence" SG_ 1310 FC_partNumChar19 0;
BA_ "Confidence" SG_ 1310 FC_partNumChar20 0;
BA_ "Confidence" SG_ 580 FC_powerLimit 0;
BA_ "GenSigSNA" SG_ 580 FC_powerLimit "8191";
BA_ "Confidence" SG_ 580 FC_currentLimit 0;
BA_ "GenSigSNA" SG_ 580 FC_currentLimit "8191";
BA_ "Confidence" SG_ 580 FC_maxVoltageLimit 0;
BA_ "GenSigSNA" SG_ 580 FC_maxVoltageLimit "8191";
BA_ "Confidence" SG_ 580 FC_minVoltageLimit 0;
BA_ "GenSigSNA" SG_ 580 FC_minVoltageLimit "8191";
BA_ "Confidence" SG_ 702 FC_powerLimit_value 0;
BA_ "GenSigSNA" SG_ 702 FC_powerLimit_value "32768";
BA_ "Confidence" SG_ 702 FC_currentLimit_value 0;
BA_ "GenSigSNA" SG_ 702 FC_currentLimit_value "32768";
BA_ "Confidence" SG_ 702 FC_minVoltageLimit_value 0;
BA_ "GenSigSNA" SG_ 702 FC_minVoltageLimit_value "32768";
BA_ "Confidence" SG_ 702 FC_powerLimit_exp 0;
BA_ "Confidence" SG_ 702 FC_currentLimit_exp 0;
BA_ "Confidence" SG_ 702 FC_minVoltageLimit_exp 0;
BA_ "Confidence" SG_ 1345 FC_maxPowerLimit 0;
BA_ "GenSigSNA" SG_ 1345 FC_maxPowerLimit "8191";
BA_ "Confidence" SG_ 1345 FC_maxCurrentLimit 0;
BA_ "GenSigSNA" SG_ 1345 FC_maxCurrentLimit "8191";
BA_ "Confidence" SG_ 1300 FC_serialDataSelect 1;
BA_ "Confidence" SG_ 1300 FC_serialChar01 0;
BA_ "Confidence" SG_ 1300 FC_serialChar02 0;
BA_ "Confidence" SG_ 1300 FC_serialChar03 0;
BA_ "Confidence" SG_ 1300 FC_serialChar04 0;
BA_ "Confidence" SG_ 1300 FC_serialChar05 0;
BA_ "Confidence" SG_ 1300 FC_serialChar06 0;
BA_ "Confidence" SG_ 1300 FC_serialChar07 0;
BA_ "Confidence" SG_ 1300 FC_serialChar08 0;
BA_ "Confidence" SG_ 1300 FC_serialChar09 0;
BA_ "Confidence" SG_ 1300 FC_serialChar10 0;
BA_ "Confidence" SG_ 1300 FC_serialChar11 0;
BA_ "Confidence" SG_ 1300 FC_serialChar12 0;
BA_ "Confidence" SG_ 1300 FC_serialChar13 0;
BA_ "Confidence" SG_ 1300 FC_serialChar14 0;
BA_ "Confidence" SG_ 1300 FC_serialChar15 0;
BA_ "Confidence" SG_ 1300 FC_serialChar16 0;
BA_ "Confidence" SG_ 1300 FC_serialChar17 0;
BA_ "Confidence" SG_ 532 FC_protocolVersion 0;
BA_ "Confidence" SG_ 532 FC_statusCode 0;
BA_ "GenSigSNA" SG_ 532 FC_statusCode "0";
BA_ "Confidence" SG_ 532 FC_deprecated1 0;
BA_ "Confidence" SG_ 532 FC_deprecated2 0;
BA_ "Confidence" SG_ 532 FC_deprecated3 0;
BA_ "Confidence" SG_ 532 FC_adapterLocked 0;
BA_ "Confidence" SG_ 532 FC_minCurrentLimit 0;
BA_ "Confidence" SG_ 532 FC_type 0;
BA_ "GenSigSNA" SG_ 532 FC_type "7";
BA_ "Confidence" SG_ 532 FC_dcCurrent 0;
BA_ "Confidence" SG_ 532 FC_postID 0;
BA_ "GenSigSNA" SG_ 532 FC_postID "3";
BA_ "Confidence" SG_ 532 FC_dcVoltage 0;
BA_ "Confidence" SG_ 532 FC_leakageTestNotSupported 0;
BA_ "Confidence" SG_ 532 FC_dischargeSupported 0;
BA_ "Confidence" SG_ 533 FC_externalIsolationResistance 0;
BA_ "GenSigSNA" SG_ 533 FC_externalIsolationResistance "255";
BA_ "Confidence" SG_ 535 FC_status3DataSelect 1;
BA_ "Confidence" SG_ 535 FC_status3DummySig 0;
BA_ "Confidence" SG_ 535 FC_class 0;
BA_ "GenSigSNA" SG_ 535 FC_class "0";
BA_ "Confidence" SG_ 535 FC_brand 0;
BA_ "GenSigSNA" SG_ 535 FC_brand "0";
BA_ "Confidence" SG_ 535 FC_coolingType 0;
BA_ "GenSigSNA" SG_ 535 FC_coolingType "0";
BA_ "Confidence" SG_ 535 FC_uiStopType 0;
BA_ "GenSigSNA" SG_ 535 FC_uiStopType "0";
BA_ "Confidence" SG_ 535 FC_emergencyShutdownSupported 0;
BA_ "Confidence" SG_ 535 FC_generation 0;
BA_ "GenSigSNA" SG_ 535 FC_generation "0";
BA_ "Confidence" SG_ 535 FC_billingEnergy 1;
BA_ "Confidence" SG_ 888 GTW_GTW_SOS_ECALL_RQST 0;
BA_ "Confidence" SG_ 888 GTW_LTE_ECALL_LOCK 0;
VAL_ 1000 EPBR_matrixIndex 6 "AlertMatrix6" 5 "AlertMatrix5" 4 "AlertMatrix4" 3 "AlertMatrix3" 2 "AlertMatrix2" 1 "AlertMatrix1" 0 "AlertMatrix0" ;
VAL_ 2024 EPBR_infoIndex 255 "END" 41 "SUBCOMPONENT14" 40 "SUBCOMPONENT13" 39 "SUBCOMPONENT12" 38 "SUBCOMPONENT11" 37 "SUBCOMPONENT10" 36 "SUBCOMPONENT9" 35 "SUBCOMPONENT8" 34 "SUBCOMPONENT7" 33 "SUBCOMPONENT6" 32 "SUBCOMPONENT5" 31 "SUBCOMPONENT4" 24 "SUBCOMPONENT3" 23 "SUBCOMPONENT2" 20 "UDS_PROTOCOL_BOOTCRC" 19 "VERSION_DEPRECATED" 18 "BOOTLOADER_GITHASH" 17 "APP_GITHASH" 16 "SUBCOMPONENT1" 15 "BOOTLOADER_CRC" 14 "BOOTLOADER_SVN" 13 "APP_CRC" 11 "PCBAID_ASSYID_USAGEID" 10 "BUILD_HWID_COMPONENTID" 9 "DEPRECATED_9" 8 "DEPRECATED_8" 7 "DEPRECATED_7" 6 "DEPRECATED_6" 5 "DEPRECATED_5" 4 "DEPRECATED_4" 3 "DEPRECATED_3" 2 "DEPRECATED_2" 1 "DEPRECATED_1" 0 "DEPRECATED_0" ;
VAL_ 2024 EPBR_infoBuildType 4 "INFO_MFG_BUILD" 3 "INFO_TRACEABLE_CI_BUILD" 2 "INFO_LOCAL_BUILD" 1 "INFO_PLATFORM_BUILD" 0 "INFO_UNKNOWN_BUILD" ;
VAL_ 2024 EPBR_infoAssemblyId 255 "ASSEMBLY_SNA" 1 "ASSEMBLY1" ;
VAL_ 552 EPBR_unitStatus 23 "EPB_STATUS_COUNT" 22 "EPB_STATUS_AUTONOMY_OPEN" 21 "EPB_STATUS_FREE_ROLL_MODE" 20 "EPB_STATUS_DYNAMIC_PARKING" 19 "EPB_STATUS_EXTERNAL_PARKING" 18 "EPB_STATUS_RELEASING_FOR_EXTERNAL_PARK" 17 "EPB_STATUS_EXTERNAL_DYNAMIC" 16 "EPB_STATUS_SUMMON_PARKING" 15 "EPB_STATUS_SUMMON_RELEASING" 14 "EPB_STATUS_SUMMON" 13 "EPB_STATUS_WINCHMODE_PENDING" 12 "EPB_STATUS_PARK_PENDING" 11 "EPB_STATUS_SERVICE_RELEASING" 10 "EPB_STATUS_RELEASING" 9 "EPB_STATUS_DYNAMIC_APPLYING" 8 "EPB_STATUS_PARKING" 7 "EPB_STATUS_WINCHMODE_RELEASING" 6 "EPB_STATUS_WINCHMODE" 5 "EPB_STATUS_SERVICE" 4 "EPB_STATUS_START" 3 "EPB_STATUS_PARK" 2 "EPB_STATUS_DYNAMIC" 1 "EPB_STATUS_OPEN" 0 "EPB_STATUS_UNKNOWN" ;
VAL_ 552 EPBR_unitFaultStatus 3 "EPB_STATUS_FAULT_IDLE" 2 "EPB_STATUS_FAULT" 1 "EPB_STATUS_RETRY" 0 "EPB_STATUS_NOMINAL" ;
VAL_ 552 EPBR_summonState 6 "EPB_SUMMON_UNAVAILABLE" 5 "EPB_SUMMON_FAULT" 4 "EPB_SUMMON_COMPLETE" 3 "EPB_SUMMON_ACTIVE" 2 "EPB_SUMMON_ARMED" 1 "EPB_SUMMON_IDLE" 0 "EPB_SUMMON_INIT" ;
VAL_ 552 EPBR_csmFaultReason 23 "CSM_FAULT_REMOTE_MIA" 22 "CSM_FAULT_NVM_MISMATCH" 21 "CSM_FAULT_EPBM_MIA" 20 "CSM_FAULT_MOTOR_NOT_READY" 19 "CSM_FAULT_MOTOR_ACTIVE_FAULT" 18 "CSM_FAULT_MOTOR_IDLE_FAULT" 17 "CSM_FAULT_TIMEOUT_EPBM_START" 16 "CSM_FAULT_TIMEOUT_NO_RAMP" 15 "CSM_FAULT_TIMEOUT_EPBM_CUTOFF" 14 "CSM_FAULT_TIMEOUT_RELEASE_COMPLETE" 13 "CSM_FAULT_TIMEOUT_RELEASE_NO_LOAD" 12 "CSM_FAULT_TIMEOUT_RELEASE_WAIT_FOR_ENDSTOP" 11 "CSM_FAULT_TIMEOUT_RELEASE_INRUSH" 10 "CSM_FAULT_TIMEOUT_EPBM_WAIT_FOR_CLAMP" 9 "CSM_FAULT_TIMEOUT_EPB_WAIT_FOR_CLAMP" 8 "CSM_FAULT_TIMEOUT_APPLY_INRUSH" 7 "CSM_FAULT_TIMEOUT_APPLY_COMPLETE" 6 "CSM_FAULT_RELEASE_BLOCKED" 5 "CSM_FAULT_APPLY_BLOCKED" 4 "CSM_FAULT_TIMEOUT_CALIBRATE" 3 "CSM_FAULT_STATE_MISMATCH" 2 "CSM_FAULT_EPBM_FAULTED" 1 "CSM_FAULT_EPBM_DISABLED" 0 "CSM_FAULT_NONE" ;
VAL_ 552 EPBR_esmOperationTrigger 50 "EPB_TRIGGER_ACTIVE_DECEL_DAS_STATIC" 49 "EPB_TRIGGER_ACTIVE_DECEL_CDP_DOWN" 48 "EPB_TRIGGER_AP_IS_LEAVING" 47 "EPB_TRIGGER_RECOVERY_PARK" 46 "EPB_TRIGGER_SPEED_SOURCES_LOST" 45 "EPB_TRIGGER_ACTIVE_DECEL_OKTOPARK" 44 "EPB_TRIGGER_ACTIVE_DECEL_FAST" 43 "EPB_TRIGGER_STEERING_ACTIVE_DECEL" 42 "EPB_TRIGGER_LV_ACTIVE_DECEL" 41 "EPB_TRIGGER_CDP_PANIC_MODE_READY" 40 "EPB_TRIGGER_CDP_PANIC_MODE_TIMEOUT" 39 "EPB_TRIGGER_DI_PARK" 38 "EPB_TRIGGER_FREE_ROLL_PARK_FOR_HANDLE_PULLED" 37 "EPB_TRIGGER_LOW_BRAKE_FLUID_MODE_DYNAMIC" 36 "EPB_TRIGGER_LOW_BRAKE_FLUID_MODE_DYNAMIC_PARK" 35 "EPB_TRIGGER_LOW_BRAKE_FLUID_MODE_PARK" 34 "EPB_TRIGGER_STATIONARY_DETECT" 33 "EPB_TRIGGER_TOUCHSCREEN_INVALID" 32 "EPB_TRIGGER_UI_DOOR_OPEN_REQUEST" 31 "EPB_TRIGGER_AUTOPARK_END" 30 "EPB_TRIGGER_DRIVER_IS_LEAVING" 29 "EPB_TRIGGER_SYSTEM_APPLY" 28 "EPB_TRIGGER_ACCELERATION" 27 "EPB_TRIGGER_EPBM_DISQUALIFIED" 26 "EPB_TRIGGER_DISQUALIFIED" 25 "EPB_TRIGGER_SUMMON_FAULT" 24 "EPB_TRIGGER_FAULT" 23 "EPB_TRIGGER_SUMMON_COMPLETE" 22 "EPB_TRIGGER_REAPPLY" 21 "EPB_TRIGGER_SAVESTATE_ON_BOOT" 20 "EPB_TRIGGER_TIMEOUT" 19 "EPB_TRIGGER_SPEED_FAST" 18 "EPB_TRIGGER_SPEED_OKAYTOPARK" 17 "EPB_TRIGGER_SPEED_STOPPED" 16 "EPB_TRIGGER_USER_CANCEL" 15 "EPB_TRIGGER_USER_CONFIRMED" 14 "EPB_TRIGGER_DIAG_EXIT" 13 "EPB_TRIGGER_DIAG_OPEN" 12 "EPB_TRIGGER_DIAG_CLOSE" 11 "EPB_TRIGGER_SERVICE" 10 "EPB_TRIGGER_WINCHMODE_UNAVAILABLE" 9 "EPB_TRIGGER_WINCHMODE_ENTER" 8 "EPB_TRIGGER_WINCHMODE_EXIT" 7 "EPB_TRIGGER_TOUCHSCREEN" 6 "EPB_TRIGGER_DI_UNPARK" 5 "EPB_TRIGGER_ACTIVE_PARK_REQUEST" 4 "EPB_TRIGGER_PBUTTON_RELEASED" 3 "EPB_TRIGGER_PBUTTON_PRESSED_UNKNOWN" 2 "EPB_TRIGGER_PBUTTON_PRESSED_FAST" 1 "EPB_TRIGGER_PBUTTON_PRESSED_OKTOPARK" 0 "EPB_TRIGGER_PBUTTON_PRESSED_STOPPED" ;
VAL_ 552 EPBR_summonFaultReason 30 "EPB_SUMMONFAULT_MONITOR_TYPE_UNKNOWN" 29 "EPB_SUMMONFAULT_AP_MONITOR" 28 "EPB_SUMMONFAULT_REMOTE_DID_NOT_START" 27 "EPB_SUMMONFAULT_INVALID_REMOTE_STATE" 26 "EPB_SUMMONFAULT_START_IN_UNAVAILABLE" 25 "EPB_SUMMONFAULT_REMOTE_UNIT_FAULTED" 24 "EPB_SUMMONFAULT_LOCAL_UNIT_FAULTED" 23 "EPB_SUMMONFAULT_REMOTE_SUMMON_FAULTED" 22 "EPB_SUMMONFAULT_EPBREMOTE_MIA" 21 "EPB_SUMMONFAULT_PASSIVE_REQUEST" 20 "EPB_SUMMONFAULT_DI_STATE_INVALID" 19 "EPB_SUMMONFAULT_EPB_FAULT" 18 "EPB_SUMMONFAULT_MISMATCH" 17 "EPB_SUMMONFAULT_OOC" 16 "EPB_SUMMONFAULT_PM_REQUEST" 15 "EPB_SUMMONFAULT_PM_MIA" 14 "EPB_SUMMONFAULT_PARK_MIA" 13 "EPB_SUMMONFAULT_EXTERNAL" 12 "EPB_SUMMONFAULT_SPEED" 11 "EPB_SUMMONFAULT_EPBM_REQUEST" 10 "EPB_SUMMONFAULT_EAC_NOT_ALLOWED" 9 "EPB_SUMMONFAULT_VEH_CAN_FAULT" 8 "EPB_SUMMONFAULT_ESP_FAULT" 7 "EPB_SUMMONFAULT_DAS_FAULT" 6 "EPB_SUMMONFAULT_DI_APC_FAULT" 5 "EPB_SUMMONFAULT_DI_FAULT" 4 "EPB_SUMMONFAULT_EPBM_MIA" 3 "EPB_SUMMONFAULT_ESP_MIA" 2 "EPB_SUMMONFAULT_DAS_MIA" 1 "EPB_SUMMONFAULT_DI_MIA" 0 "EPB_SUMMONFAULT_NONE" ;
VAL_ 552 EPBR_localCdpState 2 "EPB_CDP_STATE_FAULT" 1 "EPB_CDP_STATE_VALID" 0 "EPB_CDP_STATE_UNKNOWN" ;
VAL_ 552 EPBR_chimeRequestLocal 4 "EPB_CHIME_REQUEST_ACTIVE_DECEL" 3 "EPB_CHIME_REQUEST_ABOUT_TO_ACTIVE_DECEL" 2 "EPB_CHIME_REQUEST_GPO" 1 "EPB_CHIME_REQUEST_GENERAL" 0 "EPB_CHIME_REQUEST_NONE" ;
VAL_ 552 EPBR_telltaleLocal 7 "EPB_TELLTALE_SNA" 4 "EPB_TELLTALE_LAMP_RED_FLASH" 3 "EPB_TELLTALE_LAMP_AMBER_ON" 2 "EPB_TELLTALE_LAMP_RED_ON" 1 "EPB_TELLTALE_LAMP_RED_PARKED" 0 "EPB_TELLTALE_LAMP_OFF" ;
VAL_ 552 EPBR_internalCDPRequest 1 "EPB_CDP_REQUESTED" 0 "EPB_CDP_NOT_REQUESTED" ;
VAL_ 552 EPBR_esmSpeedClass 4 "ESM_SPEED_CLASS_UNKNOWN" 3 "ESM_SPEED_CLASS_FAST" 2 "ESM_SPEED_CLASS_USER_APPLY_OK" 1 "ESM_SPEED_CLASS_SYSTEM_APPLY_OK" 0 "ESM_SPEED_CLASS_STOPPED" ;
VAL_ 552 EPBR_learnedEpbConfig 11 "EPB_CONFIG_CT_MANDO" 10 "EPB_CONFIG_MODEL3_ZF" 9 "EPB_CONFIG_MODELS_CERAMIC" 8 "EPB_CONFIG_MODELY_PERFORMANCE_V2" 7 "EPB_CONFIG_MODEL3_PERFORMANCE_V2" 6 "EPB_CONFIG_MODELX_BASE" 5 "EPB_CONFIG_MODELY_PERFORMANCE" 4 "EPB_CONFIG_MODELY_BASE" 3 "EPB_CONFIG_MODELS_BASE" 2 "EPB_CONFIG_MODEL3_PERFORMANCE" 1 "EPB_CONFIG_MODEL3_BASE" 0 "EPB_CONFIG_UNKNOWN" ;
VAL_ 744 EPBR_systemStatus 8 "EPB_VEHICLE_STATUS_MISMATCH" 7 "EPB_VEHICLE_STATUS_FAULT_SECURE" 6 "EPB_VEHICLE_STATUS_FAULT" 5 "EPB_VEHICLE_STATUS_RELEASING" 4 "EPB_VEHICLE_STATUS_PARKING" 3 "EPB_VEHICLE_STATUS_DYNAMIC" 2 "EPB_VEHICLE_STATUS_PARKED" 1 "EPB_VEHICLE_STATUS_RELEASED" 0 "EPB_VEHICLE_STATUS_UNKNOWN" ;
VAL_ 744 EPBR_freeRollModeStatus 2 "EPB_FREE_ROLL_MODE_ENABLED" 1 "EPB_FREE_ROLL_MODE_AVAILABLE" 0 "EPB_FREE_ROLL_MODE_UNAVAILABLE" ;
VAL_ 744 EPBR_chimeRequest 4 "EPB_CHIME_REQUEST_ACTIVE_DECEL" 3 "EPB_CHIME_REQUEST_ABOUT_TO_ACTIVE_DECEL" 2 "EPB_CHIME_REQUEST_GPO" 1 "EPB_CHIME_REQUEST_GENERAL" 0 "EPB_CHIME_REQUEST_NONE" ;
VAL_ 744 EPBR_telltale 7 "EPB_TELLTALE_SNA" 4 "EPB_TELLTALE_LAMP_RED_FLASH" 3 "EPB_TELLTALE_LAMP_AMBER_ON" 2 "EPB_TELLTALE_LAMP_RED_ON" 1 "EPB_TELLTALE_LAMP_RED_PARKED" 0 "EPB_TELLTALE_LAMP_OFF" ;
VAL_ 744 EPBR_cdpRequest 1 "EPB_CDP_REQUESTED" 0 "EPB_CDP_NOT_REQUESTED" ;
VAL_ 744 EPBR_uiParkAvailable 2 "EPB_AVAIL_REAPPLIED" 1 "EPB_AVAIL_AVAILABLE" 0 "EPB_AVAIL_NOT_AVAILABLE" ;
VAL_ 744 EPBR_brakeDiscWipeRequest 3 "EPB_BRAKEDISCWIPE_REQUEST_SNA" 2 "EPB_BRAKEDISCWIPE_REQUEST_STRONG" 1 "EPB_BRAKEDISCWIPE_REQUEST_LIGHT" 0 "EPB_BRAKEDISCWIPE_REQUEST_NONE" ;
VAL_ 744 EPBR_uiWinchModeLvStatus 3 "EPB_LV_OK" 2 "EPB_LV_BLOCKED_TIMER_RUNNING" 1 "EPB_LV_BLOCKED_INPUT_VOLTAGE_LOW" 0 "EPB_LV_BLOCKED_BATTERY" ;
VAL_ 744 EPBR_autonomyBehavior 2 "DRIVERLESS_NO_TAKEOVER" 1 "DRIVERLESS_TAKEOVER" 0 "DRIVER" ;
VAL_ 981 ESP_matrixIndex 6 "AlertMatrix6" 5 "AlertMatrix5" 4 "AlertMatrix4" 3 "AlertMatrix3" 2 "AlertMatrix2" 1 "AlertMatrix1" 0 "AlertMatrix0" ;
VAL_ 808 ESP_infoIndex 255 "END" 31 "SUBCOMPONENT_GITHASH" 30 "PACKAGE_SN_8_14" 29 "PACKAGE_SN_1_7" 27 "PACKAGE_PN_15_20" 26 "PACKAGE_PN_8_14" 25 "PACKAGE_PN_1_7" 23 "SUBCOMPONENT2" 22 "VARIANTCRC" 20 "UDS_PROTOCOL_BOOTCRC" 19 "VERSION_DEPRECATED" 18 "BOOTLOADER_GITHASH" 17 "APP_GITHASH" 16 "SUBCOMPONENT" 15 "BOOTLOADER_CRC" 14 "BOOTLOADER_SVN" 13 "APP_CRC" 11 "PCBAID_ASSYID_USAGEID" 10 "BUILD_HWID_COMPONENTID" 9 "DEPRECATED_9" 8 "DEPRECATED_8" 7 "DEPRECATED_7" 6 "DEPRECATED_6" 5 "DEPRECATED_5" 4 "DEPRECATED_4" 3 "DEPRECATED_3" 2 "DEPRECATED_2" 1 "DEPRECATED_1" 0 "DEPRECATED_0" ;
VAL_ 808 ESP_infoBuildType 4 "INFO_MFG_BUILD" 3 "INFO_TRACEABLE_CI_BUILD" 2 "INFO_LOCAL_BUILD" 1 "INFO_PLATFORM_BUILD" 0 "INFO_UNKNOWN_BUILD" ;
VAL_ 808 ESP_vehFlashMode 1 "Development_Mode" 0 "Production_Mode" ;
VAL_ 808 ESP_infoSubUsageID 16 "XCP_Dfive_ESP_CP_CB" 8 "nonXCP_Dfour_ESP_CP_CB" 4 "XCP_Gladiator_ESP" 2 "nonXCP_Rev_C_ESP_Cappella" 0 "nonXCP_Rev_B_ESP_Cappella" ;
VAL_ 808 ESP_infoVehicleVariant 9 "MODEL_3_VARIANT_09" 8 "MODEL_3_VARIANT_08" 7 "MODEL_3_VARIANT_07" 6 "MODEL_3_VARIANT_06" 5 "MODEL_3_VARIANT_05" 4 "MODEL_3_VARIANT_04" 3 "MODEL_3_VARIANT_03" 2 "MODEL_3_VARIANT_02" 1 "MODEL_3_VARIANT_01" ;
VAL_ 1236 ESP_absActive 1 "ABS_ACTIVE" 0 "ABS_NOT_ACTIVE" ;
VAL_ 1236 ESP_vehicleStandstill 1 "STANDSTILL" 0 "NOT_STANDSTILL" ;
VAL_ 1236 ESP_vehicleStandstillQF 2 "STANDSTILL_FAULTED" 1 "STANDSTILL_NORMAL" 0 "STANDSTILL_NOT_INIT" ;
VAL_ 1236 ESP_decoupledBrakePressOffsetCom 127 "SNA" ;
VAL_ 1236 ESP_privateVehicleSpdQF 2 "Faulty" 1 "Normal" 0 "NotInit_orOff" ;
VAL_ 1236 ESP_brakeMasterCylPress 1023 "SNA" ;
VAL_ 1236 ESP_brakeMasterCylPressQF 3 "PRESSURE_FAULTED2" 2 "PRESSURE_FAULTED" 1 "PRESSURE_NORMAL" 0 "PRESSURE_NOT_INITIALIZED" ;
VAL_ 325 ESP_espModeActive 3 "ESP_MODE_03" 2 "ESP_MODE_02" 1 "ESP_MODE_01" 0 "ESP_MODE_00_NORMAL" ;
VAL_ 325 ESP_stabilityControlSts2 3 "FAULTED" 2 "ENGAGED" 1 "ON" 0 "INIT" ;
VAL_ 325 ESP_ebdFaultLamp 1 "EBD_FAULT_LAMP_ON" 0 "EBD_FAULT_LAMP_OFF" ;
VAL_ 325 ESP_absFaultLamp 1 "ABS_FAULT_LAMP_ON" 0 "ABS_FAULT_LAMP_OFF" ;
VAL_ 325 ESP_espFaultLamp 1 "ESP_FAULT_LAMP_ON" 0 "ESP_FAULT_LAMP_OFF" ;
VAL_ 325 ESP_espLampFlash 1 "ESP_LAMP_FLASH" 0 "ESP_LAMP_OFF" ;
VAL_ 325 ESP_brakeLamp 1 "LAMP_ON" 0 "LAMP_OFF" ;
VAL_ 325 ESP_absBrakeEvent2 3 "ABS_EVENT_ACTIVE_REAR" 2 "ABS_EVENT_ACTIVE_FRONT" 1 "ABS_EVENT_ACTIVE_FRONT_REAR" 0 "ABS_EVENT_NOT_ACTIVE" ;
VAL_ 325 ESP_longitudinalAccelQF 1 "IN_SPEC" 0 "UNDEFINABLE_ACCURACY" ;
VAL_ 325 ESP_lateralAccelQF 1 "IN_SPEC" 0 "UNDEFINABLE_ACCURACY" ;
VAL_ 325 ESP_yawRateQF 1 "IN_SPEC" 0 "UNDEFINABLE_ACCURACY" ;
VAL_ 325 ESP_steeringAngleQF 1 "IN_SPEC" 0 "UNDEFINABLE_ACCURACY" ;
VAL_ 325 ESP_brakeDiscWipingActive 1 "BDW_ACTIVE" 0 "BDW_INACTIVE" ;
VAL_ 325 ESP_driverBrakeApply 3 "Faulty_SNA" 2 "Driver_applying_brakes" 1 "Not_Applied" 0 "NotInit_orOff" ;
VAL_ 325 ESP_brakeApply 1 "BLS_ACTIVE" 0 "BLS_INACTIVE" ;
VAL_ 325 ESP_aesPrimaryActuatorStatus 3 "AES_FAILURE" 2 "AES_ACTIVE" 1 "AES_AVAILABLE" 0 "AES_NOT_SUPPORTED_OR_NOT_INIT" ;
VAL_ 325 ESP_cdpStatus 3 "CDP_COMMAND_INVALID" 2 "ACTUATING_EPB_CDP" 1 "CDP_IS_AVAILABLE" 0 "CDP_IS_NOT_AVAILABLE" ;
VAL_ 325 ESP_ptcTargetState 3 "SNA" 2 "ON" 1 "BACKUP" 0 "FAULT" ;
VAL_ 325 ESP_btcTargetState 3 "SNA" 2 "ON" 1 "BACKUP" 0 "OFF" ;
VAL_ 325 ESP_decoupledBrakePressEst 255 "SNA" ;
VAL_ 325 ESP_ebrStandstillSkid 1 "STANDSTILL_SKID_DETECTED" 0 "NO_STANDSTILL_SKID" ;
VAL_ 325 ESP_ebrStatus 3 "EBR_COMMAND_INVALID" 2 "ACTUATING_DI_EBR" 1 "EBR_IS_AVAILABLE" 0 "EBR_IS_NOT_AVAILABLE" ;
VAL_ 373 ESP_wheelSpeedFrL 8191 "SNA" ;
VAL_ 373 ESP_wheelSpeedFrR 8191 "SNA" ;
VAL_ 373 ESP_wheelSpeedReL 8191 "SNA" ;
VAL_ 373 ESP_wheelSpeedReR 8191 "SNA" ;
VAL_ 1322 FC_alertID 321 "a321_FCAlertPlaceholder" 313 "a313_GB_inputVoltageRailOv" 312 "a312_GB_evseLimitsTimeout" 311 "a311_GB_battParamsTimeout" 310 "a310_GB_unused" 309 "a309_GB_unused" 308 "a308_GB_evseConLockTimeout" 307 "a307_GB_fcContOpenTimeout" 306 "a306_GB_vehReadyDeasserted" 305 "a305_GB_posRecogTimeout" 304 "a304_GB_unused" 303 "a303_GB_negRecogTimeout" 302 "a302_GB_unused" 301 "a301_GB_unused" 300 "a300_GB_unused" 299 "a299_GB_evseReadyTimeout" 298 "a298_GB_bmsCtrCloseTimeout" 297 "a297_GB_unused" 296 "a296_GB_invalidPilotTransitio" 295 "a295_GB_pilotRationality" 294 "a294_GB_unused" 293 "a293_GB_proxRationality" 292 "a292_GB_vehConLockTimeout" 291 "a291_GB_vehDataTimeout" 290 "a290_GB_pilotAcceptTimeout" 289 "a289_GB_proxTimeout" 288 "a288_GB_evseAbnormalStopReq" 287 "a287_GB_vehConnUnlocked" 286 "a286_GB_evseConnUnlocked" 285 "a285_GB_proxDisconnected" 284 "a284_GB_pcbTempHiFoldBk" 283 "a283_GB_posTempHiFoldBk" 282 "a282_GB_negTempHiFoldBk" 281 "a281_GB_evseOutOfService" 280 "a280_GB_retryLimitExceeded" 279 "a279_GB_evseOverCurrent" 278 "a278_GB_timeoutCCS" 277 "a277_GB_posToPcbDeltaLo" 276 "a276_GB_negToPcbDeltaLo" 275 "a275_GB_posToPcbDeltaHi" 274 "a274_GB_negToPcbDeltaHi" 273 "a273_GB_negToPosDeltaLo" 272 "a272_GB_negToPosDeltaHi" 271 "a271_GB_timeoutCRO" 270 "a270_GB_timeoutCML" 269 "a269_GB_timeoutCRM" 268 "a268_GB_pcb_OT" 267 "a267_GB_posPin_OT" 266 "a266_GB_negPin_OT" 265 "a265_GB_bmsIncompatible" 264 "a264_GB_timeoutCHM" 263 "a263_GB_hwProxTrip" 262 "a262_GB_evseRxBufOvf" 261 "a261_GB_evseTxBufOvf" 260 "a260_GB_vehRxBufOvf" 259 "a259_GB_vehTxBufOvf" 258 "a258_GB_evseMia" 257 "a257_GB_bmsMia" 193 "a193_FCAlertPlaceholder" 187 "a187_CA_evseConLockTimeout" 186 "a186_CA_fcContOpenTimeout" 185 "a185_CA_vehReadyDeasserted" 184 "a184_CA_evseBatMalfunc" 183 "a183_CA_evseBatIncompat" 182 "a182_CA_evseChrMalfunc" 181 "a181_CA_vRegBrownout" 180 "a180_CA_chargingProblem" 179 "a179_CA_startupProblem" 178 "a178_CA_evseStartTimeout" 177 "a177_CA_bmsCtrCloseTimeout" 176 "a176_CA_chargingBusTimeout" 175 "a175_CA_evseIsoTestTimeout" 174 "a174_CA_vehReadyTimeout" 173 "a173_CA_evseDataTimeout" 172 "a172_CA_ss2LowTimeout" 171 "a171_CA_vehConLockTimeout" 170 "a170_CA_vehDataTimeout" 169 "a169_CA_pilotAcceptTimeout" 168 "a168_CA_proxTimeout" 167 "a167_CA_isoVoltageLow" 166 "a166_CA_vehConnUnlocked" 165 "a165_CA_evseConnUnlocked" 164 "a164_CA_proxDisconnected" 163 "a163_CA_pcbTempHiFoldBk" 162 "a162_CA_evseTempHiFoldBk" 161 "a161_CA_vehTempHiFoldBk" 160 "a160_CA_ss2Deasserted" 159 "a159_CA_wdtExpired" 158 "a158_CA_evseOverCurrent" 157 "a157_CA_unused" 156 "a156_CA_flybackRunTimeout" 155 "a155_CA_evseToPcbDeltaLo" 154 "a154_CA_vehToPcbDeltaLo" 153 "a153_CA_evseToPcbDeltaHi" 152 "a152_CA_vehToPcbDeltaHi" 151 "a151_CA_vehToEvseDeltaLo" 150 "a150_CA_vehToEvseDeltaHi" 149 "a149_CA_pcb_UT" 148 "a148_CA_evseConn_UT" 147 "a147_CA_vehConn_UT" 146 "a146_CA_flybackBusLoadHi" 145 "a145_CA_flybackDataStale" 144 "a144_CA_flybackUnstable" 143 "a143_CA_pcb_OT" 142 "a142_CA_evseConn_OT" 141 "a141_CA_vehConn_OT" 140 "a140_CA_bmsIncompatible" 139 "a139_CA_ss2NotLow" 138 "a138_CA_hwProxTrip" 137 "a137_CA_evseRxBufOvf" 136 "a136_CA_evseTxBufOvf" 135 "a135_CA_vehRxBufOvf" 134 "a134_CA_vehTxBufOvf" 133 "a133_CA_evseMia" 132 "a132_CA_bmsMia" 131 "a131_CA_flyback_HW_OV" 130 "a130_CA_flyback_SW_OV" 129 "a129_CA_flyback_HW_OC" 0 "ALERT_DO_NOT_USE_ZERO" ;
VAL_ 1322 FC_alertType 1 "FAULT" 0 "WARNING" ;
VAL_ 1117 FC_evseBillingDataSelect 1 "1" 0 "0" ;
VAL_ 1334 FC_evseBilling2DataSelect 0 "FC_EVSEBILLING2_DATASELECT_0" ;
VAL_ 1334 FC_evseBillingEnergyHighRes 16777215 "SNA" ;
VAL_ 1310 FC_infoIndex 255 "END_FC" 27 "PART_NUM_3" 26 "PART_NUM_2" 25 "PART_NUM_1" 22 "VARIANT_CRC_FC" 20 "UDS_PROTOCOL_BOOTCRC_FC" 19 "VERSION_DEPRECATED_FC" 18 "BOOTLOADER_GITHASH_FC" 17 "APP_GITHASH_FC" 16 "SUBCOMPONENT_FC" 15 "BOOTLOADER_CRC_FC" 14 "BOOTLOADER_SVN_FC" 13 "APP_CRC_FC" 11 "PCBAID_ASSYID_USAGEID_FC" 10 "BUILD_HWID_COMPONENTID_FC" 9 "DEPRECATED_9_FC" 8 "DEPRECATED_8_FC" 7 "DEPRECATED_7_FC" 6 "DEPRECATED_6_FC" 5 "DEPRECATED_5_FC" 4 "DEPRECATED_4_FC" 3 "DEPRECATED_3_FC" 2 "DEPRECATED_2_FC" 1 "DEPRECATED_1_FC" 0 "DEPRECATED_0_FC" ;
VAL_ 1310 FC_infoBuildType 4 "INFO_MFG_BUILD_FC" 3 "INFO_TRACEABLE_CI_BUILD_FC" 2 "INFO_LOCAL_BUILD_FC" 1 "INFO_PLATFORM_BUILD_FC" 0 "INFO_UNKNOWN_BUILD_FC" ;
VAL_ 580 FC_powerLimit 8191 "SNA" ;
VAL_ 580 FC_currentLimit 8191 "SNA" ;
VAL_ 580 FC_maxVoltageLimit 8191 "SNA" ;
VAL_ 580 FC_minVoltageLimit 8191 "SNA" ;
VAL_ 702 FC_powerLimit_value -32768 "SNA" ;
VAL_ 702 FC_currentLimit_value -32768 "SNA" ;
VAL_ 702 FC_minVoltageLimit_value -32768 "SNA" ;
VAL_ 1345 FC_maxPowerLimit 8191 "SNA" ;
VAL_ 1345 FC_maxCurrentLimit 8191 "SNA" ;
VAL_ 1300 FC_serialDataSelect 2 "Mux2" 1 "Mux1" 0 "Mux0" ;
VAL_ 532 FC_statusCode 15 "FC_STATUS_NODATA" 14 "FC_STATUS_MALFUNCTION" 13 "FC_STATUS_NOTCOMPATIBLE" 7 "FC_STATUS_POST_OUT_OF_SERVICE" 6 "FC_STATUS_EXT_ISOACTIVE" 5 "FC_STATUS_INT_ISOACTIVE" 4 "FC_STATUS_DEPRECATED_4" 3 "FC_STATUS_DEPRECATED_3" 2 "FC_STATUS_UPDATE_IN_PROGRESS" 1 "FC_STATUS_READY" 0 "FC_STATUS_NOTREADY_SNA" ;
VAL_ 532 FC_type 7 "FC_TYPE_SNA" 6 "FC_TYPE_OTHER" 5 "FC_TYPE_MC_EVSE" 4 "FC_TYPE_COMBO" 3 "FC_TYPE_CC_EVSE" 2 "FC_TYPE_GB" 1 "FC_TYPE_CHADEMO" 0 "FC_TYPE_SUPERCHARGER" ;
VAL_ 532 FC_postID 3 "FC_POST_ID_SNA" 2 "FC_POST_ID_2" 1 "FC_POST_SLAVE" 0 "FC_POST_MASTER" ;
VAL_ 533 FC_externalIsolationResistance 255 "SNA" ;
VAL_ 535 FC_status3DataSelect 1 "Mux1" 0 "Mux0" ;
VAL_ 535 FC_class 2 "FC_CLASS_URBANCHARGER" 1 "FC_CLASS_SUPERCHARGER" 0 "FC_CLASS_SNA" ;
VAL_ 535 FC_brand 1 "TESLA" 0 "SNA" ;
VAL_ 535 FC_coolingType 3 "FC_COOLING_TYPE_IMMERSION" 2 "FC_COOLING_TYPE_CONVECTION" 1 "FC_COOLING_TYPE_LIQUID" 0 "FC_COOLING_TYPE_SNA" ;
VAL_ 535 FC_uiStopType 2 "FC_UI_STOP_TYPE_MOMENTARY" 1 "FC_UI_STOP_TYPE_TOGGLE" 0 "FC_UI_STOP_TYPE_SNA" ;
VAL_ 535 FC_generation 0 "GENERATION_SNA" ;
